VERSION ""

NS_ :

BS_:

BU_: Turbocharger OnBoardDataLogger OffBoardDiagnosticTool2 OffBoardDiagnosticTool1 FileServer ParkingBrakeController SeatControl2 FanDriveController SteeringColumnUnit CommunicationUnitRadio CommunicationUnitSatellite CommunicationUnitCellular PropulsionBatteryCharger ChassisController2 ChassisController1 EngineValveControl AuxiliaryHeater2 AuxiliaryHeater1 ClutchUnit RampControl InformationSystem1 SuspensionSystemController2 OilSensor VehicleDynamicStability ExhaustEmissionController TransmissionDisplay2 TransmissionDisplay1 ClimateControl2 WaterPumpController RearAxleSteeringController LightingOperatorControl SeatController1 IgnitionController2 IgnitionController1 TirePressureController CabController2 CabController1 PneumaticSystemController SuspensionSystemController1 HydraulicPumpController EnduranceBrakingSystem RetarderExhaustEngine2 OnBoardDiagnosticUnit HeadwayController RetarderExhaustEngine1 CabDisplay1 ManagementComputer VirtualTerminal OffVehicleGateway PowerTakeOffFront HitchControl AuxiliaryValveControl BodyController TractorTrailerBridge1 StarterSystem ElectricalSystem VehicleSecurity VehicleNavigation AerodynamicControl ElectricalChargingSystem ClimateControl1 TripRecorder InstrumentCluster SuspensionDriveAxle2 SuspensionDriveAxle1 SuspensionSteerAxle SteeringController FuelSystem CruiseControl RetarderDriveline RetarderEngine BrakesDriveAxle2 BrakesDriveAxle1 BrakesSystemController BrakesSteerAxle AxleDrive2 AxleDrive1 AxleSteering PowerTakeOff ShiftConsoleSecondary ShiftConsolePrimary Transmission2 Transmission1 Engine2 Engine1

BO_ 2566844695 K_CCVS2: 8 Vector__XXX
 SG_ ParkBrakeReleaseInhibitRq : 6|2@1+ (1,0) [0|3] "" Vector__XXX
 SG_ PTOGovernorState : 48|5@1+ (1,0) [0|31] "" Vector__XXX
 SG_ EngShutdownOverrideSwitch : 62|2@1+ (1,0) [0|3] "" Vector__XXX
 SG_ EngTestModeSwitch : 60|2@1+ (1,0) [0|3] "" Vector__XXX
 SG_ EngIdleDecrementSwitch : 58|2@1+ (1,0) [0|3] "" Vector__XXX
 SG_ EngIdleIncrementSwitch : 56|2@1+ (1,0) [0|3] "" Vector__XXX
 SG_ CruiseCtrlStates : 53|3@1+ (1,0) [0|7] "" Vector__XXX
 SG_ CruiseCtrlSetSpeed : 40|8@1+ (1,0) [0|250] "km/h" Vector__XXX
 SG_ CruiseCtrlAccelerateSwitch : 38|2@1+ (1,0) [0|3] "" Vector__XXX
 SG_ CruiseCtrlResumeSwitch : 36|2@1+ (1,0) [0|3] "" Vector__XXX
 SG_ CruiseCtrlCoastSwitch : 34|2@1+ (1,0) [0|3] "" Vector__XXX
 SG_ CruiseCtrlSetSwitch : 32|2@1+ (1,0) [0|3] "" Vector__XXX
 SG_ ClutchSwitch : 30|2@1+ (1,0) [0|3] "" Vector__XXX
 SG_ BrakeSwitch : 28|2@1+ (1,0) [0|3] "" Vector__XXX
 SG_ CruiseCtrlEnableSwitch : 26|2@1+ (1,0) [0|3] "" Vector__XXX
 SG_ CruiseCtrlActive : 24|2@1+ (1,0) [0|3] "" Vector__XXX
 SG_ WheelBasedVehicleSpeed : 8|16@1+ (0.00390625,0) [0|250.996] "km/h" Vector__XXX
 SG_ CruiseCtrlPauseSwitch : 4|2@1+ (1,0) [0|3] "" Vector__XXX
 SG_ ParkingBrakeSwitch : 2|2@1+ (1,0) [0|3] "" Vector__XXX
 SG_ TwoSpeedAxleSwitch : 0|2@1+ (1,0) [0|3] "" Vector__XXX

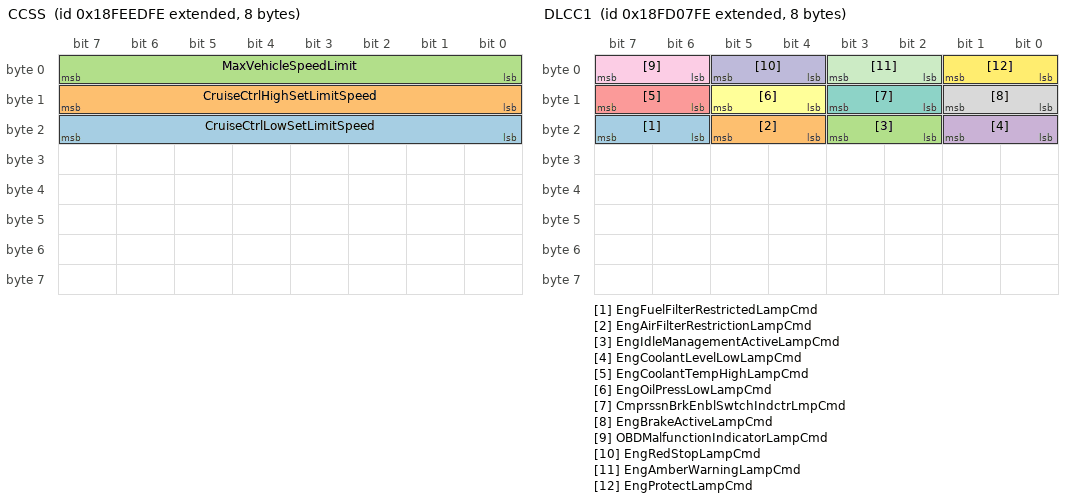
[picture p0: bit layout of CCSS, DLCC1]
BO_ 2566843902 CCSS: 8 Vector__XXX
 SG_ CruiseCtrlLowSetLimitSpeed : 16|8@1+ (1,0) [0|250] "km/h" Vector__XXX
 SG_ CruiseCtrlHighSetLimitSpeed : 8|8@1+ (1,0) [0|250] "km/h" Vector__XXX
 SG_ MaxVehicleSpeedLimit : 0|8@1+ (1,0) [0|250] "km/h" Vector__XXX

BO_ 2566809598 CCC: 8 Vector__XXX
 SG_ AuxHeaterMaxOutputPower : 0|16@1+ (2,0) [0|128510] "W" Vector__XXX

BO_ 2633940222 CBI: 16 Vector__XXX
 SG_ TripServiceBrakeApps : 96|32@1+ (1,0) [0|4227858431] "appl" Vector__XXX
 SG_ TripServiceBrakeDistance : 64|32@1+ (0.125,0) [0|526385151.9] "km" Vector__XXX
 SG_ TripCompressionBrakeDistance : 32|32@1+ (0.125,0) [0|526385151.9] "km" Vector__XXX
 SG_ TotalCompressionBrakeDistance : 0|32@1+ (0.125,0) [0|526385151.9] "km" Vector__XXX

BO_ 2566775294 CACI: 8 Vector__XXX
 SG_ CbA_CRfrgrntCmprssorOutletPress : 0|8@1+ (16,0) [0|4000] "kPa" Vector__XXX

BO_ 2566803710 BT1: 8 Vector__XXX
 SG_ Battery2Temp : 8|8@1+ (1,-40) [-40|210] "deg C" Vector__XXX
 SG_ Battery1Temp : 0|8@1+ (1,-40) [-40|210] "deg C" Vector__XXX

BO_ 2365476881 K_BT1: 8 Vector__XXX
 SG_ Battery2Temp : 8|8@1+ (1,-40) [-40|210] "deg C" Vector__XXX
 SG_ Battery1Temp : 0|8@1+ (1,-40) [-40|210] "deg C" Vector__XXX

BO_ 2566719486 DLCC1: 8 Vector__XXX
 SG_ EngFuelFilterRestrictedLampCmd : 22|2@1+ (1,0) [0|3] "" Vector__XXX
 SG_ EngAirFilterRestrictionLampCmd : 20|2@1+ (1,0) [0|3] "" Vector__XXX
 SG_ EngIdleManagementActiveLampCmd : 18|2@1+ (1,0) [0|3] "" Vector__XXX
 SG_ EngCoolantLevelLowLampCmd : 16|2@1+ (1,0) [0|3] "" Vector__XXX
 SG_ EngCoolantTempHighLampCmd : 14|2@1+ (1,0) [0|3] "" Vector__XXX
 SG_ EngOilPressLowLampCmd : 12|2@1+ (1,0) [0|3] "" Vector__XXX
 SG_ CmprssnBrkEnblSwtchIndctrLmpCmd : 10|2@1+ (1,0) [0|3] "" Vector__XXX
 SG_ EngBrakeActiveLampCmd : 8|2@1+ (1,0) [0|3] "" Vector__XXX
 SG_ OBDMalfunctionIndicatorLampCmd : 6|2@1+ (1,0) [0|3] "" Vector__XXX
 SG_ EngRedStopLampCmd : 4|2@1+ (1,0) [0|3] "" Vector__XXX
 SG_ EngAmberWarningLampCmd : 2|2@1+ (1,0) [0|3] "" Vector__XXX
 SG_ EngProtectLampCmd : 0|2@1+ (1,0) [0|3] "" Vector__XXX

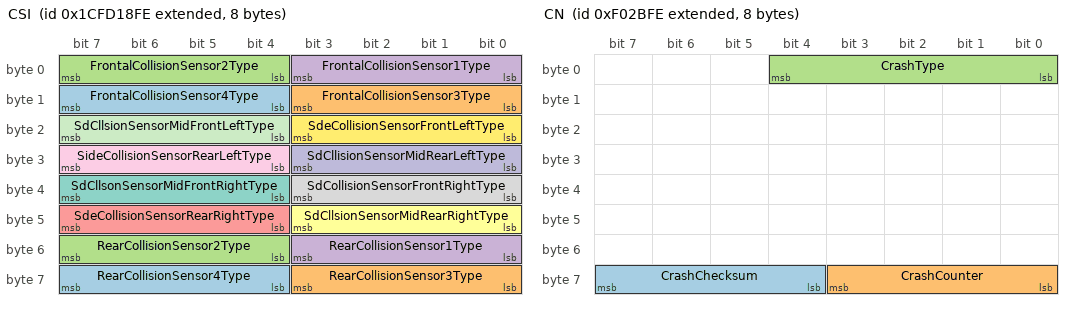
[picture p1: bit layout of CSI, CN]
BO_ 2633832702 CSI: 8 Vector__XXX
 SG_ RearCollisionSensor4Type : 60|4@1+ (1,0) [0|15] "" Vector__XXX
 SG_ RearCollisionSensor3Type : 56|4@1+ (1,0) [0|15] "" Vector__XXX
 SG_ RearCollisionSensor2Type : 52|4@1+ (1,0) [0|15] "" Vector__XXX
 SG_ RearCollisionSensor1Type : 48|4@1+ (1,0) [0|15] "" Vector__XXX
 SG_ SdeCollisionSensorRearRightType : 44|4@1+ (1,0) [0|15] "" Vector__XXX
 SG_ SdCllsionSensorMidRearRightType : 40|4@1+ (1,0) [0|15] "" Vector__XXX
 SG_ SdCllsonSensorMidFrontRightType : 36|4@1+ (1,0) [0|15] "" Vector__XXX
 SG_ SdCollisionSensorFrontRightType : 32|4@1+ (1,0) [0|15] "" Vector__XXX
 SG_ SideCollisionSensorRearLeftType : 28|4@1+ (1,0) [0|15] "" Vector__XXX
 SG_ SdCllisionSensorMidRearLeftType : 24|4@1+ (1,0) [0|15] "" Vector__XXX
 SG_ SdCllsionSensorMidFrontLeftType : 20|4@1+ (1,0) [0|15] "" Vector__XXX
 SG_ SdeCollisionSensorFrontLeftType : 16|4@1+ (1,0) [0|15] "" Vector__XXX
 SG_ FrontalCollisionSensor4Type : 12|4@1+ (1,0) [0|15] "" Vector__XXX
 SG_ FrontalCollisionSensor3Type : 8|4@1+ (1,0) [0|15] "" Vector__XXX
 SG_ FrontalCollisionSensor2Type : 4|4@1+ (1,0) [0|15] "" Vector__XXX
 SG_ FrontalCollisionSensor1Type : 0|4@1+ (1,0) [0|15] "" Vector__XXX

BO_ 2163223550 CN: 8 Vector__XXX
 SG_ CrashChecksum : 60|4@1+ (1,0) [0|15] "" Vector__XXX
 SG_ CrashCounter : 56|4@1+ (1,0) [0|15] "" Vector__XXX
 SG_ CrashType : 0|5@1+ (5,0) [0|0] "" Vector__XXX

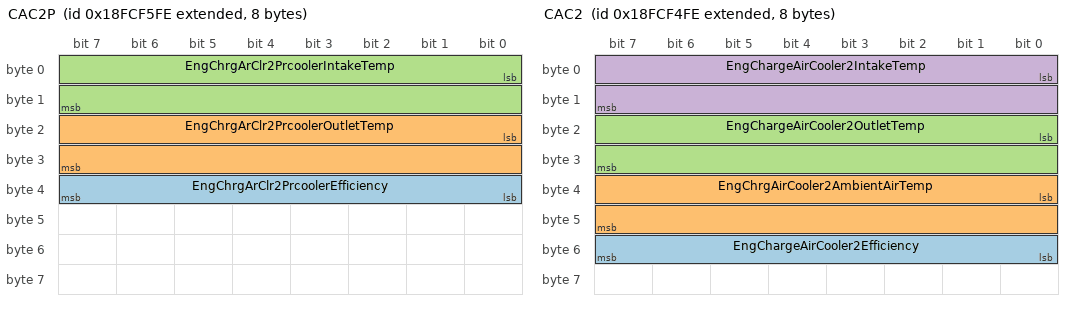
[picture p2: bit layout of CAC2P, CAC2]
BO_ 2566714878 CAC2P: 8 Vector__XXX
 SG_ EngChrgArClr2PrcoolerEfficiency : 32|8@1+ (0.4,0) [0|100] "%" Vector__XXX
 SG_ EngChrgArClr2PrcoolerOutletTemp : 16|16@1+ (0.03125,-273) [-273|1734.96875] "deg C" Vector__XXX
 SG_ EngChrgArClr2PrcoolerIntakeTemp : 0|16@1+ (0.03125,-273) [-273|1734.96875] "deg C" Vector__XXX

BO_ 2566714622 CAC2: 8 Vector__XXX
 SG_ EngChargeAirCooler2Efficiency : 48|8@1+ (0.4,0) [0|100] "%" Vector__XXX
 SG_ EngChrgAirCooler2AmbientAirTemp : 32|16@1+ (0.03125,-273) [-273|1734.96875] "deg C" Vector__XXX
 SG_ EngChargeAirCooler2OutletTemp : 16|16@1+ (0.03125,-273) [-273|1734.96875] "deg C" Vector__XXX
 SG_ EngChargeAirCooler2IntakeTemp : 0|16@1+ (0.03125,-273) [-273|1734.96875] "deg C" Vector__XXX

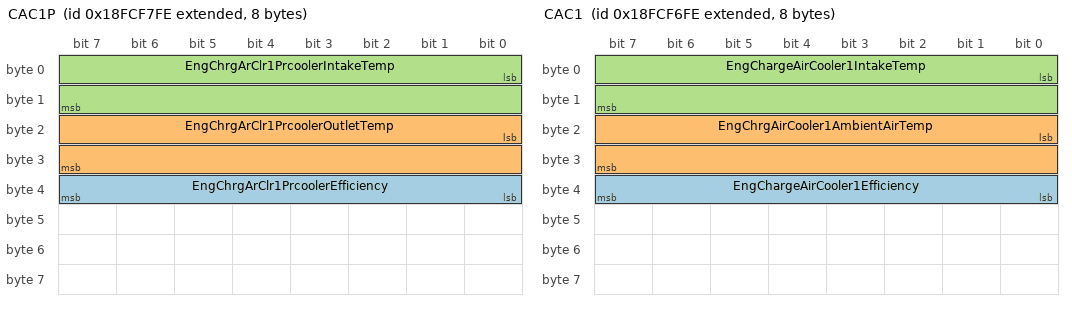
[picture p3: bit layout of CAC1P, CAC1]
BO_ 2566715390 CAC1P: 8 Vector__XXX
 SG_ EngChrgArClr1PrcoolerEfficiency : 32|8@1+ (0.4,0) [0|100] "%" Vector__XXX
 SG_ EngChrgArClr1PrcoolerOutletTemp : 16|16@1+ (0.03125,-273) [-273|1734.96875] "deg C" Vector__XXX
 SG_ EngChrgArClr1PrcoolerIntakeTemp : 0|16@1+ (0.03125,-273) [-273|1734.96875] "deg C" Vector__XXX

BO_ 2566715134 CAC1: 8 Vector__XXX
 SG_ EngChargeAirCooler1Efficiency : 32|8@1+ (0.4,0) [0|100] "%" Vector__XXX
 SG_ EngChrgAirCooler1AmbientAirTemp : 16|16@1+ (0.03125,-273) [-273|1734.96875] "deg C" Vector__XXX
 SG_ EngChargeAirCooler1IntakeTemp : 0|16@1+ (0.03125,-273) [-273|1734.96875] "deg C" Vector__XXX

BO_ 2365400830 BJM9: 8 Vector__XXX
 SG_ Joystick9Button9PressedStatus : 62|2@1+ (1,0) [0|3] "" Vector__XXX
 SG_ Joystick9Button10PressedStatus : 60|2@1+ (1,0) [0|3] "" Vector__XXX
 SG_ Joystick9Button11PressedStatus : 58|2@1+ (1,0) [0|3] "" Vector__XXX
 SG_ Joystick9Button12PressedStatus : 56|2@1+ (1,0) [0|3] "" Vector__XXX
 SG_ Joystick9Button5PressedStatus : 54|2@1+ (1,0) [0|3] "" Vector__XXX
 SG_ Joystick9Button6PressedStatus : 52|2@1+ (1,0) [0|3] "" Vector__XXX
 SG_ Joystick9Button7PressedStatus : 50|2@1+ (1,0) [0|3] "" Vector__XXX
 SG_ Joystick9Button8PressedStatus : 48|2@1+ (1,0) [0|3] "" Vector__XXX
 SG_ Joystick9Button1PressedStatus : 46|2@1+ (1,0) [0|3] "" Vector__XXX
 SG_ Joystick9Button2PressedStatus : 44|2@1+ (1,0) [0|3] "" Vector__XXX
 SG_ Joystick9Button3PressedStatus : 42|2@1+ (1,0) [0|3] "" Vector__XXX
 SG_ Joystick9Button4PressedStatus : 40|2@1+ (1,0) [0|3] "" Vector__XXX
 SG_ Joystick9XAxisDetentPosStatus : 38|2@1+ (1,0) [0|3] "" Vector__XXX
 SG_ Joystick9YAxisDetentPosStatus : 36|2@1+ (1,0) [0|3] "" Vector__XXX
 SG_ Joystick9YAxisPos : 22|10@1+ (0.1,0) [0|102] "%" Vector__XXX
 SG_ Jystck9YAxsLvrFrwrdPstvPsStatus : 20|2@1+ (1,0) [0|3] "" Vector__XXX
 SG_ Jystck9YAxsLvrBckNgtvePosStatus : 18|2@1+ (1,0) [0|3] "" Vector__XXX
 SG_ Joystick9YAxisNeutralPosStatus : 16|2@1+ (1,0) [0|3] "" Vector__XXX
 SG_ Joystick9XAxisPos : 6|10@1+ (0.1,0) [0|102] "%" Vector__XXX
 SG_ Jystck9XAxsLvrRghtPstvPosStatus : 4|2@1+ (1,0) [0|3] "" Vector__XXX
 SG_ Jystck9XAxsLvrLftNgtvePosStatus : 2|2@1+ (1,0) [0|3] "" Vector__XXX
 SG_ Joystick9XAxisNeutralPosStatus : 0|2@1+ (1,0) [0|3] "" Vector__XXX

BO_ 2365401342 BJM8: 8 Vector__XXX
 SG_ Joystick8Button9PressedStatus : 62|2@1+ (1,0) [0|3] "" Vector__XXX
 SG_ Joystick8Button10PressedStatus : 60|2@1+ (1,0) [0|3] "" Vector__XXX
 SG_ Joystick8Button11PressedStatus : 58|2@1+ (1,0) [0|3] "" Vector__XXX
 SG_ Joystick8Button12PressedStatus : 56|2@1+ (1,0) [0|3] "" Vector__XXX
 SG_ Joystick8Button5PressedStatus : 54|2@1+ (1,0) [0|3] "" Vector__XXX
 SG_ Joystick8Button6PressedStatus : 52|2@1+ (1,0) [0|3] "" Vector__XXX
 SG_ Joystick8Button7PressedStatus : 50|2@1+ (1,0) [0|3] "" Vector__XXX
 SG_ Joystick8Button8PressedStatus : 48|2@1+ (1,0) [0|3] "" Vector__XXX
 SG_ Joystick8Button1PressedStatus : 46|2@1+ (1,0) [0|3] "" Vector__XXX
 SG_ Joystick8Button2PressedStatus : 44|2@1+ (1,0) [0|3] "" Vector__XXX
 SG_ Joystick8Button3PressedStatus : 42|2@1+ (1,0) [0|3] "" Vector__XXX
 SG_ Joystick8Button4PressedStatus : 40|2@1+ (1,0) [0|3] "" Vector__XXX
 SG_ Joystick8XAxisDetentPosStatus : 38|2@1+ (1,0) [0|3] "" Vector__XXX
 SG_ Joystick8YAxisDetentPosStatus : 36|2@1+ (1,0) [0|3] "" Vector__XXX
 SG_ Joystick8YAxisPos : 22|10@1+ (0.1,0) [0|102] "%" Vector__XXX
 SG_ Jystck8YAxsLvrFrwrdPstvPsStatus : 20|2@1+ (1,0) [0|3] "" Vector__XXX
 SG_ Jystck8YAxsLvrBckNgtvePosStatus : 18|2@1+ (1,0) [0|3] "" Vector__XXX
 SG_ Joystick8YAxisNeutralPosStatus : 16|2@1+ (1,0) [0|3] "" Vector__XXX
 SG_ Joystick8XAxisPos : 6|10@1+ (0.1,0) [0|102] "%" Vector__XXX
 SG_ Jystck8XAxsLvrRghtPstvPosStatus : 4|2@1+ (1,0) [0|3] "" Vector__XXX
 SG_ Jystck8XAxsLvrLftNgtvePosStatus : 2|2@1+ (1,0) [0|3] "" Vector__XXX
 SG_ Joystick8XAxisNeutralPosStatus : 0|2@1+ (1,0) [0|3] "" Vector__XXX

BO_ 2365401854 BJM7: 8 Vector__XXX
 SG_ Joystick7Button9PressedStatus : 62|2@1+ (1,0) [0|3] "" Vector__XXX
 SG_ Joystick7Button10PressedStatus : 60|2@1+ (1,0) [0|3] "" Vector__XXX
 SG_ Joystick7Button11PressedStatus : 58|2@1+ (1,0) [0|3] "" Vector__XXX
 SG_ Joystick7Button12PressedStatus : 56|2@1+ (1,0) [0|3] "" Vector__XXX
 SG_ Joystick7Button5PressedStatus : 54|2@1+ (1,0) [0|3] "" Vector__XXX
 SG_ Joystick7Button6PressedStatus : 52|2@1+ (1,0) [0|3] "" Vector__XXX
 SG_ Joystick7Button7PressedStatus : 50|2@1+ (1,0) [0|3] "" Vector__XXX
 SG_ Joystick7Button8PressedStatus : 48|2@1+ (1,0) [0|3] "" Vector__XXX
 SG_ Joystick7Button1PressedStatus : 46|2@1+ (1,0) [0|3] "" Vector__XXX
 SG_ Joystick7Button2PressedStatus : 44|2@1+ (1,0) [0|3] "" Vector__XXX
 SG_ Joystick7Button3PressedStatus : 42|2@1+ (1,0) [0|3] "" Vector__XXX
 SG_ Joystick7Button4PressedStatus : 40|2@1+ (1,0) [0|3] "" Vector__XXX
 SG_ Joystick7XAxisDetentPosStatus : 38|2@1+ (1,0) [0|3] "" Vector__XXX
 SG_ Joystick7YAxisDetentPosStatus : 36|2@1+ (1,0) [0|3] "" Vector__XXX
 SG_ Joystick7YAxisPos : 22|10@1+ (0.1,0) [0|102] "%" Vector__XXX
 SG_ Jystck7YAxsLvrFrwrdPstvPsStatus : 20|2@1+ (1,0) [0|3] "" Vector__XXX
 SG_ Jystck7YAxsLvrBckNgtvePosStatus : 18|2@1+ (1,0) [0|3] "" Vector__XXX
 SG_ Joystick7YAxisNeutralPosStatus : 16|2@1+ (1,0) [0|3] "" Vector__XXX
 SG_ Joystick7XAxisPos : 6|10@1+ (0.1,0) [0|102] "%" Vector__XXX
 SG_ Jystck7XAxsLvrRghtPstvPosStatus : 4|2@1+ (1,0) [0|3] "" Vector__XXX
 SG_ Jystck7XAxsLvrLftNgtvePosStatus : 2|2@1+ (1,0) [0|3] "" Vector__XXX
 SG_ Joystick7XAxisNeutralPosStatus : 0|2@1+ (1,0) [0|3] "" Vector__XXX

BO_ 2365402366 BJM6: 8 Vector__XXX
 SG_ Joystick6Button9PressedStatus : 62|2@1+ (1,0) [0|3] "" Vector__XXX
 SG_ Joystick6Button10PressedStatus : 60|2@1+ (1,0) [0|3] "" Vector__XXX
 SG_ Joystick6Button11PressedStatus : 58|2@1+ (1,0) [0|3] "" Vector__XXX
 SG_ Joystick6Button12PressedStatus : 56|2@1+ (1,0) [0|3] "" Vector__XXX
 SG_ Joystick6Button5PressedStatus : 54|2@1+ (1,0) [0|3] "" Vector__XXX
 SG_ Joystick6Button6PressedStatus : 52|2@1+ (1,0) [0|3] "" Vector__XXX
 SG_ Joystick6Button7PressedStatus : 50|2@1+ (1,0) [0|3] "" Vector__XXX
 SG_ Joystick6Button8PressedStatus : 48|2@1+ (1,0) [0|3] "" Vector__XXX
 SG_ Joystick6Button1PressedStatus : 46|2@1+ (1,0) [0|3] "" Vector__XXX
 SG_ Joystick6Button2PressedStatus : 44|2@1+ (1,0) [0|3] "" Vector__XXX
 SG_ Joystick6Button3PressedStatus : 42|2@1+ (1,0) [0|3] "" Vector__XXX
 SG_ Joystick6Button4PressedStatus : 40|2@1+ (1,0) [0|3] "" Vector__XXX
 SG_ Joystick6XAxisDetentPosStatus : 38|2@1+ (1,0) [0|3] "" Vector__XXX
 SG_ Joystick6YAxisDetentPosStatus : 36|2@1+ (1,0) [0|3] "" Vector__XXX
 SG_ Joystick6YAxisPos : 22|10@1+ (0.1,0) [0|102] "%" Vector__XXX
 SG_ Jystck6YAxsLvrFrwrdPstvPsStatus : 20|2@1+ (1,0) [0|3] "" Vector__XXX
 SG_ Jystck6YAxsLvrBckNgtvePosStatus : 18|2@1+ (1,0) [0|3] "" Vector__XXX
 SG_ Joystick6YAxisNeutralPosStatus : 16|2@1+ (1,0) [0|3] "" Vector__XXX
 SG_ Joystick6XAxisPos : 6|10@1+ (0.1,0) [0|102] "%" Vector__XXX
 SG_ Jystck6XAxsLvrRghtPstvPosStatus : 4|2@1+ (1,0) [0|3] "" Vector__XXX
 SG_ Jystck6XAxsLvrLftNgtvePosStatus : 2|2@1+ (1,0) [0|3] "" Vector__XXX
 SG_ Joystick6XAxisNeutralPosStatus : 0|2@1+ (1,0) [0|3] "" Vector__XXX

BO_ 2365402878 BJM5: 8 Vector__XXX
 SG_ Joystick5Button9PressedStatus : 62|2@1+ (1,0) [0|3] "" Vector__XXX
 SG_ Joystick5Button10PressedStatus : 60|2@1+ (1,0) [0|3] "" Vector__XXX
 SG_ Joystick5Button11PressedStatus : 58|2@1+ (1,0) [0|3] "" Vector__XXX
 SG_ Joystick5Button12PressedStatus : 56|2@1+ (1,0) [0|3] "" Vector__XXX
 SG_ Joystick5Button5PressedStatus : 54|2@1+ (1,0) [0|3] "" Vector__XXX
 SG_ Joystick5Button6PressedStatus : 52|2@1+ (1,0) [0|3] "" Vector__XXX
 SG_ Joystick5Button7PressedStatus : 50|2@1+ (1,0) [0|3] "" Vector__XXX
 SG_ Joystick5Button8PressedStatus : 48|2@1+ (1,0) [0|3] "" Vector__XXX
 SG_ Joystick5Button1PressedStatus : 46|2@1+ (1,0) [0|3] "" Vector__XXX
 SG_ Joystick5Button2PressedStatus : 44|2@1+ (1,0) [0|3] "" Vector__XXX
 SG_ Joystick5Button3PressedStatus : 42|2@1+ (1,0) [0|3] "" Vector__XXX
 SG_ Joystick5Button4PressedStatus : 40|2@1+ (1,0) [0|3] "" Vector__XXX
 SG_ Joystick5XAxisDetentPosStatus : 38|2@1+ (1,0) [0|3] "" Vector__XXX
 SG_ Joystick5YAxisDetentPosStatus : 36|2@1+ (1,0) [0|3] "" Vector__XXX
 SG_ Joystick5YAxisPos : 22|10@1+ (0.1,0) [0|102] "%" Vector__XXX
 SG_ Jystck5YAxsLvrFrwrdPstvPsStatus : 20|2@1+ (1,0) [0|3] "" Vector__XXX
 SG_ Jystck5YAxsLvrBckNgtvePosStatus : 18|2@1+ (1,0) [0|3] "" Vector__XXX
 SG_ Joystick5YAxisNeutralPosStatus : 16|2@1+ (1,0) [0|3] "" Vector__XXX
 SG_ Joystick5XAxisPos : 6|10@1+ (0.1,0) [0|102] "%" Vector__XXX
 SG_ Jystck5XAxsLvrRghtPstvPosStatus : 4|2@1+ (1,0) [0|3] "" Vector__XXX
 SG_ Jystck5XAxsLvrLftNgtvePosStatus : 2|2@1+ (1,0) [0|3] "" Vector__XXX
 SG_ Joystick5XAxisNeutralPosStatus : 0|2@1+ (1,0) [0|3] "" Vector__XXX

BO_ 2365403390 BJM4: 8 Vector__XXX
 SG_ Joystick4Button9PressedStatus : 62|2@1+ (1,0) [0|3] "" Vector__XXX
 SG_ Joystick4Button10PressedStatus : 60|2@1+ (1,0) [0|3] "" Vector__XXX
 SG_ Joystick4Button11PressedStatus : 58|2@1+ (1,0) [0|3] "" Vector__XXX
 SG_ Joystick4Button12PressedStatus : 56|2@1+ (1,0) [0|3] "" Vector__XXX
 SG_ Joystick4Button5PressedStatus : 54|2@1+ (1,0) [0|3] "" Vector__XXX
 SG_ Joystick4Button6PressedStatus : 52|2@1+ (1,0) [0|3] "" Vector__XXX
 SG_ Joystick4Button7PressedStatus : 50|2@1+ (1,0) [0|3] "" Vector__XXX
 SG_ Joystick4Button8PressedStatus : 48|2@1+ (1,0) [0|3] "" Vector__XXX
 SG_ Joystick4Button1PressedStatus : 46|2@1+ (1,0) [0|3] "" Vector__XXX
 SG_ Joystick4Button2PressedStatus : 44|2@1+ (1,0) [0|3] "" Vector__XXX
 SG_ Joystick4Button3PressedStatus : 42|2@1+ (1,0) [0|3] "" Vector__XXX
 SG_ Joystick4Button4PressedStatus : 40|2@1+ (1,0) [0|3] "" Vector__XXX
 SG_ Joystick4XAxisDetentPosStatus : 38|2@1+ (1,0) [0|3] "" Vector__XXX
 SG_ Joystick4YAxisDetentPosStatus : 36|2@1+ (1,0) [0|3] "" Vector__XXX
 SG_ Joystick4YAxisPos : 22|10@1+ (0.1,0) [0|102] "%" Vector__XXX
 SG_ Jystck4YAxsLvrFrwrdPstvPsStatus : 20|2@1+ (1,0) [0|3] "" Vector__XXX
 SG_ Jystck4YAxsLvrBckNgtvePosStatus : 18|2@1+ (1,0) [0|3] "" Vector__XXX
 SG_ Joystick4YAxisNeutralPosStatus : 16|2@1+ (1,0) [0|3] "" Vector__XXX
 SG_ Joystick4XAxisPos : 6|10@1+ (0.1,0) [0|102] "%" Vector__XXX
 SG_ Jystck4XAxsLvrRghtPstvPosStatus : 4|2@1+ (1,0) [0|3] "" Vector__XXX
 SG_ Jystck4XAxsLvrLftNgtvePosStatus : 2|2@1+ (1,0) [0|3] "" Vector__XXX
 SG_ Joystick4XAxisNeutralPosStatus : 0|2@1+ (1,0) [0|3] "" Vector__XXX

BO_ 2365400318 BJM10: 8 Vector__XXX
 SG_ Joystick10Button9PressedStatus : 62|2@1+ (1,0) [0|3] "" Vector__XXX
 SG_ Joystick10Button10PressedStatus : 60|2@1+ (1,0) [0|3] "" Vector__XXX
 SG_ Joystick10Button11PressedStatus : 58|2@1+ (1,0) [0|3] "" Vector__XXX
 SG_ Joystick10Button12PressedStatus : 56|2@1+ (1,0) [0|3] "" Vector__XXX
 SG_ Joystick10Button5PressedStatus : 54|2@1+ (1,0) [0|3] "" Vector__XXX
 SG_ Joystick10Button6PressedStatus : 52|2@1+ (1,0) [0|3] "" Vector__XXX
 SG_ Joystick10Button7PressedStatus : 50|2@1+ (1,0) [0|3] "" Vector__XXX
 SG_ Joystick10Button8PressedStatus : 48|2@1+ (1,0) [0|3] "" Vector__XXX
 SG_ Joystick10Button1PressedStatus : 46|2@1+ (1,0) [0|3] "" Vector__XXX
 SG_ Joystick10Button2PressedStatus : 44|2@1+ (1,0) [0|3] "" Vector__XXX
 SG_ Joystick10Button3PressedStatus : 42|2@1+ (1,0) [0|3] "" Vector__XXX
 SG_ Joystick10Button4PressedStatus : 40|2@1+ (1,0) [0|3] "" Vector__XXX
 SG_ Joystick10XAxisDetentPosStatus : 38|2@1+ (1,0) [0|3] "" Vector__XXX
 SG_ Joystick10YAxisDetentPosStatus : 36|2@1+ (1,0) [0|3] "" Vector__XXX
 SG_ Joystick10YAxisPos : 22|10@1+ (0.1,0) [0|102] "%" Vector__XXX
 SG_ Jystck10YAxsLvrFrwrdPstvPsSttus : 20|2@1+ (1,0) [0|3] "" Vector__XXX
 SG_ Jystck10YAxsLvrBckNgtvPosStatus : 18|2@1+ (1,0) [0|3] "" Vector__XXX
 SG_ Joystick10YAxisNeutralPosStatus : 16|2@1+ (1,0) [0|3] "" Vector__XXX
 SG_ Joystick10XAxisPos : 6|10@1+ (0.1,0) [0|102] "%" Vector__XXX
 SG_ Jystck10XAxsLvrRghtPstvPsStatus : 4|2@1+ (1,0) [0|3] "" Vector__XXX
 SG_ Jystck10XAxsLvrLftNgtvPosStatus : 2|2@1+ (1,0) [0|3] "" Vector__XXX
 SG_ Joystick10XAxisNeutralPosStatus : 0|2@1+ (1,0) [0|3] "" Vector__XXX

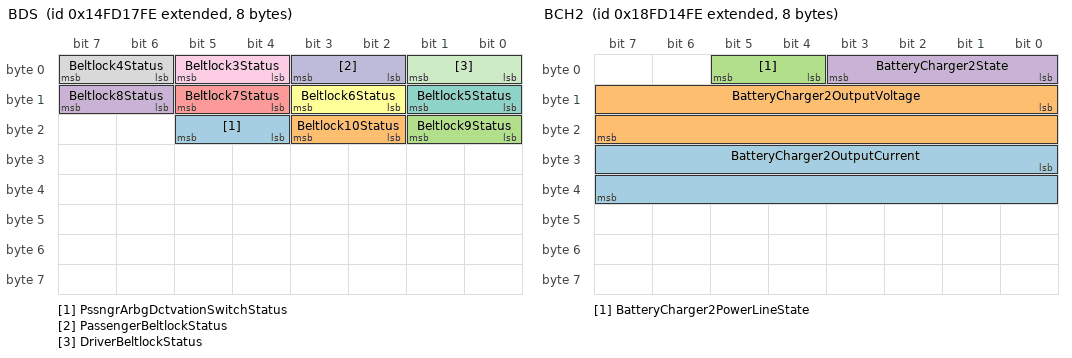
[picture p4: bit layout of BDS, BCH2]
BO_ 2499614718 BDS: 8 Vector__XXX
 SG_ PssngrArbgDctvationSwitchStatus : 20|2@1+ (1,0) [0|3] "" Vector__XXX
 SG_ Beltlock10Status : 18|2@1+ (1,0) [0|3] "" Vector__XXX
 SG_ Beltlock9Status : 16|2@1+ (1,0) [0|3] "" Vector__XXX
 SG_ Beltlock8Status : 14|2@1+ (1,0) [0|3] "" Vector__XXX
 SG_ Beltlock7Status : 12|2@1+ (1,0) [0|3] "" Vector__XXX
 SG_ Beltlock6Status : 10|2@1+ (1,0) [0|3] "" Vector__XXX
 SG_ Beltlock5Status : 8|2@1+ (1,0) [0|3] "" Vector__XXX
 SG_ Beltlock4Status : 6|2@1+ (1,0) [0|3] "" Vector__XXX
 SG_ Beltlock3Status : 4|2@1+ (1,0) [0|3] "" Vector__XXX
 SG_ PassengerBeltlockStatus : 2|2@1+ (1,0) [0|3] "" Vector__XXX
 SG_ DriverBeltlockStatus : 0|2@1+ (1,0) [0|3] "" Vector__XXX

BO_ 2566722814 BCH2: 8 Vector__XXX
 SG_ BatteryCharger2OutputCurrent : 24|16@1+ (0.05,-1600) [-1600|1612.75] "A" Vector__XXX
 SG_ BatteryCharger2OutputVoltage : 8|16@1+ (0.05,0) [0|3212.75] "V" Vector__XXX
 SG_ BatteryCharger2PowerLineState : 4|2@1+ (1,0) [0|3] "" Vector__XXX
 SG_ BatteryCharger2State : 0|4@1+ (1,0) [0|15] "" Vector__XXX

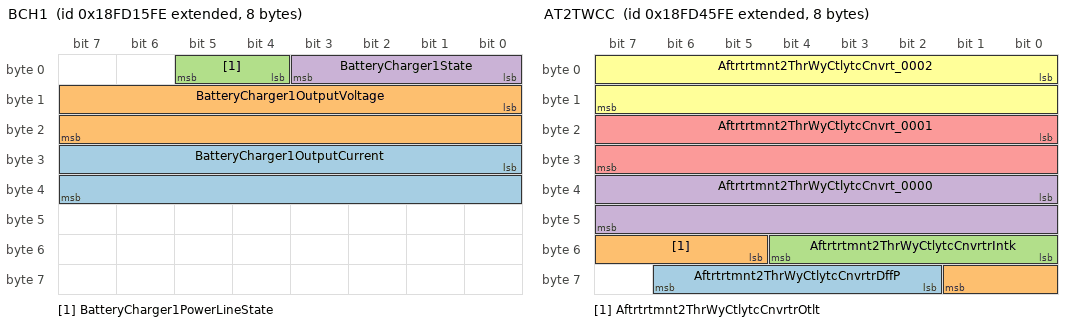
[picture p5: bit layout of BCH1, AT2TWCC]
BO_ 2566723070 BCH1: 8 Vector__XXX
 SG_ BatteryCharger1OutputCurrent : 24|16@1+ (0.05,-1600) [-1600|1612.75] "A" Vector__XXX
 SG_ BatteryCharger1OutputVoltage : 8|16@1+ (0.05,0) [0|3212.75] "V" Vector__XXX
 SG_ BatteryCharger1PowerLineState : 4|2@1+ (1,0) [0|3] "" Vector__XXX
 SG_ BatteryCharger1State : 0|4@1+ (1,0) [0|15] "" Vector__XXX

BO_ 2566725118 ATDT2: 8 Vector__XXX
 SG_ Aftrtrtmnt2ThrWyCtlystDffGsTemp : 16|16@1+ (0.03125,-273) [-273|1734.96875] "deg C" Vector__XXX
 SG_ Aftrtrtmnt1ThrWyCtlystDffGsTemp : 0|16@1+ (0.03125,-273) [-273|1734.96875] "deg C" Vector__XXX

BO_ 2566725374 ATDT1: 8 Vector__XXX
 SG_ Aftrtrtmnt2GsOxdtnCtlystDffGsTmp : 16|16@1+ (0.03125,-273) [-273|1734.96875] "deg C" Vector__XXX
 SG_ Aftrtrtmnt1GsOxdtnCtlystDffGsTmp : 0|16@1+ (0.03125,-273) [-273|1734.96875] "deg C" Vector__XXX

BO_ 2566712830 AT2WUDOC: 8 Vector__XXX
 SG_ Aftrtrtmnt2WrmUpDslOxdtnCtlystOt : 16|16@1+ (0.03125,-273) [-273|1734.96875] "deg C" Vector__XXX
 SG_ Aftrtrtmnt2WrmUpDslOxdtnCtlystIn : 0|16@1+ (0.03125,-273) [-273|1734.96875] "deg C" Vector__XXX

BO_ 2566735358 AT2TWCC: 8 Vector__XXX
 SG_ Aftrtrtmnt2ThrWyCtlytcCnvrtrDffP : 58|5@1+ (1,0) [0|31] "" Vector__XXX
 SG_ Aftrtrtmnt2ThrWyCtlytcCnvrtrOtlt : 53|5@1+ (1,0) [0|31] "" Vector__XXX
 SG_ Aftrtrtmnt2ThrWyCtlytcCnvrtrIntk : 48|5@1+ (1,0) [0|31] "" Vector__XXX
 SG_ Aftrtrtmnt2ThrWyCtlytcCnvrt_0000 : 32|16@1+ (0.1,0) [0|6425.5] "kPa" Vector__XXX
 SG_ Aftrtrtmnt2ThrWyCtlytcCnvrt_0001 : 16|16@1+ (0.03125,-273) [-273|1734.96875] "deg C" Vector__XXX
 SG_ Aftrtrtmnt2ThrWyCtlytcCnvrt_0002 : 0|16@1+ (0.03125,-273) [-273|1734.96875] "deg C" Vector__XXX

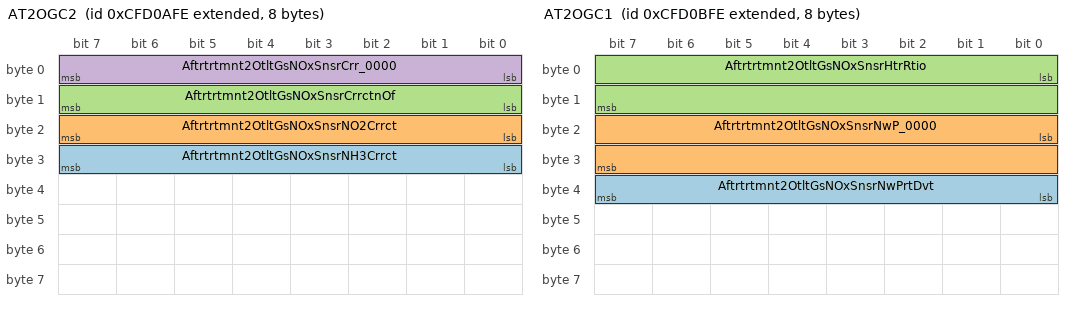
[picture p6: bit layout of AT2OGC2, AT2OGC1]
BO_ 2365393662 AT2OGC2: 8 Vector__XXX
 SG_ Aftrtrtmnt2OtltGsNOxSnsrNH3Crrct : 24|8@1+ (0.5,0) [0|125] "%" Vector__XXX
 SG_ Aftrtrtmnt2OtltGsNOxSnsrNO2Crrct : 16|8@1+ (0.5,0) [0|125] "%" Vector__XXX
 SG_ Aftrtrtmnt2OtltGsNOxSnsrCrrctnOf : 8|8@1+ (0.5,0) [0|125] "%/bar" Vector__XXX
 SG_ Aftrtrtmnt2OtltGsNOxSnsrCrr_0000 : 0|8@1+ (0.5,0) [0|125] "%/bar" Vector__XXX

BO_ 2365393918 AT2OGC1: 8 Vector__XXX
 SG_ Aftrtrtmnt2OtltGsNOxSnsrNwPrtDvt : 32|8@1+ (1,-125) [-125|125] "ppm" Vector__XXX
 SG_ Aftrtrtmnt2OtltGsNOxSnsrNwP_0000 : 16|16@1+ (0.1,-100) [-100|100] "%" Vector__XXX
 SG_ Aftrtrtmnt2OtltGsNOxSnsrHtrRtio : 0|16@1+ (0.001,0) [0|64.255] "" Vector__XXX

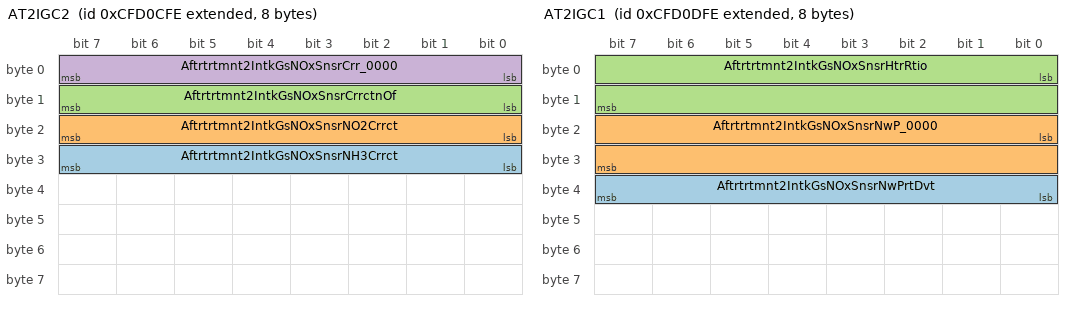
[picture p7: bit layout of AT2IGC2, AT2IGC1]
BO_ 2365394174 AT2IGC2: 8 Vector__XXX
 SG_ Aftrtrtmnt2IntkGsNOxSnsrNH3Crrct : 24|8@1+ (0.5,0) [0|125] "%" Vector__XXX
 SG_ Aftrtrtmnt2IntkGsNOxSnsrNO2Crrct : 16|8@1+ (0.5,0) [0|125] "%" Vector__XXX
 SG_ Aftrtrtmnt2IntkGsNOxSnsrCrrctnOf : 8|8@1+ (0.5,0) [0|125] "%/bar" Vector__XXX
 SG_ Aftrtrtmnt2IntkGsNOxSnsrCrr_0000 : 0|8@1+ (0.5,0) [0|125] "%/bar" Vector__XXX

BO_ 2365394430 AT2IGC1: 8 Vector__XXX
 SG_ Aftrtrtmnt2IntkGsNOxSnsrNwPrtDvt : 32|8@1+ (1,-125) [-125|125] "ppm" Vector__XXX
 SG_ Aftrtrtmnt2IntkGsNOxSnsrNwP_0000 : 16|16@1+ (0.1,-100) [-100|100] "%" Vector__XXX
 SG_ Aftrtrtmnt2IntkGsNOxSnsrHtrRtio : 0|16@1+ (0.001,0) [0|64.255] "" Vector__XXX

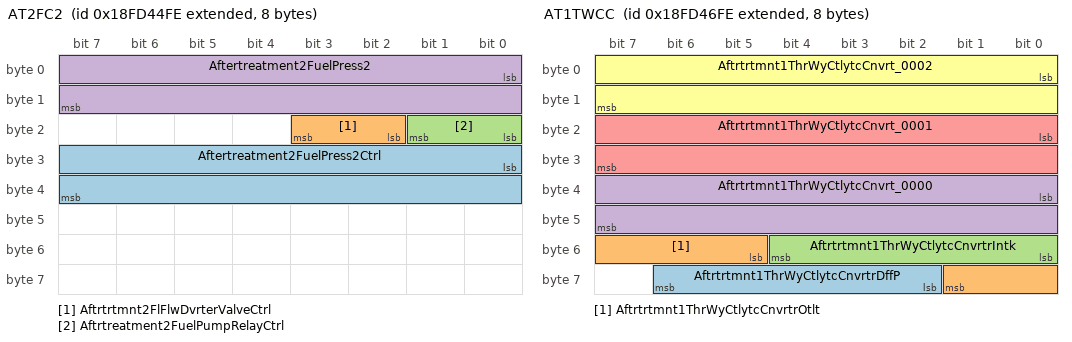
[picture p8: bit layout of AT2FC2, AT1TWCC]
BO_ 2566735102 AT2FC2: 8 Vector__XXX
 SG_ Aftertreatment2FuelPress2Ctrl : 24|16@1+ (0.0025,0) [0|160.6375] "%" Vector__XXX
 SG_ Aftrtrtmnt2FlFlwDvrterValveCtrl : 18|2@1+ (1,0) [0|3] "" Vector__XXX
 SG_ Aftrtreatment2FuelPumpRelayCtrl : 16|2@1+ (1,0) [0|3] "" Vector__XXX
 SG_ Aftertreatment2FuelPress2 : 0|16@1+ (0.1,0) [0|6425.5] "kPa" Vector__XXX

BO_ 2157313790 AT2DPFSSC: 8 Vector__XXX
 SG_ Aftrtrtmnt2DslPrtcltFltrStStndrd : 16|16@1+ (0.0025,0) [0|160.6375] "%" Vector__XXX
 SG_ Aftrtrtmnt2DslPrtcltFltrStMnClbO : 0|16@1+ (0.0025,0) [0|160.6375] "%" Vector__XXX

BO_ 2566724350 AT1WUDOC: 8 Vector__XXX
 SG_ Aftrtrtmnt1WrmUpDslOxdtnCtlystOt : 16|16@1+ (0.03125,-273) [-273|1734.96875] "deg C" Vector__XXX
 SG_ Aftrtrtmnt1WrmUpDslOxdtnCtlystIn : 0|16@1+ (0.03125,-273) [-273|1734.96875] "deg C" Vector__XXX

BO_ 2566735614 AT1TWCC: 8 Vector__XXX
 SG_ Aftrtrtmnt1ThrWyCtlytcCnvrtrDffP : 58|5@1+ (1,0) [0|31] "" Vector__XXX
 SG_ Aftrtrtmnt1ThrWyCtlytcCnvrtrOtlt : 53|5@1+ (1,0) [0|31] "" Vector__XXX
 SG_ Aftrtrtmnt1ThrWyCtlytcCnvrtrIntk : 48|5@1+ (1,0) [0|31] "" Vector__XXX
 SG_ Aftrtrtmnt1ThrWyCtlytcCnvrt_0000 : 32|16@1+ (0.1,0) [0|6425.5] "kPa" Vector__XXX
 SG_ Aftrtrtmnt1ThrWyCtlytcCnvrt_0001 : 16|16@1+ (0.03125,-273) [-273|1734.96875] "deg C" Vector__XXX
 SG_ Aftrtrtmnt1ThrWyCtlytcCnvrt_0002 : 0|16@1+ (0.03125,-273) [-273|1734.96875] "deg C" Vector__XXX

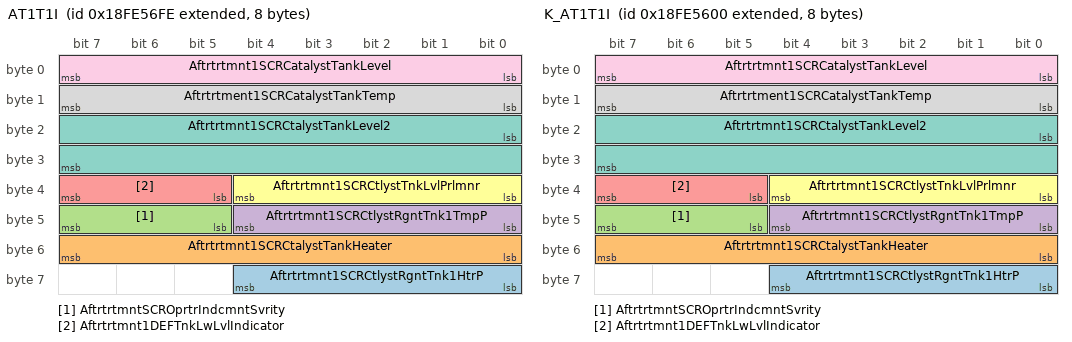
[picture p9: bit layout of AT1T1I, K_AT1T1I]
BO_ 2566805246 AT1T1I: 8 Vector__XXX
 SG_ Aftrtrtmnt1SCRCtlystRgntTnk1HtrP : 56|5@1+ (1,0) [0|31] "" Vector__XXX
 SG_ Aftrtrtmnt1SCRCtalystTankHeater : 48|8@1+ (0.4,0) [0|100] "%" Vector__XXX
 SG_ AftrtrtmntSCROprtrIndcmntSvrity : 45|3@1+ (1,0) [0|7] "" Vector__XXX
 SG_ Aftrtrtmnt1SCRCtlystRgntTnk1TmpP : 40|5@1+ (1,0) [0|31] "" Vector__XXX
 SG_ Aftrtrtmnt1DEFTnkLwLvlIndicator : 37|3@1+ (1,0) [0|7] "" Vector__XXX
 SG_ Aftrtrtmnt1SCRCtlystTnkLvlPrlmnr : 32|5@1+ (1,0) [0|31] "" Vector__XXX
 SG_ Aftrtrtmnt1SCRCtalystTankLevel2 : 16|16@1+ (0.1,0) [0|6425.5] "mm" Vector__XXX
 SG_ Aftrtrtment1SCRCatalystTankTemp : 8|8@1+ (1,-40) [-40|210] "deg C" Vector__XXX
 SG_ Aftrtrtmnt1SCRCatalystTankLevel : 0|8@1+ (0.4,0) [0|100] "%" Vector__XXX

BO_ 2566804992 K_AT1T1I: 8 Vector__XXX
 SG_ Aftrtrtmnt1SCRCtlystRgntTnk1HtrP : 56|5@1+ (1,0) [0|31] "" Vector__XXX
 SG_ Aftrtrtmnt1SCRCtalystTankHeater : 48|8@1+ (0.4,0) [0|100] "%" Vector__XXX
 SG_ AftrtrtmntSCROprtrIndcmntSvrity : 45|3@1+ (1,0) [0|7] "" Vector__XXX
 SG_ Aftrtrtmnt1SCRCtlystRgntTnk1TmpP : 40|5@1+ (1,0) [0|31] "" Vector__XXX
 SG_ Aftrtrtmnt1DEFTnkLwLvlIndicator : 37|3@1+ (1,0) [0|7] "" Vector__XXX
 SG_ Aftrtrtmnt1SCRCtlystTnkLvlPrlmnr : 32|5@1+ (1,0) [0|31] "" Vector__XXX
 SG_ Aftrtrtmnt1SCRCtalystTankLevel2 : 16|16@1+ (0.1,0) [0|6425.5] "mm" Vector__XXX
 SG_ Aftrtrtment1SCRCatalystTankTemp : 8|8@1+ (1,-40) [-40|210] "deg C" Vector__XXX
 SG_ Aftrtrtmnt1SCRCatalystTankLevel : 0|8@1+ (0.4,0) [0|100] "%" Vector__XXX

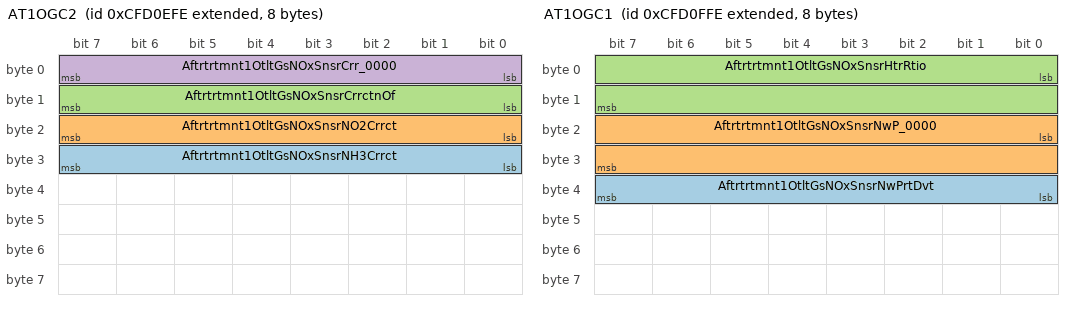
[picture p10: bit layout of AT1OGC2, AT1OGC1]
BO_ 2365394686 AT1OGC2: 8 Vector__XXX
 SG_ Aftrtrtmnt1OtltGsNOxSnsrNH3Crrct : 24|8@1+ (0.5,0) [0|125] "%" Vector__XXX
 SG_ Aftrtrtmnt1OtltGsNOxSnsrNO2Crrct : 16|8@1+ (0.5,0) [0|125] "%" Vector__XXX
 SG_ Aftrtrtmnt1OtltGsNOxSnsrCrrctnOf : 8|8@1+ (0.5,0) [0|125] "%/bar" Vector__XXX
 SG_ Aftrtrtmnt1OtltGsNOxSnsrCrr_0000 : 0|8@1+ (0.5,0) [0|125] "%/bar" Vector__XXX

BO_ 2365394942 AT1OGC1: 8 Vector__XXX
 SG_ Aftrtrtmnt1OtltGsNOxSnsrNwPrtDvt : 32|8@1+ (1,-125) [-125|125] "ppm" Vector__XXX
 SG_ Aftrtrtmnt1OtltGsNOxSnsrNwP_0000 : 16|16@1+ (0.1,-100) [-100|100] "%" Vector__XXX
 SG_ Aftrtrtmnt1OtltGsNOxSnsrHtrRtio : 0|16@1+ (0.001,0) [0|64.255] "" Vector__XXX

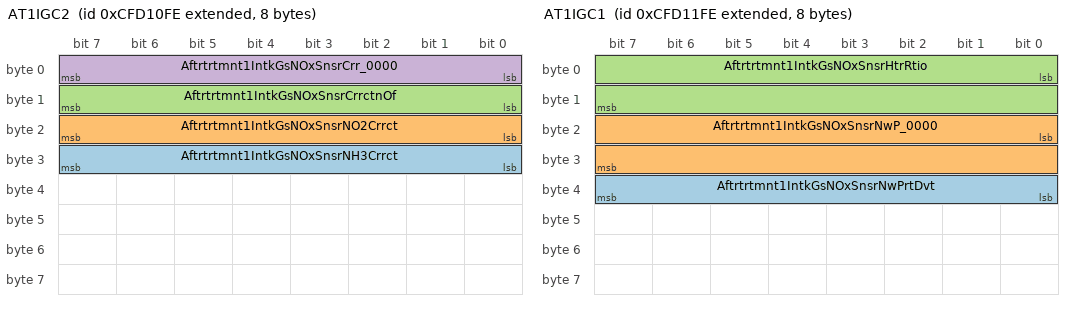
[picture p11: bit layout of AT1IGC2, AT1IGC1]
BO_ 2365395198 AT1IGC2: 8 Vector__XXX
 SG_ Aftrtrtmnt1IntkGsNOxSnsrNH3Crrct : 24|8@1+ (0.5,0) [0|125] "%" Vector__XXX
 SG_ Aftrtrtmnt1IntkGsNOxSnsrNO2Crrct : 16|8@1+ (0.5,0) [0|125] "%" Vector__XXX
 SG_ Aftrtrtmnt1IntkGsNOxSnsrCrrctnOf : 8|8@1+ (0.5,0) [0|125] "%/bar" Vector__XXX
 SG_ Aftrtrtmnt1IntkGsNOxSnsrCrr_0000 : 0|8@1+ (0.5,0) [0|125] "%/bar" Vector__XXX

BO_ 2365395454 AT1IGC1: 8 Vector__XXX
 SG_ Aftrtrtmnt1IntkGsNOxSnsrNwPrtDvt : 32|8@1+ (1,-125) [-125|125] "ppm" Vector__XXX
 SG_ Aftrtrtmnt1IntkGsNOxSnsrNwP_0000 : 16|16@1+ (0.1,-100) [-100|100] "%" Vector__XXX
 SG_ Aftrtrtmnt1IntkGsNOxSnsrHtrRtio : 0|16@1+ (0.001,0) [0|64.255] "" Vector__XXX

BO_ 2157248254 AT1DPFSSC: 8 Vector__XXX
 SG_ Aftrtrtmnt1DslPrtcltFltrStStndrd : 16|16@1+ (0.0025,0) [0|160.6375] "%" Vector__XXX
 SG_ Aftrtrtmnt1DslPrtcltFltrStMnClbO : 0|16@1+ (0.0025,0) [0|160.6375] "%" Vector__XXX

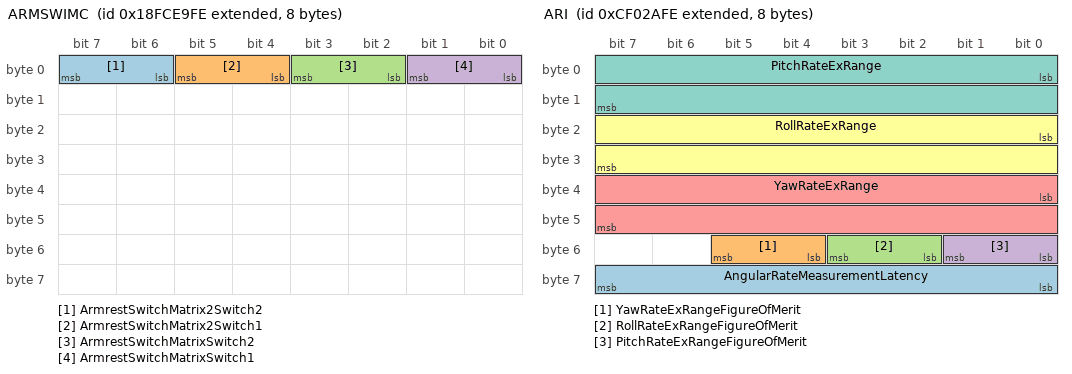
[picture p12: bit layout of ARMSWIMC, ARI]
BO_ 2566711806 ARMSWIMC: 8 Vector__XXX
 SG_ ArmrestSwitchMatrix2Switch2 : 6|2@1+ (1,0) [0|3] "" Vector__XXX
 SG_ ArmrestSwitchMatrix2Switch1 : 4|2@1+ (1,0) [0|3] "" Vector__XXX
 SG_ ArmrestSwitchMatrixSwitch2 : 2|2@1+ (1,0) [0|3] "" Vector__XXX
 SG_ ArmrestSwitchMatrixSwitch1 : 0|2@1+ (1,0) [0|3] "" Vector__XXX

BO_ 2364549886 ARI: 8 Vector__XXX
 SG_ AngularRateMeasurementLatency : 56|8@1+ (0.5,0) [0|125] "ms" Vector__XXX
 SG_ YawRateExRangeFigureOfMerit : 52|2@1+ (1,0) [0|3] "" Vector__XXX
 SG_ RollRateExRangeFigureOfMerit : 50|2@1+ (1,0) [0|3] "" Vector__XXX
 SG_ PitchRateExRangeFigureOfMerit : 48|2@1+ (1,0) [0|3] "" Vector__XXX
 SG_ YawRateExRange : 32|16@1+ (0.0078125,-250) [-250|250.992] "deg/sec" Vector__XXX
 SG_ RollRateExRange : 16|16@1+ (0.0078125,-250) [-250|250.992] "deg/sec" Vector__XXX
 SG_ PitchRateExRange : 0|16@1+ (0.0078125,-250) [-250|250.992] "deg/sec" Vector__XXX

BO_ 2566712318 AFT2NAI: 8 Vector__XXX
 SG_ Aftrtrtmnt2NOxAdsrbrDSOxRgnrtnSt : 2|2@1+ (1,0) [0|3] "" Vector__XXX
 SG_ Aftrtrtmnt2NOxAdsrbrDNOxRgnrtnSt : 0|2@1+ (1,0) [0|3] "" Vector__XXX

BO_ 2566712574 AFT1NAI: 8 Vector__XXX
 SG_ Aftrtrtmnt1NOxAdsrbrDSOxRgnrtnSt : 2|2@1+ (1,0) [0|3] "" Vector__XXX
 SG_ Aftrtrtmnt1NOxAdsrbrDNOxRgnrtnSt : 0|2@1+ (1,0) [0|3] "" Vector__XXX

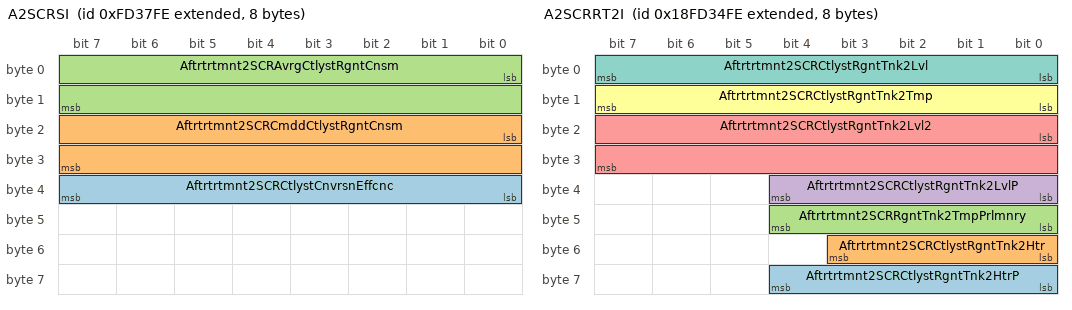
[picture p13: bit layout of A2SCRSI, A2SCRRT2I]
BO_ 2164078590 A2SCRSI: 8 Vector__XXX
 SG_ Aftrtrtmnt2SCRCtlystCnvrsnEffcnc : 32|8@1+ (0.4,0) [0|100] "%" Vector__XXX
 SG_ Aftrtrtmnt2SCRCmddCtlystRgntCnsm : 16|16@1+ (0.05,0) [0|3212.75] "L/h" Vector__XXX
 SG_ Aftrtrtmnt2SCRAvrgCtlystRgntCnsm : 0|16@1+ (0.05,0) [0|3212.75] "L/h" Vector__XXX

BO_ 2566731006 A2SCRRT2I: 8 Vector__XXX
 SG_ Aftrtrtmnt2SCRCtlystRgntTnk2HtrP : 56|5@1+ (1,0) [0|31] "" Vector__XXX
 SG_ Aftrtrtmnt2SCRCtlystRgntTnk2Htr : 48|4@1+ (1,0) [0|15] "" Vector__XXX
 SG_ Aftrtrtmnt2SCRRgntTnk2TmpPrlmnry : 40|5@1+ (1,0) [0|31] "" Vector__XXX
 SG_ Aftrtrtmnt2SCRCtlystRgntTnk2LvlP : 32|5@1+ (1,0) [0|31] "" Vector__XXX
 SG_ Aftrtrtmnt2SCRCtlystRgntTnk2Lvl2 : 16|16@1+ (0.1,0) [0|6425.5] "mm" Vector__XXX
 SG_ Aftrtrtmnt2SCRCtlystRgntTnk2Tmp : 8|8@1+ (1,-40) [-40|210] "deg C" Vector__XXX
 SG_ Aftrtrtmnt2SCRCtlystRgntTnk2Lvl : 0|8@1+ (0.4,0) [0|100] "%" Vector__XXX

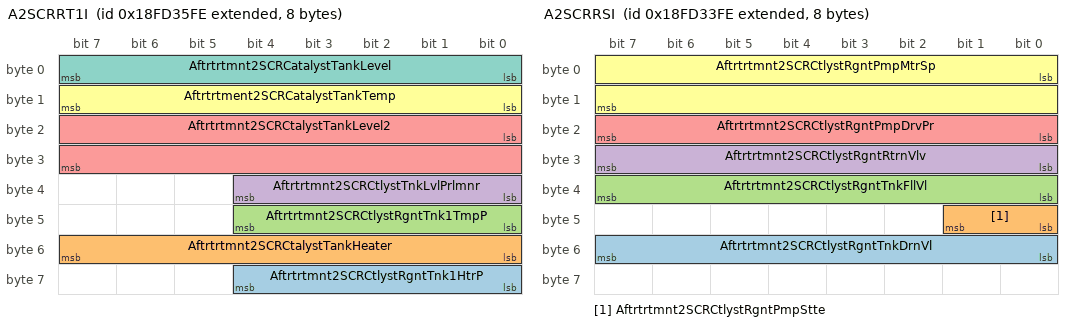
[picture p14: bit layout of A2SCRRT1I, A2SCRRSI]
BO_ 2566731262 A2SCRRT1I: 8 Vector__XXX
 SG_ Aftrtrtmnt2SCRCtlystRgntTnk1HtrP : 56|5@1+ (1,0) [0|31] "" Vector__XXX
 SG_ Aftrtrtmnt2SCRCtalystTankHeater : 48|8@1+ (0.4,0) [0|100] "%" Vector__XXX
 SG_ Aftrtrtmnt2SCRCtlystRgntTnk1TmpP : 40|5@1+ (1,0) [0|31] "" Vector__XXX
 SG_ Aftrtrtmnt2SCRCtlystTnkLvlPrlmnr : 32|5@1+ (1,0) [0|31] "" Vector__XXX
 SG_ Aftrtrtmnt2SCRCtalystTankLevel2 : 16|16@1+ (0.1,0) [0|6425.5] "mm" Vector__XXX
 SG_ Aftrtrtment2SCRCatalystTankTemp : 8|8@1+ (1,-40) [-40|210] "deg C" Vector__XXX
 SG_ Aftrtrtmnt2SCRCatalystTankLevel : 0|8@1+ (0.4,0) [0|100] "%" Vector__XXX

BO_ 2566730750 A2SCRRSI: 8 Vector__XXX
 SG_ Aftrtrtmnt2SCRCtlystRgntTnkDrnVl : 48|8@1+ (0.4,0) [0|100] "%" Vector__XXX
 SG_ Aftrtrtmnt2SCRCtlystRgntPmpStte : 40|2@1+ (1,0) [0|3] "" Vector__XXX
 SG_ Aftrtrtmnt2SCRCtlystRgntTnkFllVl : 32|8@1+ (0.4,0) [0|100] "%" Vector__XXX
 SG_ Aftrtrtmnt2SCRCtlystRgntRtrnVlv : 24|8@1+ (0.4,0) [0|100] "%" Vector__XXX
 SG_ Aftrtrtmnt2SCRCtlystRgntPmpDrvPr : 16|8@1+ (0.4,0) [0|100] "%" Vector__XXX
 SG_ Aftrtrtmnt2SCRCtlystRgntPmpMtrSp : 0|16@1+ (0.5,0) [0|32127.5] "rpm" Vector__XXX

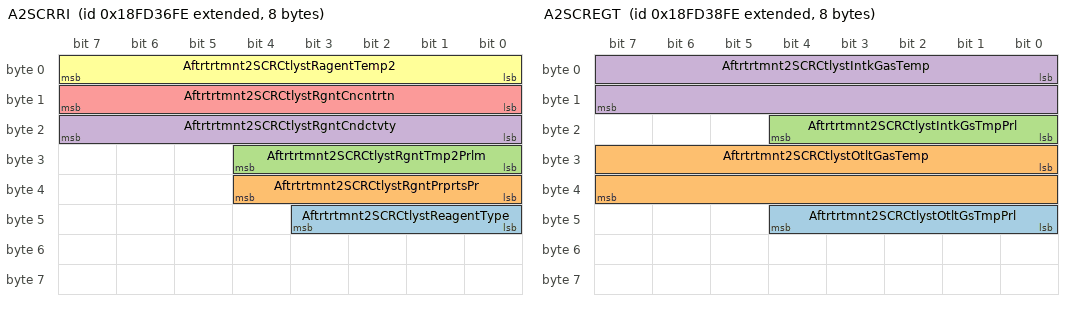
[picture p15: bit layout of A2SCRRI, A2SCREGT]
BO_ 2566731518 A2SCRRI: 8 Vector__XXX
 SG_ Aftrtrtmnt2SCRCtlystReagentType : 40|4@1+ (1,0) [0|15] "" Vector__XXX
 SG_ Aftrtrtmnt2SCRCtlystRgntPrprtsPr : 32|5@1+ (1,0) [0|31] "" Vector__XXX
 SG_ Aftrtrtmnt2SCRCtlystRgntTmp2Prlm : 24|5@1+ (1,0) [0|31] "" Vector__XXX
 SG_ Aftrtrtmnt2SCRCtlystRgntCndctvty : 16|8@1+ (5,0) [0|1250] "microSiemens/mm" Vector__XXX
 SG_ Aftrtrtmnt2SCRCtlystRgntCncntrtn : 8|8@1+ (0.25,0) [0|62.5] "%" Vector__XXX
 SG_ Aftrtrtmnt2SCRCtlystRagentTemp2 : 0|8@1+ (1,-40) [-40|210] "deg C" Vector__XXX

BO_ 2566732030 A2SCREGT: 8 Vector__XXX
 SG_ Aftrtrtmnt2SCRCtlystOtltGsTmpPrl : 40|5@1+ (1,0) [0|31] "" Vector__XXX
 SG_ Aftrtrtmnt2SCRCtlystOtltGasTemp : 24|16@1+ (0.03125,-273) [-273|1734.96875] "deg C" Vector__XXX
 SG_ Aftrtrtmnt2SCRCtlystIntkGsTmpPrl : 16|5@1+ (1,0) [0|31] "" Vector__XXX
 SG_ Aftrtrtmnt2SCRCtlystIntkGasTemp : 0|16@1+ (0.03125,-273) [-273|1734.96875] "deg C" Vector__XXX

BO_ 2566732286 A2SCREGP: 8 Vector__XXX
 SG_ Aftrtrtmnt2SCRCtlystExhstGsDffPr : 16|5@1+ (1,0) [0|31] "" Vector__XXX
 SG_ Aftrtrtmnt2SCRCtlystExhstGs_0000 : 0|16@1+ (0.1,0) [0|6425.5] "kPa" Vector__XXX

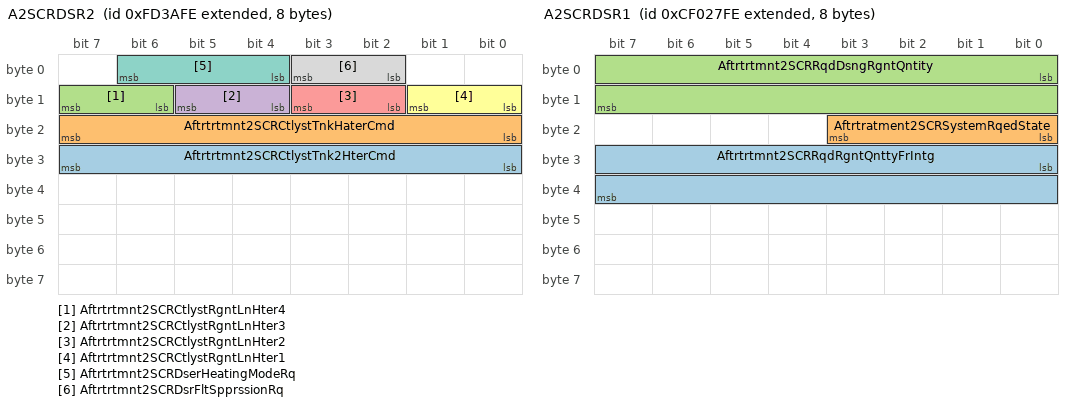
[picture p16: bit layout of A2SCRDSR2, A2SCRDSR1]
BO_ 2164079358 A2SCRDSR2: 8 Vector__XXX
 SG_ Aftrtrtmnt2SCRCtlystTnk2HterCmd : 24|8@1+ (0.4,0) [0|100] "%" Vector__XXX
 SG_ Aftrtrtmnt2SCRCtlystTnkHaterCmd : 16|8@1+ (0.4,0) [0|100] "%" Vector__XXX
 SG_ Aftrtrtmnt2SCRCtlystRgntLnHter4 : 14|2@1+ (1,0) [0|3] "" Vector__XXX
 SG_ Aftrtrtmnt2SCRCtlystRgntLnHter3 : 12|2@1+ (1,0) [0|3] "" Vector__XXX
 SG_ Aftrtrtmnt2SCRCtlystRgntLnHter2 : 10|2@1+ (1,0) [0|3] "" Vector__XXX
 SG_ Aftrtrtmnt2SCRCtlystRgntLnHter1 : 8|2@1+ (1,0) [0|3] "" Vector__XXX
 SG_ Aftrtrtmnt2SCRDserHeatingModeRq : 4|3@1+ (1,0) [0|7] "" Vector__XXX
 SG_ Aftrtrtmnt2SCRDsrFltSpprssionRq : 2|2@1+ (1,0) [0|3] "" Vector__XXX

BO_ 2364549118 A2SCRDSR1: 8 Vector__XXX
 SG_ Aftrtrtmnt2SCRRqdRgntQnttyFrIntg : 24|16@1+ (0.1,0) [0|6425.5] "g" Vector__XXX
 SG_ Aftrtratment2SCRSystemRqedState : 16|4@1+ (1,0) [0|15] "" Vector__XXX
 SG_ Aftrtrtmnt2SCRRqdDsngRgntQntity : 0|16@1+ (0.3,0) [0|19276.5] "g/h" Vector__XXX

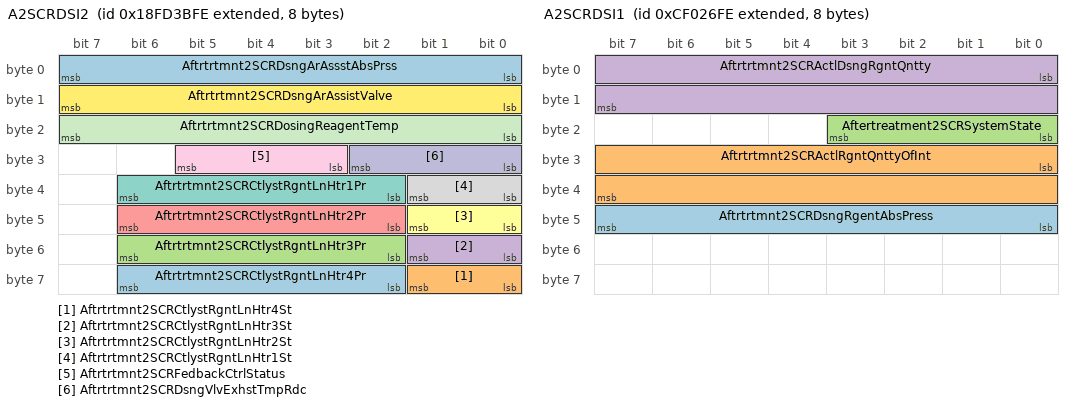
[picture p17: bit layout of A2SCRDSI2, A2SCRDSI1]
BO_ 2566732798 A2SCRDSI2: 8 Vector__XXX
 SG_ Aftrtrtmnt2SCRCtlystRgntLnHtr4Pr : 58|5@1+ (1,0) [0|31] "" Vector__XXX
 SG_ Aftrtrtmnt2SCRCtlystRgntLnHtr4St : 56|2@1+ (1,0) [0|3] "" Vector__XXX
 SG_ Aftrtrtmnt2SCRCtlystRgntLnHtr3Pr : 50|5@1+ (1,0) [0|31] "" Vector__XXX
 SG_ Aftrtrtmnt2SCRCtlystRgntLnHtr3St : 48|2@1+ (1,0) [0|3] "" Vector__XXX
 SG_ Aftrtrtmnt2SCRCtlystRgntLnHtr2Pr : 42|5@1+ (1,0) [0|31] "" Vector__XXX
 SG_ Aftrtrtmnt2SCRCtlystRgntLnHtr2St : 40|2@1+ (1,0) [0|3] "" Vector__XXX
 SG_ Aftrtrtmnt2SCRCtlystRgntLnHtr1Pr : 34|5@1+ (1,0) [0|31] "" Vector__XXX
 SG_ Aftrtrtmnt2SCRCtlystRgntLnHtr1St : 32|2@1+ (1,0) [0|3] "" Vector__XXX
 SG_ Aftrtrtmnt2SCRFedbackCtrlStatus : 27|3@1+ (1,0) [0|7] "" Vector__XXX
 SG_ Aftrtrtmnt2SCRDsngVlvExhstTmpRdc : 24|3@1+ (1,0) [0|7] "" Vector__XXX
 SG_ Aftrtrtmnt2SCRDosingReagentTemp : 16|8@1+ (1,-40) [-40|210] "deg C" Vector__XXX
 SG_ Aftrtrtmnt2SCRDsngArAssistValve : 8|8@1+ (0.4,0) [0|100] "%" Vector__XXX
 SG_ Aftrtrtmnt2SCRDsngArAssstAbsPrss : 0|8@1+ (8,0) [0|2000] "kPa" Vector__XXX

BO_ 2364548862 A2SCRDSI1: 8 Vector__XXX
 SG_ Aftrtrtmnt2SCRDsngRgentAbsPress : 40|8@1+ (8,0) [0|2000] "kPa" Vector__XXX
 SG_ Aftrtrtmnt2SCRActlRgntQnttyOfInt : 24|16@1+ (0.1,0) [0|6425.5] "g" Vector__XXX
 SG_ Aftertreatment2SCRSystemState : 16|4@1+ (1,0) [0|15] "" Vector__XXX
 SG_ Aftrtrtmnt2SCRActlDsngRgntQntty : 0|16@1+ (0.3,0) [0|19276.5] "g/h" Vector__XXX

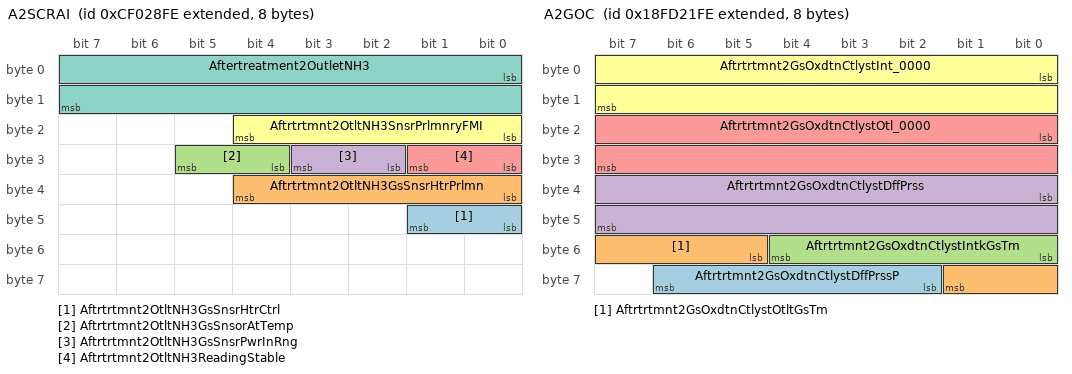
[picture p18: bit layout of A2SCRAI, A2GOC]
BO_ 2364549374 A2SCRAI: 8 Vector__XXX
 SG_ Aftrtrtmnt2OtltNH3GsSnsrHtrCtrl : 40|2@1+ (1,0) [0|3] "" Vector__XXX
 SG_ Aftrtrtmnt2OtltNH3GsSnsrHtrPrlmn : 32|5@1+ (1,0) [0|31] "" Vector__XXX
 SG_ Aftrtrtmnt2OtltNH3GsSnsorAtTemp : 28|2@1+ (1,0) [0|3] "" Vector__XXX
 SG_ Aftrtrtmnt2OtltNH3GsSnsrPwrInRng : 26|2@1+ (1,0) [0|3] "" Vector__XXX
 SG_ Aftrtrtmnt2OtltNH3ReadingStable : 24|2@1+ (1,0) [0|3] "" Vector__XXX
 SG_ Aftrtrtmnt2OtltNH3SnsrPrlmnryFMI : 16|5@1+ (1,0) [0|31] "" Vector__XXX
 SG_ Aftertreatment2OutletNH3 : 0|16@1+ (0.3,0) [0|19276.5] "g/h" Vector__XXX

BO_ 2566726142 A2GOC: 8 Vector__XXX
 SG_ Aftrtrtmnt2GsOxdtnCtlystDffPrssP : 58|5@1+ (1,0) [0|31] "" Vector__XXX
 SG_ Aftrtrtmnt2GsOxdtnCtlystOtltGsTm : 53|5@1+ (1,0) [0|31] "" Vector__XXX
 SG_ Aftrtrtmnt2GsOxdtnCtlystIntkGsTm : 48|5@1+ (1,0) [0|31] "" Vector__XXX
 SG_ Aftrtrtmnt2GsOxdtnCtlystDffPrss : 32|16@1+ (0.1,0) [0|6425.5] "kPa" Vector__XXX
 SG_ Aftrtrtmnt2GsOxdtnCtlystOtl_0000 : 16|16@1+ (0.03125,-273) [-273|1734.96875] "deg C" Vector__XXX
 SG_ Aftrtrtmnt2GsOxdtnCtlystInt_0000 : 0|16@1+ (0.03125,-273) [-273|1734.96875] "deg C" Vector__XXX

CM_ BO_ 2566844695 "Cruise Control/Vehicle Speed";
CM_ SG_ 2566844695 ParkBrakeReleaseInhibitRq "Park Brake Release Inhibit Request signals the desire that an applied park brake remain applied and limit the ability of the";
CM_ SG_ 2566844695 PTOGovernorState "This parameter is used to indicate the current state or mode of operation by the power takeoff (PTO) governor.";
CM_ SG_ 2566844695 EngShutdownOverrideSwitch "Switch signal which indicates the position of the engine shutdown override switch.";
CM_ SG_ 2566844695 EngTestModeSwitch "Switch signal which indicates the position of the engine test mode switch.";
CM_ SG_ 2566844695 EngIdleDecrementSwitch "Switch signal which indicates the position of the idle decrement switch.";
CM_ SG_ 2566844695 EngIdleIncrementSwitch "Switch signal which indicates the position of the idle increment switch.";
CM_ SG_ 2566844695 CruiseCtrlStates "This parameter is used to indicate the current state, or mode, of operation by the cruise control device.";
CM_ SG_ 2566844695 CruiseCtrlSetSpeed "Value of set (chosen) velocity of velocity control system.";
CM_ SG_ 2566844695 CruiseCtrlAccelerateSwitch "Switch signal of the cruise control activator which indicates that the activator is in the position [accelerate.";
CM_ SG_ 2566844695 CruiseCtrlResumeSwitch "Switch signal of the cruise control activator which indicates that the activator is in the position [resume.";
CM_ SG_ 2566844695 CruiseCtrlCoastSwitch "Switch signal of the cruise control activator which indicates that the activator is in the position [coast (decelerate).";
CM_ SG_ 2566844695 CruiseCtrlSetSwitch "Switch signal of the cruise control activator which indicates that the activator is in the position [set.";
CM_ SG_ 2566844695 ClutchSwitch "Switch signal which indicates that the clutch pedal is being pressed.";
CM_ SG_ 2566844695 BrakeSwitch "Switch signal which indicates that the driver operated brake foot pedal is being pressed.";
CM_ SG_ 2566844695 CruiseCtrlEnableSwitch "Switch signal which indicates that it is possible to manage the cruise control function.";
CM_ SG_ 2566844695 CruiseCtrlActive "Cruise control is switched on.";
CM_ SG_ 2566844695 WheelBasedVehicleSpeed "Speed of the vehicle as calculated from wheel or tailshaft speed.";
CM_ SG_ 2566844695 CruiseCtrlPauseSwitch "Switch signal which indicates the position of the Cruise Control Pause Switch used on Remote Cruise Control applications.";
CM_ SG_ 2566844695 ParkingBrakeSwitch "Switch signal which indicates when the parking brake is set.";
CM_ SG_ 2566844695 TwoSpeedAxleSwitch "Switch signal which indicates the current axle range.";
CM_ BO_ 2566843902 "Cruise Control/Vehicle Speed Setup";
CM_ SG_ 2566843902 CruiseCtrlLowSetLimitSpeed "Minimum vehicle velocity at which cruise can be set or minimum vehicle velocity for cruise operation before it will exit";
CM_ SG_ 2566843902 CruiseCtrlHighSetLimitSpeed "Maximum vehicle velocity at which cruise can be set.";
CM_ SG_ 2566843902 MaxVehicleSpeedLimit "Maximum vehicle velocity allowed.";
CM_ BO_ 2566809598 "Climate Control Configuration";
CM_ SG_ 2566809598 AuxHeaterMaxOutputPower "The maximum output power of the auxiliary heater.";
CM_ BO_ 2633940222 "Compression/Service Brake Information";
CM_ SG_ 2633940222 TripServiceBrakeApps "Total number of times the service brakes have been activated since the last trip reset.";
CM_ SG_ 2633940222 TripServiceBrakeDistance "Total distance over which the service brakes have been active since the last trip reset.";
CM_ SG_ 2633940222 TripCompressionBrakeDistance "Total distance over which the compression brakes have been active since the last trip reset.";
CM_ SG_ 2633940222 TotalCompressionBrakeDistance "Total distance over which the compression brakes have been active for the life of the engine.";
CM_ BO_ 2566775294 "Cab A/C Climate System Information";
CM_ SG_ 2566775294 CbA_CRfrgrntCmprssorOutletPress "This is the gage pressure at the compressor outlet in the cab air conditioning system.";
CM_ BO_ 2566803710 "Battery Temperature";
CM_ SG_ 2566803710 Battery2Temp "Temperature of the battery 2.";
CM_ SG_ 2566803710 Battery1Temp "Temperature of the battery 1.";
CM_ BO_ 2365476881 "Battery Temperature";
CM_ SG_ 2365476881 Battery2Temp "Temperature of the battery 2.";
CM_ SG_ 2365476881 Battery1Temp "Temperature of the battery 1.";
CM_ BO_ 2566719486 "Direct Lamp Control Command 1";
CM_ SG_ 2566719486 EngFuelFilterRestrictedLampCmd "Command signal directly controlling the Vehicle Fuel Filter Restricted Lamp.";
CM_ SG_ 2566719486 EngAirFilterRestrictionLampCmd "Command signal directly controlling the Engine Air Filter Restriction Lamp.";
CM_ SG_ 2566719486 EngIdleManagementActiveLampCmd "Command signal directly controlling the Engine Idle Management Active Lamp";
CM_ SG_ 2566719486 EngCoolantLevelLowLampCmd "Command signal directly controlling the Engine Coolant Level Low Lamp";
CM_ SG_ 2566719486 EngCoolantTempHighLampCmd "Command signal directly controlling the Engine Coolant Temperature High Lamp";
CM_ SG_ 2566719486 EngOilPressLowLampCmd "Command signal directly controlling the Engine Oil Pressure Low Lamp";
CM_ SG_ 2566719486 CmprssnBrkEnblSwtchIndctrLmpCmd "Command signal directly controlling Compression Brake Enable Switch Indicator Lamp.";
CM_ SG_ 2566719486 EngBrakeActiveLampCmd "Command signal directly controlling the Engine Brake Active Lamp";
CM_ SG_ 2566719486 OBDMalfunctionIndicatorLampCmd "Command signal directly controlling the OBD Malfunction Indicator Lamp";
CM_ SG_ 2566719486 EngRedStopLampCmd "Command signal directly controlling the Engine Red Stop Lamp";
CM_ SG_ 2566719486 EngAmberWarningLampCmd "Command signal directly controlling the Engine Amber Warning Lamp";
CM_ SG_ 2566719486 EngProtectLampCmd "Command signal directly controlling the Engine Protect Lamp";
CM_ BO_ 2633832702 "Collision Sensor Information";
CM_ SG_ 2633832702 RearCollisionSensor4Type "Type of Rear Collision Sensor 4.";
CM_ SG_ 2633832702 RearCollisionSensor3Type "Type of Rear Collision Sensor 3.";
CM_ SG_ 2633832702 RearCollisionSensor2Type "Type of Rear Collision Sensor 2.";
CM_ SG_ 2633832702 RearCollisionSensor1Type "Type of Rear Collision Sensor 1.";
CM_ SG_ 2633832702 SdeCollisionSensorRearRightType "Type of Side Collision Sensor Rear - Right.";
CM_ SG_ 2633832702 SdCllsionSensorMidRearRightType "Type of Side Collision Sensor Mid Rear - Right.";
CM_ SG_ 2633832702 SdCllsonSensorMidFrontRightType "Type of Side Collision Sensor Mid Front - Right.";
CM_ SG_ 2633832702 SdCollisionSensorFrontRightType "Type of Side Collision Sensor Front - Right.";
CM_ SG_ 2633832702 SideCollisionSensorRearLeftType "Type of Side Collision Sensor Rear - Left.";
CM_ SG_ 2633832702 SdCllisionSensorMidRearLeftType "Type of Side Collision Sensor Mid Rear - Left.";
CM_ SG_ 2633832702 SdCllsionSensorMidFrontLeftType "Type of Side Collision Sensor Mid Front - Left.";
CM_ SG_ 2633832702 SdeCollisionSensorFrontLeftType "Type of Side Collision Sensor Front - Left.";
CM_ SG_ 2633832702 FrontalCollisionSensor4Type "Type of Frontal Collision Sensor 4.";
CM_ SG_ 2633832702 FrontalCollisionSensor3Type "Type of Frontal Collision Sensor 3.";
CM_ SG_ 2633832702 FrontalCollisionSensor2Type "Type of Frontal Collision Sensor 2.";
CM_ SG_ 2633832702 FrontalCollisionSensor1Type "Type of Frontal Collision Sensor 1.";
CM_ BO_ 2163223550 "Crash Notification";
CM_ SG_ 2163223550 CrashChecksum "The Crash Checksum is used to verify the signal path from the airbag ECU to other devices in case of a crash.";
CM_ SG_ 2163223550 CrashCounter "The Crash Counter prevents other ECUs from reacting to a faulty transmission of the Crash Notification PGN and serves";
CM_ SG_ 2163223550 CrashType "Type of crash event.";
CM_ BO_ 2566714878 "Charge Air Cooler 2 Precooler";
CM_ SG_ 2566714878 EngChrgArClr2PrcoolerEfficiency "Engine charge air cooler 2 (CAC2) precooler efficiency is an indication of the precooler's ability to reduce the temperature";
CM_ SG_ 2566714878 EngChrgArClr2PrcoolerOutletTemp "Temperature of the combustion air measured at the charge air cooler 2 precooler outlet.";
CM_ SG_ 2566714878 EngChrgArClr2PrcoolerIntakeTemp "Temperature of the combustion air measured at the charge air cooler 2 precooler Intake.";
CM_ BO_ 2566714622 "Charge Air Cooler 2";
CM_ SG_ 2566714622 EngChargeAirCooler2Efficiency "Engine charge air cooler 2 (CAC2) is an indication of the CAC's ability to reduce the temperature of the combustion air";
CM_ SG_ 2566714622 EngChrgAirCooler2AmbientAirTemp "Temperature of the air surrounding charge air cooler 2.";
CM_ SG_ 2566714622 EngChargeAirCooler2OutletTemp "Temperature of combustion air after it exits from the Charge Air Cooler 2 but before any mixing of recirculated exhaust";
CM_ SG_ 2566714622 EngChargeAirCooler2IntakeTemp "Temperature of the combustion air measured at the charge air cooler 2 Intake.";
CM_ BO_ 2566715390 "Charge Air Cooler 1 Precooler";
CM_ SG_ 2566715390 EngChrgArClr1PrcoolerEfficiency "Engine charge air cooler 1 (CAC1) precooler efficiency is an indication of the precooler's ability to reduce the temperature";
CM_ SG_ 2566715390 EngChrgArClr1PrcoolerOutletTemp "Temperature of the combustion air measured at the charge air cooler 1 precooler outlet.";
CM_ SG_ 2566715390 EngChrgArClr1PrcoolerIntakeTemp "Temperature of the combustion air measured at the charge air cooler 1 precooler intake.";
CM_ BO_ 2566715134 "Charge Air Cooler 1";
CM_ SG_ 2566715134 EngChargeAirCooler1Efficiency "Engine charge air cooler 1(CAC1) efficiency is an indication of the CAC's ability to reduce the temperature of the";
CM_ SG_ 2566715134 EngChrgAirCooler1AmbientAirTemp "Temperature of the air surrounding charge air cooler 1.";
CM_ SG_ 2566715134 EngChargeAirCooler1IntakeTemp "Temperature of the combustion air measured at the CAC 1 Intake.";
CM_ BO_ 2365400830 "Basic Joystick Message 9";
CM_ SG_ 2365400830 Joystick9Button9PressedStatus "Reports when the joystick button has been pressed.";
CM_ SG_ 2365400830 Joystick9Button10PressedStatus "Reports when the joystick button has been pressed.";
CM_ SG_ 2365400830 Joystick9Button11PressedStatus "Reports when the joystick button has been pressed.";
CM_ SG_ 2365400830 Joystick9Button12PressedStatus "Reports when the joystick button has been pressed.";
CM_ SG_ 2365400830 Joystick9Button5PressedStatus "Reports when the joystick button has been pressed.";
CM_ SG_ 2365400830 Joystick9Button6PressedStatus "Reports when the joystick button has been pressed.";
CM_ SG_ 2365400830 Joystick9Button7PressedStatus "Reports when the joystick button has been pressed.";
CM_ SG_ 2365400830 Joystick9Button8PressedStatus "Reports when the joystick button has been pressed.";
CM_ SG_ 2365400830 Joystick9Button1PressedStatus "Reports when the joystick button has been pressed.";
CM_ SG_ 2365400830 Joystick9Button2PressedStatus "Reports when the joystick button has been pressed.";
CM_ SG_ 2365400830 Joystick9Button3PressedStatus "Reports when the joystick button has been pressed.";
CM_ SG_ 2365400830 Joystick9Button4PressedStatus "Reports when the joystick button has been pressed.";
CM_ SG_ 2365400830 Joystick9XAxisDetentPosStatus "Reports when the current joystick position is in the detent position for that axis of travel.";
CM_ SG_ 2365400830 Joystick9YAxisDetentPosStatus "Reports when the current joystick position is in the detent position for that axis of travel.";
CM_ SG_ 2365400830 Joystick9YAxisPos "The position of the joystick in the relative motion of travel from the neutral position.";
CM_ SG_ 2365400830 Jystck9YAxsLvrFrwrdPstvPsStatus "Reports when the current joystick position is on the positive travel side (forward, right, clockwise, up) relative to the";
CM_ SG_ 2365400830 Jystck9YAxsLvrBckNgtvePosStatus "Reports when the current joystick position is on the negative travel side (back, left, counterclockwise, down) relative to the";
CM_ SG_ 2365400830 Joystick9YAxisNeutralPosStatus "Reports when the current joystick position is in the neutral position for that axis of travel.";
CM_ SG_ 2365400830 Joystick9XAxisPos "The position of the joystick in the relative motion of travel from the neutral position.";
CM_ SG_ 2365400830 Jystck9XAxsLvrRghtPstvPosStatus "Reports when the current joystick position is on the positive travel side (forward, right, clockwise, up) relative to the";
CM_ SG_ 2365400830 Jystck9XAxsLvrLftNgtvePosStatus "Reports when the current joystick position is on the negative travel side (back, left, counterclockwise, down) relative to the";
CM_ SG_ 2365400830 Joystick9XAxisNeutralPosStatus "Reports when the current joystick position is in the neutral position for that axis of travel.";
CM_ BO_ 2365401342 "Basic Joystick Message 8";
CM_ SG_ 2365401342 Joystick8Button9PressedStatus "Reports when the joystick button has been pressed.";
CM_ SG_ 2365401342 Joystick8Button10PressedStatus "Reports when the joystick button has been pressed.";
CM_ SG_ 2365401342 Joystick8Button11PressedStatus "Reports when the joystick button has been pressed.";
CM_ SG_ 2365401342 Joystick8Button12PressedStatus "Reports when the joystick button has been pressed.";
CM_ SG_ 2365401342 Joystick8Button5PressedStatus "Reports when the joystick button has been pressed.";
CM_ SG_ 2365401342 Joystick8Button6PressedStatus "Reports when the joystick button has been pressed.";
CM_ SG_ 2365401342 Joystick8Button7PressedStatus "Reports when the joystick button has been pressed.";
CM_ SG_ 2365401342 Joystick8Button8PressedStatus "Reports when the joystick button has been pressed.";
CM_ SG_ 2365401342 Joystick8Button1PressedStatus "Reports when the joystick button has been pressed.";
CM_ SG_ 2365401342 Joystick8Button2PressedStatus "Reports when the joystick button has been pressed.";
CM_ SG_ 2365401342 Joystick8Button3PressedStatus "Reports when the joystick button has been pressed.";
CM_ SG_ 2365401342 Joystick8Button4PressedStatus "Reports when the joystick button has been pressed.";
CM_ SG_ 2365401342 Joystick8XAxisDetentPosStatus "Reports when the current joystick position is in the detent position for that axis of travel.";
CM_ SG_ 2365401342 Joystick8YAxisDetentPosStatus "Reports when the current joystick position is in the detent position for that axis of travel.";
CM_ SG_ 2365401342 Joystick8YAxisPos "The position of the joystick in the relative motion of travel from the neutral position.";
CM_ SG_ 2365401342 Jystck8YAxsLvrFrwrdPstvPsStatus "Reports when the current joystick position is on the positive travel side (forward, right, clockwise, up) relative to the";
CM_ SG_ 2365401342 Jystck8YAxsLvrBckNgtvePosStatus "Reports when the current joystick position is on the negative travel side (back, left, counterclockwise, down) relative to the";
CM_ SG_ 2365401342 Joystick8YAxisNeutralPosStatus "Reports when the current joystick position is in the neutral position for that axis of travel.";
CM_ SG_ 2365401342 Joystick8XAxisPos "The position of the joystick in the relative motion of travel from the neutral position.";
CM_ SG_ 2365401342 Jystck8XAxsLvrRghtPstvPosStatus "Reports when the current joystick position is on the positive travel side (forward, right, clockwise, up) relative to the";
CM_ SG_ 2365401342 Jystck8XAxsLvrLftNgtvePosStatus "Reports when the current joystick position is on the negative travel side (back, left, counterclockwise, down) relative to the";
CM_ SG_ 2365401342 Joystick8XAxisNeutralPosStatus "Reports when the current joystick position is in the neutral position for that axis of travel.";
CM_ BO_ 2365401854 "Basic Joystick Message 7";
CM_ SG_ 2365401854 Joystick7Button9PressedStatus "Reports when the joystick button has been pressed.";
CM_ SG_ 2365401854 Joystick7Button10PressedStatus "Reports when the joystick button has been pressed.";
CM_ SG_ 2365401854 Joystick7Button11PressedStatus "Reports when the joystick button has been pressed.";
CM_ SG_ 2365401854 Joystick7Button12PressedStatus "Reports when the joystick button has been pressed.";
CM_ SG_ 2365401854 Joystick7Button5PressedStatus "Reports when the joystick button has been pressed.";
CM_ SG_ 2365401854 Joystick7Button6PressedStatus "Reports when the joystick button has been pressed.";
CM_ SG_ 2365401854 Joystick7Button7PressedStatus "Reports when the joystick button has been pressed.";
CM_ SG_ 2365401854 Joystick7Button8PressedStatus "Reports when the joystick button has been pressed.";
CM_ SG_ 2365401854 Joystick7Button1PressedStatus "Reports when the joystick button has been pressed.";
CM_ SG_ 2365401854 Joystick7Button2PressedStatus "Reports when the joystick button has been pressed.";
CM_ SG_ 2365401854 Joystick7Button3PressedStatus "Reports when the joystick button has been pressed.";
CM_ SG_ 2365401854 Joystick7Button4PressedStatus "Reports when the joystick button has been pressed.";
CM_ SG_ 2365401854 Joystick7XAxisDetentPosStatus "Reports when the current joystick position is in the detent position for that axis of travel.";
CM_ SG_ 2365401854 Joystick7YAxisDetentPosStatus "Reports when the current joystick position is in the detent position for that axis of travel.";
CM_ SG_ 2365401854 Joystick7YAxisPos "The position of the joystick in the relative motion of travel from the neutral position.";
CM_ SG_ 2365401854 Jystck7YAxsLvrFrwrdPstvPsStatus "Reports when the current joystick position is on the positive travel side (forward, right, clockwise, up) relative to the";
CM_ SG_ 2365401854 Jystck7YAxsLvrBckNgtvePosStatus "Reports when the current joystick position is on the negative travel side (back, left, counterclockwise, down) relative to the";
CM_ SG_ 2365401854 Joystick7YAxisNeutralPosStatus "Reports when the current joystick position is in the neutral position for that axis of travel.";
CM_ SG_ 2365401854 Joystick7XAxisPos "The position of the joystick in the relative motion of travel from the neutral position.";
CM_ SG_ 2365401854 Jystck7XAxsLvrRghtPstvPosStatus "Reports when the current joystick position is on the positive travel side (forward, right, clockwise, up) relative to the";
CM_ SG_ 2365401854 Jystck7XAxsLvrLftNgtvePosStatus "Reports when the current joystick position is on the negative travel side (back, left, counterclockwise, down) relative to the";
CM_ SG_ 2365401854 Joystick7XAxisNeutralPosStatus "Reports when the current joystick position is in the neutral position for that axis of travel.";
CM_ BO_ 2365402366 "Basic Joystick Message 6";
CM_ SG_ 2365402366 Joystick6Button9PressedStatus "Reports when the joystick button has been pressed.";
CM_ SG_ 2365402366 Joystick6Button10PressedStatus "Reports when the joystick button has been pressed.";
CM_ SG_ 2365402366 Joystick6Button11PressedStatus "Reports when the joystick button has been pressed.";
CM_ SG_ 2365402366 Joystick6Button12PressedStatus "Reports when the joystick button has been pressed.";
CM_ SG_ 2365402366 Joystick6Button5PressedStatus "Reports when the joystick button has been pressed.";
CM_ SG_ 2365402366 Joystick6Button6PressedStatus "Reports when the joystick button has been pressed.";
CM_ SG_ 2365402366 Joystick6Button7PressedStatus "Reports when the joystick button has been pressed.";
CM_ SG_ 2365402366 Joystick6Button8PressedStatus "Reports when the joystick button has been pressed.";
CM_ SG_ 2365402366 Joystick6Button1PressedStatus "Reports when the joystick button has been pressed.";
CM_ SG_ 2365402366 Joystick6Button2PressedStatus "Reports when the joystick button has been pressed.";
CM_ SG_ 2365402366 Joystick6Button3PressedStatus "Reports when the joystick button has been pressed.";
CM_ SG_ 2365402366 Joystick6Button4PressedStatus "Reports when the joystick button has been pressed.";
CM_ SG_ 2365402366 Joystick6XAxisDetentPosStatus "Reports when the current joystick position is in the detent position for that axis of travel.";
CM_ SG_ 2365402366 Joystick6YAxisDetentPosStatus "Reports when the current joystick position is in the detent position for that axis of travel.";
CM_ SG_ 2365402366 Joystick6YAxisPos "The position of the joystick in the relative motion of travel from the neutral position.";
CM_ SG_ 2365402366 Jystck6YAxsLvrFrwrdPstvPsStatus "Reports when the current joystick position is on the positive travel side (forward, right, clockwise, up) relative to the";
CM_ SG_ 2365402366 Jystck6YAxsLvrBckNgtvePosStatus "Reports when the current joystick position is on the negative travel side (back, left, counterclockwise, down) relative to the";
CM_ SG_ 2365402366 Joystick6YAxisNeutralPosStatus "Reports when the current joystick position is in the neutral position for that axis of travel.";
CM_ SG_ 2365402366 Joystick6XAxisPos "The position of the joystick in the relative motion of travel from the neutral position.";
CM_ SG_ 2365402366 Jystck6XAxsLvrRghtPstvPosStatus "Reports when the current joystick position is on the positive travel side (forward, right, clockwise, up) relative to the";
CM_ SG_ 2365402366 Jystck6XAxsLvrLftNgtvePosStatus "Reports when the current joystick position is on the negative travel side (back, left, counterclockwise, down) relative to the";
CM_ SG_ 2365402366 Joystick6XAxisNeutralPosStatus "Reports when the current joystick position is in the neutral position for that axis of travel.";
CM_ BO_ 2365402878 "Basic Joystick Message 5";
CM_ SG_ 2365402878 Joystick5Button9PressedStatus "Reports when the joystick button has been pressed.";
CM_ SG_ 2365402878 Joystick5Button10PressedStatus "Reports when the joystick button has been pressed.";
CM_ SG_ 2365402878 Joystick5Button11PressedStatus "Reports when the joystick button has been pressed.";
CM_ SG_ 2365402878 Joystick5Button12PressedStatus "Reports when the joystick button has been pressed.";
CM_ SG_ 2365402878 Joystick5Button5PressedStatus "Reports when the joystick button has been pressed.";
CM_ SG_ 2365402878 Joystick5Button6PressedStatus "Reports when the joystick button has been pressed.";
CM_ SG_ 2365402878 Joystick5Button7PressedStatus "Reports when the joystick button has been pressed.";
CM_ SG_ 2365402878 Joystick5Button8PressedStatus "Reports when the joystick button has been pressed.";
CM_ SG_ 2365402878 Joystick5Button1PressedStatus "Reports when the joystick button has been pressed.";
CM_ SG_ 2365402878 Joystick5Button2PressedStatus "Reports when the joystick button has been pressed.";
CM_ SG_ 2365402878 Joystick5Button3PressedStatus "Reports when the joystick button has been pressed.";
CM_ SG_ 2365402878 Joystick5Button4PressedStatus "Reports when the joystick button has been pressed.";
CM_ SG_ 2365402878 Joystick5XAxisDetentPosStatus "Reports when the current joystick position is in the detent position for that axis of travel.";
CM_ SG_ 2365402878 Joystick5YAxisDetentPosStatus "Reports when the current joystick position is in the detent position for that axis of travel.";
CM_ SG_ 2365402878 Joystick5YAxisPos "The position of the joystick in the relative motion of travel from the neutral position.";
CM_ SG_ 2365402878 Jystck5YAxsLvrFrwrdPstvPsStatus "Reports when the current joystick position is on the positive travel side (forward, right, clockwise, up) relative to the";
CM_ SG_ 2365402878 Jystck5YAxsLvrBckNgtvePosStatus "Reports when the current joystick position is on the negative travel side (back, left, counterclockwise, down) relative to the";
CM_ SG_ 2365402878 Joystick5YAxisNeutralPosStatus "Reports when the current joystick position is in the neutral position for that axis of travel.";
CM_ SG_ 2365402878 Joystick5XAxisPos "The position of the joystick in the relative motion of travel from the neutral position.";
CM_ SG_ 2365402878 Jystck5XAxsLvrRghtPstvPosStatus "Reports when the current joystick position is on the positive travel side (forward, right, clockwise, up) relative to the";
CM_ SG_ 2365402878 Jystck5XAxsLvrLftNgtvePosStatus "Reports when the current joystick position is on the negative travel side (back, left, counterclockwise, down) relative to the";
CM_ SG_ 2365402878 Joystick5XAxisNeutralPosStatus "Reports when the current joystick position is in the neutral position for that axis of travel.";
CM_ BO_ 2365403390 "Basic Joystick Message 4";
CM_ SG_ 2365403390 Joystick4Button9PressedStatus "Reports when the joystick button has been pressed.";
CM_ SG_ 2365403390 Joystick4Button10PressedStatus "Reports when the joystick button has been pressed.";
CM_ SG_ 2365403390 Joystick4Button11PressedStatus "Reports when the joystick button has been pressed.";
CM_ SG_ 2365403390 Joystick4Button12PressedStatus "Reports when the joystick button has been pressed.";
CM_ SG_ 2365403390 Joystick4Button5PressedStatus "Reports when the joystick button has been pressed.";
CM_ SG_ 2365403390 Joystick4Button6PressedStatus "Reports when the joystick button has been pressed.";
CM_ SG_ 2365403390 Joystick4Button7PressedStatus "Reports when the joystick button has been pressed.";
CM_ SG_ 2365403390 Joystick4Button8PressedStatus "Reports when the joystick button has been pressed.";
CM_ SG_ 2365403390 Joystick4Button1PressedStatus "Reports when the joystick button has been pressed.";
CM_ SG_ 2365403390 Joystick4Button2PressedStatus "Reports when the joystick button has been pressed.";
CM_ SG_ 2365403390 Joystick4Button3PressedStatus "Reports when the joystick button has been pressed.";
CM_ SG_ 2365403390 Joystick4Button4PressedStatus "Reports when the joystick button has been pressed.";
CM_ SG_ 2365403390 Joystick4XAxisDetentPosStatus "Reports when the current joystick position is in the detent position for that axis of travel.";
CM_ SG_ 2365403390 Joystick4YAxisDetentPosStatus "Reports when the current joystick position is in the detent position for that axis of travel.";
CM_ SG_ 2365403390 Joystick4YAxisPos "The position of the joystick in the relative motion of travel from the neutral position.";
CM_ SG_ 2365403390 Jystck4YAxsLvrFrwrdPstvPsStatus "Reports when the current joystick position is on the positive travel side (forward, right, clockwise, up) relative to the";
CM_ SG_ 2365403390 Jystck4YAxsLvrBckNgtvePosStatus "Reports when the current joystick position is on the negative travel side (back, left, counterclockwise, down) relative to the";
CM_ SG_ 2365403390 Joystick4YAxisNeutralPosStatus "Reports when the current joystick position is in the neutral position for that axis of travel.";
CM_ SG_ 2365403390 Joystick4XAxisPos "The position of the joystick in the relative motion of travel from the neutral position.";
CM_ SG_ 2365403390 Jystck4XAxsLvrRghtPstvPosStatus "Reports when the current joystick position is on the positive travel side (forward, right, clockwise, up) relative to the";
CM_ SG_ 2365403390 Jystck4XAxsLvrLftNgtvePosStatus "Reports when the current joystick position is on the negative travel side (back, left, counterclockwise, down) relative to the";
CM_ SG_ 2365403390 Joystick4XAxisNeutralPosStatus "Reports when the current joystick position is in the neutral position for that axis of travel.";
CM_ BO_ 2365400318 "Basic Joystick Message 10";
CM_ SG_ 2365400318 Joystick10Button9PressedStatus "Reports when the joystick button has been pressed.";
CM_ SG_ 2365400318 Joystick10Button10PressedStatus "Reports when the joystick button has been pressed.";
CM_ SG_ 2365400318 Joystick10Button11PressedStatus "Reports when the joystick button has been pressed.";
CM_ SG_ 2365400318 Joystick10Button12PressedStatus "Reports when the joystick button has been pressed.";
CM_ SG_ 2365400318 Joystick10Button5PressedStatus "Reports when the joystick button has been pressed.";
CM_ SG_ 2365400318 Joystick10Button6PressedStatus "Reports when the joystick button has been pressed.";
CM_ SG_ 2365400318 Joystick10Button7PressedStatus "Reports when the joystick button has been pressed.";
CM_ SG_ 2365400318 Joystick10Button8PressedStatus "Reports when the joystick button has been pressed.";
CM_ SG_ 2365400318 Joystick10Button1PressedStatus "Reports when the joystick button has been pressed.";
CM_ SG_ 2365400318 Joystick10Button2PressedStatus "Reports when the joystick button has been pressed.";
CM_ SG_ 2365400318 Joystick10Button3PressedStatus "Reports when the joystick button has been pressed.";
CM_ SG_ 2365400318 Joystick10Button4PressedStatus "Reports when the joystick button has been pressed.";
CM_ SG_ 2365400318 Joystick10XAxisDetentPosStatus "Reports when the current joystick position is in the detent position for that axis of travel.";
CM_ SG_ 2365400318 Joystick10YAxisDetentPosStatus "Reports when the current joystick position is in the detent position for that axis of travel.";
CM_ SG_ 2365400318 Joystick10YAxisPos "The position of the joystick in the relative motion of travel from the neutral position.";
CM_ SG_ 2365400318 Jystck10YAxsLvrFrwrdPstvPsSttus "Reports when the current joystick position is on the positive travel side (forward, right, clockwise, up) relative to the";
CM_ SG_ 2365400318 Jystck10YAxsLvrBckNgtvPosStatus "Reports when the current joystick position is on the negative travel side (back, left, counterclockwise, down) relative to the";
CM_ SG_ 2365400318 Joystick10YAxisNeutralPosStatus "Reports when the current joystick position is in the neutral position for that axis of travel.";
CM_ SG_ 2365400318 Joystick10XAxisPos "The position of the joystick in the relative motion of travel from the neutral position.";
CM_ SG_ 2365400318 Jystck10XAxsLvrRghtPstvPsStatus "Reports when the current joystick position is on the positive travel side (forward, right, clockwise, up) relative to the";
CM_ SG_ 2365400318 Jystck10XAxsLvrLftNgtvPosStatus "Reports when the current joystick position is on the negative travel side (back, left, counterclockwise, down) relative to the";
CM_ SG_ 2365400318 Joystick10XAxisNeutralPosStatus "Reports when the current joystick position is in the neutral position for that axis of travel.";
CM_ BO_ 2499614718 "Beltlock and Airbag Deactivation Switch Information";
CM_ SG_ 2499614718 PssngrArbgDctvationSwitchStatus "State of switch used to deactivate Passenger Airbag manually.";
CM_ SG_ 2499614718 Beltlock10Status "State of switch used to determine if Beltlock 10 is buckled.";
CM_ SG_ 2499614718 Beltlock9Status "State of switch used to determine if Beltlock 9 is buckled.";
CM_ SG_ 2499614718 Beltlock8Status "State of switch used to determine if Beltlock 8 is buckled.";
CM_ SG_ 2499614718 Beltlock7Status "State of switch used to determine if Beltlock 7 is buckled.";
CM_ SG_ 2499614718 Beltlock6Status "State of switch used to determine if Beltlock 6 is buckled.";
CM_ SG_ 2499614718 Beltlock5Status "State of switch used to determine if Beltlock 5 is buckled.";
CM_ SG_ 2499614718 Beltlock4Status "State of switch used to determine if Beltlock 4 is buckled.";
CM_ SG_ 2499614718 Beltlock3Status "State of switch used to determine if Beltlock 3 is buckled.";
CM_ SG_ 2499614718 PassengerBeltlockStatus "State of switch used to determine if Passenger Beltlock is buckled.";
CM_ SG_ 2499614718 DriverBeltlockStatus "State of switch used to determine if Driver Beltlock is buckled.";
CM_ BO_ 2566722814 "Battery Charger 2";
CM_ SG_ 2566722814 BatteryCharger2OutputCurrent "Output current of the battery charger connected to the main battery.";
CM_ SG_ 2566722814 BatteryCharger2OutputVoltage "Output voltage measured on the battery terminals of the offline battery charger connected to the auxiliary battery.";
CM_ SG_ 2566722814 BatteryCharger2PowerLineState "A state of the battery charger connection to the power line for the charger connected to the auxiliary battery.";
CM_ SG_ 2566722814 BatteryCharger2State "A state of the offline battery charger connected to the auxiliary battery.";
CM_ BO_ 2566723070 "Battery Charger 1";
CM_ SG_ 2566723070 BatteryCharger1OutputCurrent "Output current of the battery charger connected to the main battery.";
CM_ SG_ 2566723070 BatteryCharger1OutputVoltage "Output voltage measured on the battery terminals of the battery charger connected to the main battery.";
CM_ SG_ 2566723070 BatteryCharger1PowerLineState "A state of the battery charger connection to the power line for the charger connected to the main battery.";
CM_ SG_ 2566723070 BatteryCharger1State "A state of the battery charger connected to the main battery.";
CM_ BO_ 2566725118 "Aftertreatment Differential Temperature 2";
CM_ SG_ 2566725118 Aftrtrtmnt2ThrWyCtlystDffGsTemp "The differential engine combustion byproducts gas temperature measured between the intake and outlet of the three way";
CM_ SG_ 2566725118 Aftrtrtmnt1ThrWyCtlystDffGsTemp "The differential engine combustion byproducts gas temperature measured between the intake and outlet of the three way";
CM_ BO_ 2566725374 "Aftertreatment Differential Temperature 1";
CM_ SG_ 2566725374 Aftrtrtmnt2GsOxdtnCtlystDffGsTmp "The differential engine combustion byproducts gas temperature measured between the intake and outlet of the gas";
CM_ SG_ 2566725374 Aftrtrtmnt1GsOxdtnCtlystDffGsTmp "The differential engine combustion byproducts gas temperature measured between the intake and outlet of the gas";
CM_ BO_ 2566712830 "Aftertreatment 2 Warm Up Diesel Oxidation Catalyst Information";
CM_ SG_ 2566712830 Aftrtrtmnt2WrmUpDslOxdtnCtlystOt "Temperature of engine combustion byproducts leaving the warm up Diesel Oxidation Catalyst in exhaust bank 2.";
CM_ SG_ 2566712830 Aftrtrtmnt2WrmUpDslOxdtnCtlystIn "Temperature of engine combustion byproducts entering the warm up Diesel Oxidation Catalyst in exhaust bank 2.";
CM_ BO_ 2566735358 "Aftertreatment 2 Three Way Catalytic Converter";
CM_ SG_ 2566735358 Aftrtrtmnt2ThrWyCtlytcCnvrtrDffP "Used to identify the applicable J1939-73 FMI detected in the Three Way Catalytic Converter differential pressure sensor";
CM_ SG_ 2566735358 Aftrtrtmnt2ThrWyCtlytcCnvrtrOtlt "Used to identify the applicable J1939-73 FMI detected in the Three Way Catalytic Converter outlet gas temperature";
CM_ SG_ 2566735358 Aftrtrtmnt2ThrWyCtlytcCnvrtrIntk "Used to identify the applicable J1939-73 FMI detected in the Three Way Catalytic Converter intake gas temperature";
CM_ SG_ 2566735358 Aftrtrtmnt2ThrWyCtlytcCnvrt_0000 "Exhaust differential pressure measured between the intake and exhaust of a Three Way Catalytic Converter in exhaust";
CM_ SG_ 2566735358 Aftrtrtmnt2ThrWyCtlytcCnvrt_0001 "Temperature of engine combustion byproducts leaving the Three Way Catalytic Converter in exhaust bank 2.";
CM_ SG_ 2566735358 Aftrtrtmnt2ThrWyCtlytcCnvrt_0002 "Temperature of engine combustion byproducts entering the Three Way Catalytic Converter in exhaust bank 2.";
CM_ BO_ 2365393662 "Aftertreatment 2 Outlet Gas NOx Sensor correction data 2";
CM_ SG_ 2365393662 Aftrtrtmnt2OtltGsNOxSnsrNH3Crrct "Correction of NH3 at the NOx-signal to correct (recalculate) sensor signal on the Engine ECU side.";
CM_ SG_ 2365393662 Aftrtrtmnt2OtltGsNOxSnsrNO2Crrct "Correction of NO2 at the NOx-signal to correct (recalculate) sensor signal on the Engine ECU side.";
CM_ SG_ 2365393662 Aftrtrtmnt2OtltGsNOxSnsrCrrctnOf "Correction of pressure NOx-signal to correct (recalculate) sensor signal on the Engine ECU side.";
CM_ SG_ 2365393662 Aftrtrtmnt2OtltGsNOxSnsrCrr_0000 "Correction of pressure Lambda-signal to correct (recalculate) sensor signal on the Engine ECU side.";
CM_ BO_ 2365393918 "Aftertreatment 2 Outlet Gas NOx Sensor correction data";
CM_ SG_ 2365393918 Aftrtrtmnt2OtltGsNOxSnsrNwPrtDvt "New part deviation NOx_Offset to correct (recalculate) sensor signal on the Engine ECU side.";
CM_ SG_ 2365393918 Aftrtrtmnt2OtltGsNOxSnsrNwP_0000 "New part deviation NOx_Gain to correct (recalculate) sensor signal on the Engine ECU side.";
CM_ SG_ 2365393918 Aftrtrtmnt2OtltGsNOxSnsrHtrRtio "Heater ratio to determine temperature at sensor tip.";
CM_ BO_ 2365394174 "Aftertreatment 2 Intake Gas NOx Sensor correction data 2";
CM_ SG_ 2365394174 Aftrtrtmnt2IntkGsNOxSnsrNH3Crrct "Correction of NH3 at the NOx-signal to correct (recalculate) sensor signal on the Engine ECU side.";
CM_ SG_ 2365394174 Aftrtrtmnt2IntkGsNOxSnsrNO2Crrct "Correction of NO2 at the NOx-signal to correct (recalculate) sensor signal on the Engine ECU side.";
CM_ SG_ 2365394174 Aftrtrtmnt2IntkGsNOxSnsrCrrctnOf "Correction of pressure NOx-signal to correct (recalculate) sensor signal on the Engine ECU side.";
CM_ SG_ 2365394174 Aftrtrtmnt2IntkGsNOxSnsrCrr_0000 "Correction of pressure Lambda-signal to correct (recalculate) sensor signal on the Engine ECU side.";
CM_ BO_ 2365394430 "Aftertreatment 2 Intake Gas NOx Sensor correction data";
CM_ SG_ 2365394430 Aftrtrtmnt2IntkGsNOxSnsrNwPrtDvt "New part deviation NOx_Offset to correct (recalculate) sensor signal on the Engine ECU side.";
CM_ SG_ 2365394430 Aftrtrtmnt2IntkGsNOxSnsrNwP_0000 "New part deviation NOx_Gain to correct (recalculate) sensor signal on the Engine ECU side.";
CM_ SG_ 2365394430 Aftrtrtmnt2IntkGsNOxSnsrHtrRtio "Heater ratio to determine temperature at sensor tip.";
CM_ BO_ 2566735102 "Aftertreatment 2 Fuel Control 2";
CM_ SG_ 2566735102 Aftertreatment2FuelPress2Ctrl "Indicates how the device is controlling the aftertreatment 2 fuel pressure 2 regulating control valve.";
CM_ SG_ 2566735102 Aftrtrtmnt2FlFlwDvrterValveCtrl "Indicates how the device is controlling the aftertreatment 2 fuel flow diverter valve.";
CM_ SG_ 2566735102 Aftrtreatment2FuelPumpRelayCtrl "Indicates how the device is controlling the aftertreatment 2 fuel pump relay.";
CM_ SG_ 2566735102 Aftertreatment2FuelPress2 "Second fuel pressure measurement for the aftertreatment 2 system.";
CM_ BO_ 2157313790 "Aftertreatment 2 Diesel Particulate Filter Soot Sensor Calibration";
CM_ SG_ 2157313790 Aftrtrtmnt2DslPrtcltFltrStStndrd "Calibration offset for the soot standard deviation for Aftertreatment 2 Diesel Particulate Filter soot sensor.";
CM_ SG_ 2157313790 Aftrtrtmnt2DslPrtcltFltrStMnClbO "Calibration offset for the soot Mean for Aftertreatment 2 Diesel Particulate Filter soot sensor.";
CM_ BO_ 2566724350 "Aftertreatment 1 Warm Up Diesel Oxidation Catalyst Information";
CM_ SG_ 2566724350 Aftrtrtmnt1WrmUpDslOxdtnCtlystOt "This is the temperature measured at the outlet of the warm up oxidation catalytic converter in exhaust bank 1.";
CM_ SG_ 2566724350 Aftrtrtmnt1WrmUpDslOxdtnCtlystIn "This is the temperature measured at the intake of the warm up oxidation catalytic converter in exhaust bank 1.";
CM_ BO_ 2566735614 "Aftertreatment 1 Three Way Catalytic Converter";
CM_ SG_ 2566735614 Aftrtrtmnt1ThrWyCtlytcCnvrtrDffP "Used to identify the applicable J1939-73 FMI detected in the Three Way Catalytic Converter differential pressure sensor";
CM_ SG_ 2566735614 Aftrtrtmnt1ThrWyCtlytcCnvrtrOtlt "Used to identify the applicable J1939-73 FMI detected in the Three Way Catalytic Converter outlet gas temperature";
CM_ SG_ 2566735614 Aftrtrtmnt1ThrWyCtlytcCnvrtrIntk "Used to identify the applicable J1939-73 FMI detected in the Three Way Catalytic Converter intake gas temperature";
CM_ SG_ 2566735614 Aftrtrtmnt1ThrWyCtlytcCnvrt_0000 "Exhaust differential pressure measured between the intake and exhaust of a Three Way Catalytic Converter in exhaust";
CM_ SG_ 2566735614 Aftrtrtmnt1ThrWyCtlytcCnvrt_0001 "Temperature of engine combustion byproducts leaving the Three Way Catalytic Converter in exhaust bank 1.";
CM_ SG_ 2566735614 Aftrtrtmnt1ThrWyCtlytcCnvrt_0002 "Temperature of engine combustion byproducts entering the Three Way Catalytic Converter in exhaust bank 1.";
CM_ BO_ 2566805246 "Aftertreatment 1 SCR Reagent Tank 1 Information";
CM_ SG_ 2566805246 Aftrtrtmnt1SCRCtlystRgntTnk1HtrP "Used to identify the applicable J1939-73 FMI detected in the SCR catalyst reagent tank 1 heater, by the manufacturer's";
CM_ SG_ 2566805246 Aftrtrtmnt1SCRCtalystTankHeater "Percentage of heating applied to the aftertreatment 1 catalyst tank heater.";
CM_ SG_ 2566805246 AftrtrtmntSCROprtrIndcmntSvrity "The severity of operator inducement for anomolies with the SCR system, such as tampering, low DEF quality, and DEF";
CM_ SG_ 2566805246 Aftrtrtmnt1SCRCtlystRgntTnk1TmpP "Used to identify the applicable J1939-73 FMI detected in the SCR catalyst reagent tank 1 temperature, by the";
CM_ SG_ 2566805246 Aftrtrtmnt1DEFTnkLwLvlIndicator "The desired illumination of the driver's warning indicator for diesel exhaust fluid (DEF) tank low level.";
CM_ SG_ 2566805246 Aftrtrtmnt1SCRCtlystTnkLvlPrlmnr "Used to identify the applicable J1939-73 FMI that applies to the most significant failure of the catalyst tank level sensor.";
CM_ SG_ 2566805246 Aftrtrtmnt1SCRCtalystTankLevel2 "The measure of the reagent level in the catalyst tank.";
CM_ SG_ 2566805246 Aftrtrtment1SCRCatalystTankTemp "Temperature of the reagent in the storage tank.";
CM_ SG_ 2566805246 Aftrtrtmnt1SCRCatalystTankLevel "A special catalyst uses a chemical reagent to reach legal requirement for NOX emissions.";
CM_ BO_ 2566804992 "Aftertreatment 1 SCR Reagent Tank 1 Information";
CM_ SG_ 2566804992 Aftrtrtmnt1SCRCtlystRgntTnk1HtrP "Used to identify the applicable J1939-73 FMI detected in the SCR catalyst reagent tank 1 heater, by the manufacturer's";
CM_ SG_ 2566804992 Aftrtrtmnt1SCRCtalystTankHeater "Percentage of heating applied to the aftertreatment 1 catalyst tank heater.";
CM_ SG_ 2566804992 AftrtrtmntSCROprtrIndcmntSvrity "The severity of operator inducement for anomolies with the SCR system, such as tampering, low DEF quality, and DEF";
CM_ SG_ 2566804992 Aftrtrtmnt1SCRCtlystRgntTnk1TmpP "Used to identify the applicable J1939-73 FMI detected in the SCR catalyst reagent tank 1 temperature, by the";
CM_ SG_ 2566804992 Aftrtrtmnt1DEFTnkLwLvlIndicator "The desired illumination of the driver's warning indicator for diesel exhaust fluid (DEF) tank low level.";
CM_ SG_ 2566804992 Aftrtrtmnt1SCRCtlystTnkLvlPrlmnr "Used to identify the applicable J1939-73 FMI that applies to the most significant failure of the catalyst tank level sensor.";
CM_ SG_ 2566804992 Aftrtrtmnt1SCRCtalystTankLevel2 "The measure of the reagent level in the catalyst tank.";
CM_ SG_ 2566804992 Aftrtrtment1SCRCatalystTankTemp "Temperature of the reagent in the storage tank.";
CM_ SG_ 2566804992 Aftrtrtmnt1SCRCatalystTankLevel "A special catalyst uses a chemical reagent to reach legal requirement for NOX emissions.";
CM_ BO_ 2365394686 "Aftertreatment 1 Outlet Gas NOx Sensor correction data 2";
CM_ SG_ 2365394686 Aftrtrtmnt1OtltGsNOxSnsrNH3Crrct "Correction of NH3 at the NOx-signal to correct (recalculate) sensor signal on the Engine ECU side.";
CM_ SG_ 2365394686 Aftrtrtmnt1OtltGsNOxSnsrNO2Crrct "Correction of NO2 at the NOx-signal to correct (recalculate) sensor signal on the Engine ECU side.";
CM_ SG_ 2365394686 Aftrtrtmnt1OtltGsNOxSnsrCrrctnOf "Correction of pressure NOx-signal to correct (recalculate) sensor signal on the Engine ECU side.";
CM_ SG_ 2365394686 Aftrtrtmnt1OtltGsNOxSnsrCrr_0000 "Correction of pressure Lambda-signal to correct (recalculate) sensor signal on the Engine ECU side.";
CM_ BO_ 2365394942 "Aftertreatment 1 Outlet Gas NOx Sensor correction data";
CM_ SG_ 2365394942 Aftrtrtmnt1OtltGsNOxSnsrNwPrtDvt "New part deviation NOx_Offset to correct (recalculate) sensor signal on the Engine ECU side.";
CM_ SG_ 2365394942 Aftrtrtmnt1OtltGsNOxSnsrNwP_0000 "New part deviation NOx_Gain to correct (recalculate) sensor signal on the Engine ECU side.";
CM_ SG_ 2365394942 Aftrtrtmnt1OtltGsNOxSnsrHtrRtio "Heater ratio to determine temperature at sensor tip.";
CM_ BO_ 2365395198 "Aftertreatment 1 Intake Gas NOx Sensor correction data 2";
CM_ SG_ 2365395198 Aftrtrtmnt1IntkGsNOxSnsrNH3Crrct "Correction of NH3 at the NOx-signal to correct (recalculate) sensor signal on the Engine ECU side.";
CM_ SG_ 2365395198 Aftrtrtmnt1IntkGsNOxSnsrNO2Crrct "Correction of NO2 at the NOx-signal to correct (recalculate) sensor signal on the Engine ECU side.";
CM_ SG_ 2365395198 Aftrtrtmnt1IntkGsNOxSnsrCrrctnOf "Correction of pressure NOx-signal to correct (recalculate) sensor signal on the Engine ECU side.";
CM_ SG_ 2365395198 Aftrtrtmnt1IntkGsNOxSnsrCrr_0000 "Correction of pressure Lambda-signal to correct (recalculate) sensor signal on the Engine ECU side.";
CM_ BO_ 2365395454 "Aftertreatment 1 Intake Gas NOx Sensor correction data";
CM_ SG_ 2365395454 Aftrtrtmnt1IntkGsNOxSnsrNwPrtDvt "New part deviation NOx_Offset to correct (recalculate) sensor signal on the Engine ECU side.";
CM_ SG_ 2365395454 Aftrtrtmnt1IntkGsNOxSnsrNwP_0000 "New part deviation NOx_Gain to correct (recalculate) sensor signal on the Engine ECU side.";
CM_ SG_ 2365395454 Aftrtrtmnt1IntkGsNOxSnsrHtrRtio "Heater ratio to determine temperature at sensor tip.";
CM_ BO_ 2157248254 "Aftertreatment 1 Diesel Particulate Filter Soot Sensor Calibration";
CM_ SG_ 2157248254 Aftrtrtmnt1DslPrtcltFltrStStndrd "Calibration offset for the soot standard deviation for Aftertreatment 1 Diesel Particulate Filter soot sensor.";
CM_ SG_ 2157248254 Aftrtrtmnt1DslPrtcltFltrStMnClbO "Calibration offset for the soot Mean for Aftertreatment 1 Diesel Particulate Filter soot sensor.";
CM_ BO_ 2566711806 "Armrest Switch Matrix Commands";
CM_ SG_ 2566711806 ArmrestSwitchMatrix2Switch2 "Second switch input matrix for the second module located in the armrest";
CM_ SG_ 2566711806 ArmrestSwitchMatrix2Switch1 "Switch input matrix for the second module located in the armrest";
CM_ SG_ 2566711806 ArmrestSwitchMatrixSwitch2 "Second switch input matrix for the module located in the armrest";
CM_ SG_ 2566711806 ArmrestSwitchMatrixSwitch1 "Switch input matrix for the module located in the armrest";
CM_ BO_ 2364549886 "Angular Rate Information";
CM_ SG_ 2364549886 AngularRateMeasurementLatency "The estimated measurement latency of the measurement.";
CM_ SG_ 2364549886 YawRateExRangeFigureOfMerit "Figure of merit for yaw angle measurement.";
CM_ SG_ 2364549886 RollRateExRangeFigureOfMerit "Figure of merit for roll angle measurement.";
CM_ SG_ 2364549886 PitchRateExRangeFigureOfMerit "Figure of merit for pitch angle measurement.";
CM_ SG_ 2364549886 YawRateExRange "Yaw rate is the rate-of-change of the yaw angle over time.";
CM_ SG_ 2364549886 RollRateExRange "Roll rate is the rate-of-change of the roll angle over time.";
CM_ SG_ 2364549886 PitchRateExRange "Pitch rate is the rate-of-change of the pitch angle over time, where the pitch angle vector is in the direction of travel of the";
CM_ BO_ 2566712318 "Aftertreatment 2 NOx Adsorber Information";
CM_ SG_ 2566712318 Aftrtrtmnt2NOxAdsrbrDSOxRgnrtnSt "Indicates whether the NOx adsorber deSOx regeneration in the second aftertreatment system is active or inactive";
CM_ SG_ 2566712318 Aftrtrtmnt2NOxAdsrbrDNOxRgnrtnSt "Indicates whether the NOx adsorber deNOx regeneration in the second aftertreatment system is active or inactive";
CM_ BO_ 2566712574 "Aftertreatment 1 NOx Adsorber Information";
CM_ SG_ 2566712574 Aftrtrtmnt1NOxAdsrbrDSOxRgnrtnSt "Indicates whether the NOx adsorber deSOx regeneration in the first aftertreatment system is active or inactive";
CM_ SG_ 2566712574 Aftrtrtmnt1NOxAdsrbrDNOxRgnrtnSt "Indicates whether the NOx adsorber deNOx regeneration in the first aftertreatment system is active or inactive";
CM_ BO_ 2164078590 "Aftertreatment 2 SCR Service Information";
CM_ SG_ 2164078590 Aftrtrtmnt2SCRCtlystCnvrsnEffcnc "The SCR catalyst conversion efficiency percentage.";
CM_ SG_ 2164078590 Aftrtrtmnt2SCRCmddCtlystRgntCnsm "This parameter transmits the amount of reagent that the emissions control system has requested to be used, averaged";
CM_ SG_ 2164078590 Aftrtrtmnt2SCRAvrgCtlystRgntCnsm "Measured use of reagent by a Selective Catalytic Reduction system for exhaust emission control, averaged over the";
CM_ BO_ 2566731006 "Aftertreatment 2 SCR Reagant Tank 2 Information";
CM_ SG_ 2566731006 Aftrtrtmnt2SCRCtlystRgntTnk2HtrP "Used to identify the applicable J1939-73 FMI detected in the SCR catalyst reagent tank 2 heater, by the manufacturer's";
CM_ SG_ 2566731006 Aftrtrtmnt2SCRCtlystRgntTnk2Htr "The SCR catalyst reagent tank 2 heater percentage for aftertreatment system 1 (exhaust bank 1).";
CM_ SG_ 2566731006 Aftrtrtmnt2SCRRgntTnk2TmpPrlmnry "Used to identify the applicable J1939-73 FMI detected in the SCR catalyst reagent tank 2 temperature, by the";
CM_ SG_ 2566731006 Aftrtrtmnt2SCRCtlystRgntTnk2LvlP "Used to identify the applicable J1939-73 FMI detected in the SCR catalyst reagent tank 2 level, by the manufacturer's";
CM_ SG_ 2566731006 Aftrtrtmnt2SCRCtlystRgntTnk2Lvl2 "The SCR catalyst reagent tank 2 level height in mm for aftertreatment system 2 (exhaust bank 2).";
CM_ SG_ 2566731006 Aftrtrtmnt2SCRCtlystRgntTnk2Tmp "The SCR catalyst reagent tank 2 temperature for aftertreatment system 2 (exhaust bank 2).";
CM_ SG_ 2566731006 Aftrtrtmnt2SCRCtlystRgntTnk2Lvl "The SCR catalyst reagent tank 2 level percentage for aftertreatment system 2 (exhaust bank 2).";
CM_ BO_ 2566731262 "Aftertreatment 2 SCR Reagant Tank 1 Information";
CM_ SG_ 2566731262 Aftrtrtmnt2SCRCtlystRgntTnk1HtrP "Used to identify the applicable J1939-73 FMI detected in the SCR catalyst reagent tank 1 heater, by the manufacturer's";
CM_ SG_ 2566731262 Aftrtrtmnt2SCRCtalystTankHeater "Percentage of heating applied to the aftertreatment 2 catalyst tank heater.";
CM_ SG_ 2566731262 Aftrtrtmnt2SCRCtlystRgntTnk1TmpP "Used to identify the applicable J1939-73 FMI detected in the SCR catalyst reagent tank 1 temperature, by the";
CM_ SG_ 2566731262 Aftrtrtmnt2SCRCtlystTnkLvlPrlmnr "Used to identify the applicable J1939-73 FMI that applies to the most significant failure of the catalyst tank level sensor.";
CM_ SG_ 2566731262 Aftrtrtmnt2SCRCtalystTankLevel2 "The measure of the reagent level in the catalyst tank.";
CM_ SG_ 2566731262 Aftrtrtment2SCRCatalystTankTemp "Temperature of the reagent in the storage tank.";
CM_ SG_ 2566731262 Aftrtrtmnt2SCRCatalystTankLevel "A special catalyst uses chemical substance to reach legal requirement for NOX emissions.";
CM_ BO_ 2566730750 "Aftertreatment 2 SCR Reagent Supply Information";
CM_ SG_ 2566730750 Aftrtrtmnt2SCRCtlystRgntTnkDrnVl "Commanded percentage of maximum Aftertreatment 2 SCR Catalyst Reagent Tank Drain Valve opening.";
CM_ SG_ 2566730750 Aftrtrtmnt2SCRCtlystRgntPmpStte "State of aftertreatment 2 SCR Catalyst Reagent dosing pump.";
CM_ SG_ 2566730750 Aftrtrtmnt2SCRCtlystRgntTnkFllVl "Commanded percentage of maximum Aftertreatment 2 SCR Catalyst Reagent Tank Fill Valve opening.";
CM_ SG_ 2566730750 Aftrtrtmnt2SCRCtlystRgntRtrnVlv "Command to the valve which determines whether the reagent is delivered to the injector or is routed back to the reagent";
CM_ SG_ 2566730750 Aftrtrtmnt2SCRCtlystRgntPmpDrvPr "The percent (command) sent to the motor to control the speed of the reagent pump.";
CM_ SG_ 2566730750 Aftrtrtmnt2SCRCtlystRgntPmpMtrSp "Rotational speed of the motor driving a pump for reagent used in an aftertreatment system.";
CM_ BO_ 2566731518 "Aftertreatment 2 SCR Reagent Information";
CM_ SG_ 2566731518 Aftrtrtmnt2SCRCtlystReagentType "This parameter indicates what reagent is in the tank.";
CM_ SG_ 2566731518 Aftrtrtmnt2SCRCtlystRgntPrprtsPr "Used to identify the applicable J1939-73 FMI that applies to the most significant failure of the catalyst reagent properties";
CM_ SG_ 2566731518 Aftrtrtmnt2SCRCtlystRgntTmp2Prlm "Used to identify the applicable J1939-73 FMI that applies to the most significant failure of the catalyst temperature sensor.";
CM_ SG_ 2566731518 Aftrtrtmnt2SCRCtlystRgntCndctvty "A measure of the conductivity of the reagent or fluid at the sensor.";
CM_ SG_ 2566731518 Aftrtrtmnt2SCRCtlystRgntCncntrtn "A measure of the concentration of urea in water.";
CM_ SG_ 2566731518 Aftrtrtmnt2SCRCtlystRagentTemp2 "Temperature of the catalyst reagent at the device measuring reagent quality";
CM_ BO_ 2566732030 "Aftertreatment 2 SCR Exhaust Gas Temperature";
CM_ SG_ 2566732030 Aftrtrtmnt2SCRCtlystOtltGsTmpPrl "Used to identify the applicable J1939-73 FMI detected in the SCR catalyst outlet gas temperature sensor by the";
CM_ SG_ 2566732030 Aftrtrtmnt2SCRCtlystOtltGasTemp "Temperature of engine combustion byproducts leaving the SCR catalyst exhaust in exhaust bank 2.";
CM_ SG_ 2566732030 Aftrtrtmnt2SCRCtlystIntkGsTmpPrl "Used to identify the applicable J1939-73 FMI detected in the SCR catalyst intake gas temperature sensor by the";
CM_ SG_ 2566732030 Aftrtrtmnt2SCRCtlystIntkGasTemp "Temperature of engine combustion byproducts entering the SCR catalyst in exhaust bank 2.";
CM_ BO_ 2566732286 "Aftertreatment 2 SCR Exhaust Gas Pressures";
CM_ SG_ 2566732286 Aftrtrtmnt2SCRCtlystExhstGsDffPr "Used to identify the applicable J1939-73 FMI detected in the SCR catalyst differential pressure sensor by the";
CM_ SG_ 2566732286 Aftrtrtmnt2SCRCtlystExhstGs_0000 "Exhaust differential pressure measured between the intake and exhaust of a SCR catalyst in exhaust bank 2.";
CM_ BO_ 2164079358 "Aftertreatment 2 SCR Dosing System Requests 2";
CM_ SG_ 2164079358 Aftrtrtmnt2SCRCtlystTnk2HterCmd "This is the command for the Aftertreatment 2 SCR Catalyst Tank 2 Heater.";
CM_ SG_ 2164079358 Aftrtrtmnt2SCRCtlystTnkHaterCmd "Command for the Aftertreatment 2 SCR Catalyst Tank Heater.";
CM_ SG_ 2164079358 Aftrtrtmnt2SCRCtlystRgntLnHter4 "The SCR catalyst reagent line heater 4 request for aftertreatment system 2 (exhaust bank 2).";
CM_ SG_ 2164079358 Aftrtrtmnt2SCRCtlystRgntLnHter3 "The SCR catalyst reagent line heater 3 request for aftertreatment system 2 (exhaust bank 2).";
CM_ SG_ 2164079358 Aftrtrtmnt2SCRCtlystRgntLnHter2 "The SCR catalyst reagent line heater 2 request for aftertreatment system 2 (exhaust bank 2).";
CM_ SG_ 2164079358 Aftrtrtmnt2SCRCtlystRgntLnHter1 "The SCR catalyst reagent line heater 1 request for aftertreatment system 2 (exhaust bank 2).";
CM_ SG_ 2164079358 Aftrtrtmnt2SCRDserHeatingModeRq "Used if multiple heater modes are available in the Doser.";
CM_ SG_ 2164079358 Aftrtrtmnt2SCRDsrFltSpprssionRq "Used if external devices can warn of conditions that require suppression of potential faults in the doser due to";
CM_ BO_ 2364549118 "Aftertreatment 2 SCR Dosing System Requests 1";
CM_ SG_ 2364549118 Aftrtrtmnt2SCRRqdRgntQnttyFrIntg "Represents the command for the reducing agent quantity integrator in the dosing control unit";
CM_ SG_ 2364549118 Aftrtratment2SCRSystemRqedState "Requested state of SCR system for aftertreatment system 2 (exhaust bank 2).";
CM_ SG_ 2364549118 Aftrtrtmnt2SCRRqdDsngRgntQntity "Actual requested dosing quantity of catalyst reagent";
CM_ BO_ 2566732798 "Aftertreatment 2 SCR Dosing System Information 2";
CM_ SG_ 2566732798 Aftrtrtmnt2SCRCtlystRgntLnHtr4Pr "Used to identify the applicable J1939-73 FMI detected in the SCR catalyst reagent line heater 4, by the manufacturer's";
CM_ SG_ 2566732798 Aftrtrtmnt2SCRCtlystRgntLnHtr4St "The SCR catalyst reagent line heater 4 state for aftertreatment system 2 (exhaust bank 2).";
CM_ SG_ 2566732798 Aftrtrtmnt2SCRCtlystRgntLnHtr3Pr "Used to identify the applicable J1939-73 FMI detected in the SCR catalyst reagent line heater 3, by the manufacturer's";
CM_ SG_ 2566732798 Aftrtrtmnt2SCRCtlystRgntLnHtr3St "The SCR catalyst reagent line heater 3 state for aftertreatment system 2 (exhaust bank 2).";
CM_ SG_ 2566732798 Aftrtrtmnt2SCRCtlystRgntLnHtr2Pr "Used to identify the applicable J1939-73 FMI detected in the SCR catalyst reagent line heater 2, by the manufacturer's";
CM_ SG_ 2566732798 Aftrtrtmnt2SCRCtlystRgntLnHtr2St "The SCR catalyst reagent line heater 2 state for aftertreatment system 2 (exhaust bank 2).";
CM_ SG_ 2566732798 Aftrtrtmnt2SCRCtlystRgntLnHtr1Pr "Used to identify the applicable J1939-73 FMI detected in the SCR catalyst reagent line heater 1, by the manufacturer's";
CM_ SG_ 2566732798 Aftrtrtmnt2SCRCtlystRgntLnHtr1St "The SCR catalyst reagent line heater 1 state for aftertreatment system 2 (exhaust bank 2).";
CM_ SG_ 2566732798 Aftrtrtmnt2SCRFedbackCtrlStatus "The SCR feedback control status (open/closed loop) for aftertreatment system 2 (exhaust bank 2).";
CM_ SG_ 2566732798 Aftrtrtmnt2SCRDsngVlvExhstTmpRdc "Protection request for the dosing valve of the SCR-system to prevent overheating";
CM_ SG_ 2566732798 Aftrtrtmnt2SCRDosingReagentTemp "The SCR dosing reagent temperature (measured closest to dosing valve) for aftertreatment system 2 (exhaust bank 2).";
CM_ SG_ 2566732798 Aftrtrtmnt2SCRDsngArAssistValve "The position of the valve used to regulate the air supply of an air assist SCR dosing system for an engine.";
CM_ SG_ 2566732798 Aftrtrtmnt2SCRDsngArAssstAbsPrss "The SCR dosing system air assist absolute pressure for aftertreatment system 2 (exhaust bank 2).";
CM_ BO_ 2364548862 "Aftertreatment 2 SCR Dosing System Information 1";
CM_ SG_ 2364548862 Aftrtrtmnt2SCRDsngRgentAbsPress "The SCR dosing reagent absolute pressure (measured closest to dosing valve) for aftertreatment system 2 (exhaust bank";
CM_ SG_ 2364548862 Aftrtrtmnt2SCRActlRgntQnttyOfInt "The SCR requested reagent integrator total quantity for aftertreatment system 2 (exhaust bank 2).";
CM_ SG_ 2364548862 Aftertreatment2SCRSystemState "Actual state of SCR system";
CM_ SG_ 2364548862 Aftrtrtmnt2SCRActlDsngRgntQntty "Actual reducing agent quantity of SCR system.";
CM_ BO_ 2364549374 "Aftertreatment 2 SCR Ammonia Information";
CM_ SG_ 2364549374 Aftrtrtmnt2OtltNH3GsSnsrHtrCtrl "Indicates the heater status in the warm-up process.";
CM_ SG_ 2364549374 Aftrtrtmnt2OtltNH3GsSnsrHtrPrlmn "Used to identify the applicable J1939-73 FMI detected in the heater of the outlet NH3 exhaust gas sensor by the";
CM_ SG_ 2364549374 Aftrtrtmnt2OtltNH3GsSnsorAtTemp "Indicates that the heater element of the aftertreatment outlet NH3 gas sensor is within the manufacturer's specified range";
CM_ SG_ 2364549374 Aftrtrtmnt2OtltNH3GsSnsrPwrInRng "Indicates that the power supplied to the aftertreatment outlet NH3 gas sensor is within the manufacturer's specification in";
CM_ SG_ 2364549374 Aftrtrtmnt2OtltNH3ReadingStable "Indicates that the NH3 reading of the aftertreatment outlet NH3 sensor is stable as determined by the manufacturer's";
CM_ SG_ 2364549374 Aftrtrtmnt2OtltNH3SnsrPrlmnryFMI "Used to identify the applicable J1939-73 FMI detected in the aftertreatment outlet NH3 sensor by the manufacturer's";
CM_ SG_ 2364549374 Aftertreatment2OutletNH3 "The amount of NH3 in the exhaust exiting the aftertreatment system measured by a NH3 sensor at the aftertreatment";
CM_ BO_ 2566726142 "Aftertreatment 2 Gas Oxidation Catalyst";
CM_ SG_ 2566726142 Aftrtrtmnt2GsOxdtnCtlystDffPrssP "Used to identify the applicable J1939-73 FMI detected in the gas oxidation catalyst differential pressure sensor by the";
CM_ SG_ 2566726142 Aftrtrtmnt2GsOxdtnCtlystOtltGsTm "Used to identify the applicable J1939-73 FMI detected in the gas oxidation catalyst outlet gas temperature sensor by the";
CM_ SG_ 2566726142 Aftrtrtmnt2GsOxdtnCtlystIntkGsTm "Used to identify the applicable J1939-73 FMI detected in the gas oxidation catalyst intake gas temperature sensor by the";
CM_ SG_ 2566726142 Aftrtrtmnt2GsOxdtnCtlystDffPrss "Exhaust differential pressure measured between the intake and exhaust of the gas oxidation catalyst in exhaust bank 2.";
CM_ SG_ 2566726142 Aftrtrtmnt2GsOxdtnCtlystOtl_0000 "Temperature of engine combustion byproducts leaving the gas oxidation catalyst in exhaust bank 2.";
CM_ SG_ 2566726142 Aftrtrtmnt2GsOxdtnCtlystInt_0000 "Temperature of engine combustion byproducts entering the gas oxidation catalyst in exhaust bank 2.";
BA_DEF_ SG_  "SigType" ENUM  "Default","Range","RangeSigned","ASCII","Discrete","Control","ReferencePGN","DTC","StringDelimiter","StringLength","StringLengthControl";
BA_DEF_ SG_  "GenSigStartValue" INT 0 10000;
BA_DEF_ SG_  "GenSigSendType" ENUM  "Cyclic","OnWrite","reserved","OnChange","reserved","reserved","reserved","NoSigSendType";
BA_DEF_ SG_  "GenSigILSupport" ENUM  "Yes","No";
BA_DEF_ SG_  "GenSigEVName" STRING ;
BA_DEF_ SG_  "SPN" INT 0 524287;
BA_DEF_ BO_  "GenMsgStartDelayTime" INT 0 100000;
BA_DEF_ BO_  "GenMsgILSupport" ENUM  "Yes","No";
BA_DEF_ BO_  "GenMsgRequestable" INT 0 1;
BA_DEF_ BO_  "GenMsgSendType" ENUM  "cyclic","reserved","cyclicIfActive","reserved","reserved","reserved","reserved","reserved","noMsgSendType";
BA_DEF_ BO_  "VFrameFormat" ENUM  "StandardCAN","ExtendedCAN","reserved","J1939PG";
BA_DEF_ BO_  "GenMsgCycleTime" INT 0 3600000;
BA_DEF_ SG_  "SystemSignalLongSymbol" STRING ;
BA_DEF_DEF_  "SigType" "Default";
BA_DEF_DEF_  "GenSigStartValue" 0;
BA_DEF_DEF_  "GenSigSendType" "NoSigSendType";
BA_DEF_DEF_  "GenSigILSupport" "Yes";
BA_DEF_DEF_  "GenSigEVName" "Env@Nodename_@Signame";
BA_DEF_DEF_  "SPN" 0;
BA_DEF_DEF_  "GenMsgStartDelayTime" 0;
BA_DEF_DEF_  "GenMsgILSupport" "Yes";
BA_DEF_DEF_  "GenMsgRequestable" 1;
BA_DEF_DEF_  "GenMsgSendType" "noMsgSendType";
BA_DEF_DEF_  "VFrameFormat" "J1939PG";
BA_DEF_DEF_  "GenMsgCycleTime" 0;
BA_DEF_DEF_  "SystemSignalLongSymbol" "";
BA_ "GenMsgCycleTime" BO_ 2566844695 100;
BA_ "GenMsgSendType" BO_ 2566844695 0;
BA_ "GenMsgCycleTime" BO_ 2566775294 1000;
BA_ "GenMsgSendType" BO_ 2566775294 0;
BA_ "GenMsgCycleTime" BO_ 2566803710 1000;
BA_ "GenMsgSendType" BO_ 2566803710 0;
BA_ "GenMsgCycleTime" BO_ 2365476881 1000;
BA_ "GenMsgSendType" BO_ 2365476881 0;
BA_ "GenMsgCycleTime" BO_ 2566714878 1000;
BA_ "GenMsgSendType" BO_ 2566714878 0;
BA_ "GenMsgCycleTime" BO_ 2566714622 1000;
BA_ "GenMsgSendType" BO_ 2566714622 0;
BA_ "GenMsgCycleTime" BO_ 2566715390 1000;
BA_ "GenMsgSendType" BO_ 2566715390 0;
BA_ "GenMsgCycleTime" BO_ 2566715134 1000;
BA_ "GenMsgSendType" BO_ 2566715134 0;
BA_ "GenMsgCycleTime" BO_ 2499614718 250;
BA_ "GenMsgSendType" BO_ 2499614718 0;
BA_ "GenMsgCycleTime" BO_ 2566722814 1000;
BA_ "GenMsgSendType" BO_ 2566722814 0;
BA_ "GenMsgCycleTime" BO_ 2566723070 1000;
BA_ "GenMsgSendType" BO_ 2566723070 0;
BA_ "GenMsgCycleTime" BO_ 2566712830 500;
BA_ "GenMsgSendType" BO_ 2566712830 0;
BA_ "GenMsgCycleTime" BO_ 2566735358 500;
BA_ "GenMsgSendType" BO_ 2566735358 0;
BA_ "GenMsgCycleTime" BO_ 2566735102 500;
BA_ "GenMsgSendType" BO_ 2566735102 0;
BA_ "GenMsgCycleTime" BO_ 2566724350 500;
BA_ "GenMsgSendType" BO_ 2566724350 0;
BA_ "GenMsgCycleTime" BO_ 2566735614 500;
BA_ "GenMsgSendType" BO_ 2566735614 0;
BA_ "GenMsgCycleTime" BO_ 2566805246 1000;
BA_ "GenMsgSendType" BO_ 2566805246 0;
BA_ "GenMsgCycleTime" BO_ 2566804992 1000;
BA_ "GenMsgSendType" BO_ 2566804992 0;
BA_ "GenMsgCycleTime" BO_ 2566711806 100;
BA_ "GenMsgSendType" BO_ 2566711806 0;
BA_ "GenMsgCycleTime" BO_ 2364549886 10;
BA_ "GenMsgSendType" BO_ 2364549886 0;
BA_ "GenMsgCycleTime" BO_ 2566712318 1000;
BA_ "GenMsgSendType" BO_ 2566712318 0;
BA_ "GenMsgCycleTime" BO_ 2566712574 1000;
BA_ "GenMsgSendType" BO_ 2566712574 0;
BA_ "GenMsgCycleTime" BO_ 2566731006 1000;
BA_ "GenMsgSendType" BO_ 2566731006 0;
BA_ "GenMsgCycleTime" BO_ 2566731262 1000;
BA_ "GenMsgSendType" BO_ 2566731262 0;
BA_ "GenMsgCycleTime" BO_ 2566730750 1000;
BA_ "GenMsgSendType" BO_ 2566730750 0;
BA_ "GenMsgCycleTime" BO_ 2566731518 1000;
BA_ "GenMsgSendType" BO_ 2566731518 0;
BA_ "GenMsgCycleTime" BO_ 2566732030 500;
BA_ "GenMsgSendType" BO_ 2566732030 0;
BA_ "GenMsgCycleTime" BO_ 2566732286 500;
BA_ "GenMsgSendType" BO_ 2566732286 0;
BA_ "GenMsgCycleTime" BO_ 2164079358 500;
BA_ "GenMsgSendType" BO_ 2164079358 0;
BA_ "GenMsgCycleTime" BO_ 2364549118 50;
BA_ "GenMsgSendType" BO_ 2364549118 0;
BA_ "GenMsgCycleTime" BO_ 2566732798 500;
BA_ "GenMsgSendType" BO_ 2566732798 0;
BA_ "GenMsgCycleTime" BO_ 2364548862 50;
BA_ "GenMsgSendType" BO_ 2364548862 0;
BA_ "GenMsgCycleTime" BO_ 2364549374 50;
BA_ "GenMsgSendType" BO_ 2364549374 0;
BA_ "GenMsgCycleTime" BO_ 2566726142 500;
BA_ "GenMsgSendType" BO_ 2566726142 0;
BA_ "SPN" SG_ 2566844695 ParkBrakeReleaseInhibitRq 3807;
BA_ "SigType" SG_ 2566844695 ParkBrakeReleaseInhibitRq 4;
BA_ "SPN" SG_ 2566844695 PTOGovernorState 976;
BA_ "SigType" SG_ 2566844695 PTOGovernorState 4;
BA_ "SPN" SG_ 2566844695 EngShutdownOverrideSwitch 1237;
BA_ "SigType" SG_ 2566844695 EngShutdownOverrideSwitch 4;
BA_ "SPN" SG_ 2566844695 EngTestModeSwitch 966;
BA_ "SigType" SG_ 2566844695 EngTestModeSwitch 4;
BA_ "SPN" SG_ 2566844695 EngIdleDecrementSwitch 967;
BA_ "SigType" SG_ 2566844695 EngIdleDecrementSwitch 4;
BA_ "SPN" SG_ 2566844695 EngIdleIncrementSwitch 968;
BA_ "SigType" SG_ 2566844695 EngIdleIncrementSwitch 4;
BA_ "SPN" SG_ 2566844695 CruiseCtrlStates 527;
BA_ "SPN" SG_ 2566844695 CruiseCtrlSetSpeed 86;
BA_ "SigType" SG_ 2566844695 CruiseCtrlSetSpeed 1;
BA_ "SPN" SG_ 2566844695 CruiseCtrlAccelerateSwitch 602;
BA_ "SigType" SG_ 2566844695 CruiseCtrlAccelerateSwitch 4;
BA_ "SPN" SG_ 2566844695 CruiseCtrlResumeSwitch 601;
BA_ "SigType" SG_ 2566844695 CruiseCtrlResumeSwitch 4;
BA_ "SPN" SG_ 2566844695 CruiseCtrlCoastSwitch 600;
BA_ "SigType" SG_ 2566844695 CruiseCtrlCoastSwitch 4;
BA_ "SPN" SG_ 2566844695 CruiseCtrlSetSwitch 599;
BA_ "SigType" SG_ 2566844695 CruiseCtrlSetSwitch 4;
BA_ "SPN" SG_ 2566844695 ClutchSwitch 598;
BA_ "SigType" SG_ 2566844695 ClutchSwitch 4;
BA_ "SPN" SG_ 2566844695 BrakeSwitch 597;
BA_ "SigType" SG_ 2566844695 BrakeSwitch 4;
BA_ "SPN" SG_ 2566844695 CruiseCtrlEnableSwitch 596;
BA_ "SigType" SG_ 2566844695 CruiseCtrlEnableSwitch 4;
BA_ "SPN" SG_ 2566844695 CruiseCtrlActive 595;
BA_ "SigType" SG_ 2566844695 CruiseCtrlActive 4;
BA_ "SPN" SG_ 2566844695 WheelBasedVehicleSpeed 84;
BA_ "SigType" SG_ 2566844695 WheelBasedVehicleSpeed 1;
BA_ "SPN" SG_ 2566844695 CruiseCtrlPauseSwitch 1633;
BA_ "SigType" SG_ 2566844695 CruiseCtrlPauseSwitch 4;
BA_ "SPN" SG_ 2566844695 ParkingBrakeSwitch 70;
BA_ "SigType" SG_ 2566844695 ParkingBrakeSwitch 4;
BA_ "SPN" SG_ 2566844695 TwoSpeedAxleSwitch 69;
BA_ "SigType" SG_ 2566844695 TwoSpeedAxleSwitch 4;
BA_ "SPN" SG_ 2566843902 CruiseCtrlLowSetLimitSpeed 88;
BA_ "SigType" SG_ 2566843902 CruiseCtrlLowSetLimitSpeed 1;
BA_ "SPN" SG_ 2566843902 CruiseCtrlHighSetLimitSpeed 87;
BA_ "SigType" SG_ 2566843902 CruiseCtrlHighSetLimitSpeed 1;
BA_ "SPN" SG_ 2566843902 MaxVehicleSpeedLimit 74;
BA_ "SigType" SG_ 2566843902 MaxVehicleSpeedLimit 1;
BA_ "SPN" SG_ 2566809598 AuxHeaterMaxOutputPower 1690;
BA_ "SigType" SG_ 2566809598 AuxHeaterMaxOutputPower 1;
BA_ "SPN" SG_ 2633940222 TripServiceBrakeApps 993;
BA_ "SigType" SG_ 2633940222 TripServiceBrakeApps 1;
BA_ "SPN" SG_ 2633940222 TripServiceBrakeDistance 992;
BA_ "SigType" SG_ 2633940222 TripServiceBrakeDistance 1;
BA_ "SPN" SG_ 2633940222 TripCompressionBrakeDistance 991;
BA_ "SigType" SG_ 2633940222 TripCompressionBrakeDistance 1;
BA_ "SPN" SG_ 2633940222 TotalCompressionBrakeDistance 990;
BA_ "SigType" SG_ 2633940222 TotalCompressionBrakeDistance 1;
BA_ "SPN" SG_ 2566775294 CbA_CRfrgrntCmprssorOutletPress 2609;
BA_ "SigType" SG_ 2566775294 CbA_CRfrgrntCmprssorOutletPress 1;
BA_ "SPN" SG_ 2566803710 Battery2Temp 1801;
BA_ "SigType" SG_ 2566803710 Battery2Temp 1;
BA_ "SPN" SG_ 2566803710 Battery1Temp 1800;
BA_ "SigType" SG_ 2566803710 Battery1Temp 1;
BA_ "SPN" SG_ 2365476881 Battery2Temp 1801;
BA_ "SigType" SG_ 2365476881 Battery2Temp 1;
BA_ "SPN" SG_ 2365476881 Battery1Temp 1800;
BA_ "SigType" SG_ 2365476881 Battery1Temp 1;
BA_ "SPN" SG_ 2566719486 EngFuelFilterRestrictedLampCmd 5469;
BA_ "SigType" SG_ 2566719486 EngFuelFilterRestrictedLampCmd 4;
BA_ "SPN" SG_ 2566719486 EngAirFilterRestrictionLampCmd 5086;
BA_ "SigType" SG_ 2566719486 EngAirFilterRestrictionLampCmd 4;
BA_ "SPN" SG_ 2566719486 EngIdleManagementActiveLampCmd 5085;
BA_ "SigType" SG_ 2566719486 EngIdleManagementActiveLampCmd 4;
BA_ "SPN" SG_ 2566719486 EngCoolantLevelLowLampCmd 5084;
BA_ "SigType" SG_ 2566719486 EngCoolantLevelLowLampCmd 4;
BA_ "SPN" SG_ 2566719486 EngCoolantTempHighLampCmd 5083;
BA_ "SigType" SG_ 2566719486 EngCoolantTempHighLampCmd 4;
BA_ "SPN" SG_ 2566719486 EngOilPressLowLampCmd 5082;
BA_ "SigType" SG_ 2566719486 EngOilPressLowLampCmd 4;
BA_ "SPN" SG_ 2566719486 CmprssnBrkEnblSwtchIndctrLmpCmd 3987;
BA_ "SigType" SG_ 2566719486 CmprssnBrkEnblSwtchIndctrLmpCmd 4;
BA_ "SPN" SG_ 2566719486 EngBrakeActiveLampCmd 5081;
BA_ "SigType" SG_ 2566719486 EngBrakeActiveLampCmd 4;
BA_ "SPN" SG_ 2566719486 OBDMalfunctionIndicatorLampCmd 5080;
BA_ "SigType" SG_ 2566719486 OBDMalfunctionIndicatorLampCmd 4;
BA_ "SPN" SG_ 2566719486 EngRedStopLampCmd 5079;
BA_ "SigType" SG_ 2566719486 EngRedStopLampCmd 4;
BA_ "SPN" SG_ 2566719486 EngAmberWarningLampCmd 5078;
BA_ "SigType" SG_ 2566719486 EngAmberWarningLampCmd 4;
BA_ "SPN" SG_ 2566719486 EngProtectLampCmd 5077;
BA_ "SigType" SG_ 2566719486 EngProtectLampCmd 4;
BA_ "SPN" SG_ 2633832702 RearCollisionSensor4Type 4933;
BA_ "SigType" SG_ 2633832702 RearCollisionSensor4Type 4;
BA_ "SPN" SG_ 2633832702 RearCollisionSensor3Type 4932;
BA_ "SigType" SG_ 2633832702 RearCollisionSensor3Type 4;
BA_ "SPN" SG_ 2633832702 RearCollisionSensor2Type 4931;
BA_ "SigType" SG_ 2633832702 RearCollisionSensor2Type 4;
BA_ "SPN" SG_ 2633832702 RearCollisionSensor1Type 4930;
BA_ "SigType" SG_ 2633832702 RearCollisionSensor1Type 4;
BA_ "SPN" SG_ 2633832702 SdeCollisionSensorRearRightType 4929;
BA_ "SigType" SG_ 2633832702 SdeCollisionSensorRearRightType 4;
BA_ "SPN" SG_ 2633832702 SdCllsionSensorMidRearRightType 4928;
BA_ "SigType" SG_ 2633832702 SdCllsionSensorMidRearRightType 4;
BA_ "SPN" SG_ 2633832702 SdCllsonSensorMidFrontRightType 4927;
BA_ "SigType" SG_ 2633832702 SdCllsonSensorMidFrontRightType 4;
BA_ "SPN" SG_ 2633832702 SdCollisionSensorFrontRightType 4926;
BA_ "SigType" SG_ 2633832702 SdCollisionSensorFrontRightType 4;
BA_ "SPN" SG_ 2633832702 SideCollisionSensorRearLeftType 4925;
BA_ "SigType" SG_ 2633832702 SideCollisionSensorRearLeftType 4;
BA_ "SPN" SG_ 2633832702 SdCllisionSensorMidRearLeftType 4924;
BA_ "SigType" SG_ 2633832702 SdCllisionSensorMidRearLeftType 4;
BA_ "SPN" SG_ 2633832702 SdCllsionSensorMidFrontLeftType 4923;
BA_ "SigType" SG_ 2633832702 SdCllsionSensorMidFrontLeftType 4;
BA_ "SPN" SG_ 2633832702 SdeCollisionSensorFrontLeftType 4922;
BA_ "SigType" SG_ 2633832702 SdeCollisionSensorFrontLeftType 4;
BA_ "SPN" SG_ 2633832702 FrontalCollisionSensor4Type 4921;
BA_ "SigType" SG_ 2633832702 FrontalCollisionSensor4Type 4;
BA_ "SPN" SG_ 2633832702 FrontalCollisionSensor3Type 4920;
BA_ "SigType" SG_ 2633832702 FrontalCollisionSensor3Type 4;
BA_ "SPN" SG_ 2633832702 FrontalCollisionSensor2Type 4919;
BA_ "SigType" SG_ 2633832702 FrontalCollisionSensor2Type 4;
BA_ "SPN" SG_ 2633832702 FrontalCollisionSensor1Type 4918;
BA_ "SigType" SG_ 2633832702 FrontalCollisionSensor1Type 4;
BA_ "SPN" SG_ 2163223550 CrashChecksum 4975;
BA_ "SigType" SG_ 2163223550 CrashChecksum 4;
BA_ "SPN" SG_ 2163223550 CrashCounter 4974;
BA_ "SigType" SG_ 2163223550 CrashCounter 4;
BA_ "SPN" SG_ 2163223550 CrashType 4973;
BA_ "SigType" SG_ 2163223550 CrashType 1;
BA_ "SPN" SG_ 2566714878 EngChrgArClr2PrcoolerEfficiency 5288;
BA_ "SigType" SG_ 2566714878 EngChrgArClr2PrcoolerEfficiency 1;
BA_ "SPN" SG_ 2566714878 EngChrgArClr2PrcoolerOutletTemp 5287;
BA_ "SigType" SG_ 2566714878 EngChrgArClr2PrcoolerOutletTemp 1;
BA_ "SPN" SG_ 2566714878 EngChrgArClr2PrcoolerIntakeTemp 5286;
BA_ "SigType" SG_ 2566714878 EngChrgArClr2PrcoolerIntakeTemp 1;
BA_ "SPN" SG_ 2566714622 EngChargeAirCooler2Efficiency 5292;
BA_ "SigType" SG_ 2566714622 EngChargeAirCooler2Efficiency 1;
BA_ "SPN" SG_ 2566714622 EngChrgAirCooler2AmbientAirTemp 5291;
BA_ "SigType" SG_ 2566714622 EngChrgAirCooler2AmbientAirTemp 1;
BA_ "SPN" SG_ 2566714622 EngChargeAirCooler2OutletTemp 5290;
BA_ "SigType" SG_ 2566714622 EngChargeAirCooler2OutletTemp 1;
BA_ "SPN" SG_ 2566714622 EngChargeAirCooler2IntakeTemp 5289;
BA_ "SigType" SG_ 2566714622 EngChargeAirCooler2IntakeTemp 1;
BA_ "SPN" SG_ 2566715390 EngChrgArClr1PrcoolerEfficiency 5282;
BA_ "SigType" SG_ 2566715390 EngChrgArClr1PrcoolerEfficiency 1;
BA_ "SPN" SG_ 2566715390 EngChrgArClr1PrcoolerOutletTemp 5281;
BA_ "SigType" SG_ 2566715390 EngChrgArClr1PrcoolerOutletTemp 1;
BA_ "SPN" SG_ 2566715390 EngChrgArClr1PrcoolerIntakeTemp 5280;
BA_ "SigType" SG_ 2566715390 EngChrgArClr1PrcoolerIntakeTemp 1;
BA_ "SPN" SG_ 2566715134 EngChargeAirCooler1Efficiency 5285;
BA_ "SigType" SG_ 2566715134 EngChargeAirCooler1Efficiency 1;
BA_ "SPN" SG_ 2566715134 EngChrgAirCooler1AmbientAirTemp 5284;
BA_ "SigType" SG_ 2566715134 EngChrgAirCooler1AmbientAirTemp 1;
BA_ "SPN" SG_ 2566715134 EngChargeAirCooler1IntakeTemp 5283;
BA_ "SigType" SG_ 2566715134 EngChargeAirCooler1IntakeTemp 1;
BA_ "SPN" SG_ 2365400830 Joystick9Button9PressedStatus 4697;
BA_ "SigType" SG_ 2365400830 Joystick9Button9PressedStatus 4;
BA_ "SPN" SG_ 2365400830 Joystick9Button10PressedStatus 4696;
BA_ "SigType" SG_ 2365400830 Joystick9Button10PressedStatus 4;
BA_ "SPN" SG_ 2365400830 Joystick9Button11PressedStatus 4695;
BA_ "SigType" SG_ 2365400830 Joystick9Button11PressedStatus 4;
BA_ "SPN" SG_ 2365400830 Joystick9Button12PressedStatus 4694;
BA_ "SigType" SG_ 2365400830 Joystick9Button12PressedStatus 4;
BA_ "SPN" SG_ 2365400830 Joystick9Button5PressedStatus 4693;
BA_ "SigType" SG_ 2365400830 Joystick9Button5PressedStatus 4;
BA_ "SPN" SG_ 2365400830 Joystick9Button6PressedStatus 4692;
BA_ "SigType" SG_ 2365400830 Joystick9Button6PressedStatus 4;
BA_ "SPN" SG_ 2365400830 Joystick9Button7PressedStatus 4691;
BA_ "SigType" SG_ 2365400830 Joystick9Button7PressedStatus 4;
BA_ "SPN" SG_ 2365400830 Joystick9Button8PressedStatus 4690;
BA_ "SigType" SG_ 2365400830 Joystick9Button8PressedStatus 4;
BA_ "SPN" SG_ 2365400830 Joystick9Button1PressedStatus 4689;
BA_ "SigType" SG_ 2365400830 Joystick9Button1PressedStatus 4;
BA_ "SPN" SG_ 2365400830 Joystick9Button2PressedStatus 4688;
BA_ "SigType" SG_ 2365400830 Joystick9Button2PressedStatus 4;
BA_ "SPN" SG_ 2365400830 Joystick9Button3PressedStatus 4687;
BA_ "SigType" SG_ 2365400830 Joystick9Button3PressedStatus 4;
BA_ "SPN" SG_ 2365400830 Joystick9Button4PressedStatus 4686;
BA_ "SigType" SG_ 2365400830 Joystick9Button4PressedStatus 4;
BA_ "SPN" SG_ 2365400830 Joystick9XAxisDetentPosStatus 4685;
BA_ "SigType" SG_ 2365400830 Joystick9XAxisDetentPosStatus 4;
BA_ "SPN" SG_ 2365400830 Joystick9YAxisDetentPosStatus 4684;
BA_ "SigType" SG_ 2365400830 Joystick9YAxisDetentPosStatus 4;
BA_ "SPN" SG_ 2365400830 Joystick9YAxisPos 4683;
BA_ "SigType" SG_ 2365400830 Joystick9YAxisPos 1;
BA_ "SPN" SG_ 2365400830 Jystck9YAxsLvrFrwrdPstvPsStatus 4682;
BA_ "SigType" SG_ 2365400830 Jystck9YAxsLvrFrwrdPstvPsStatus 4;
BA_ "SPN" SG_ 2365400830 Jystck9YAxsLvrBckNgtvePosStatus 4681;
BA_ "SigType" SG_ 2365400830 Jystck9YAxsLvrBckNgtvePosStatus 4;
BA_ "SPN" SG_ 2365400830 Joystick9YAxisNeutralPosStatus 4680;
BA_ "SigType" SG_ 2365400830 Joystick9YAxisNeutralPosStatus 4;
BA_ "SPN" SG_ 2365400830 Joystick9XAxisPos 4679;
BA_ "SigType" SG_ 2365400830 Joystick9XAxisPos 1;
BA_ "SPN" SG_ 2365400830 Jystck9XAxsLvrRghtPstvPosStatus 4678;
BA_ "SigType" SG_ 2365400830 Jystck9XAxsLvrRghtPstvPosStatus 4;
BA_ "SPN" SG_ 2365400830 Jystck9XAxsLvrLftNgtvePosStatus 4677;
BA_ "SigType" SG_ 2365400830 Jystck9XAxsLvrLftNgtvePosStatus 4;
BA_ "SPN" SG_ 2365400830 Joystick9XAxisNeutralPosStatus 4676;
BA_ "SigType" SG_ 2365400830 Joystick9XAxisNeutralPosStatus 4;
BA_ "SPN" SG_ 2365401342 Joystick8Button9PressedStatus 4660;
BA_ "SigType" SG_ 2365401342 Joystick8Button9PressedStatus 4;
BA_ "SPN" SG_ 2365401342 Joystick8Button10PressedStatus 4659;
BA_ "SigType" SG_ 2365401342 Joystick8Button10PressedStatus 4;
BA_ "SPN" SG_ 2365401342 Joystick8Button11PressedStatus 4658;
BA_ "SigType" SG_ 2365401342 Joystick8Button11PressedStatus 4;
BA_ "SPN" SG_ 2365401342 Joystick8Button12PressedStatus 4657;
BA_ "SigType" SG_ 2365401342 Joystick8Button12PressedStatus 4;
BA_ "SPN" SG_ 2365401342 Joystick8Button5PressedStatus 4656;
BA_ "SigType" SG_ 2365401342 Joystick8Button5PressedStatus 4;
BA_ "SPN" SG_ 2365401342 Joystick8Button6PressedStatus 4655;
BA_ "SigType" SG_ 2365401342 Joystick8Button6PressedStatus 4;
BA_ "SPN" SG_ 2365401342 Joystick8Button7PressedStatus 4654;
BA_ "SigType" SG_ 2365401342 Joystick8Button7PressedStatus 4;
BA_ "SPN" SG_ 2365401342 Joystick8Button8PressedStatus 4653;
BA_ "SigType" SG_ 2365401342 Joystick8Button8PressedStatus 4;
BA_ "SPN" SG_ 2365401342 Joystick8Button1PressedStatus 4652;
BA_ "SigType" SG_ 2365401342 Joystick8Button1PressedStatus 4;
BA_ "SPN" SG_ 2365401342 Joystick8Button2PressedStatus 4651;
BA_ "SigType" SG_ 2365401342 Joystick8Button2PressedStatus 4;
BA_ "SPN" SG_ 2365401342 Joystick8Button3PressedStatus 4650;
BA_ "SigType" SG_ 2365401342 Joystick8Button3PressedStatus 4;
BA_ "SPN" SG_ 2365401342 Joystick8Button4PressedStatus 4649;
BA_ "SigType" SG_ 2365401342 Joystick8Button4PressedStatus 4;
BA_ "SPN" SG_ 2365401342 Joystick8XAxisDetentPosStatus 4648;
BA_ "SigType" SG_ 2365401342 Joystick8XAxisDetentPosStatus 4;
BA_ "SPN" SG_ 2365401342 Joystick8YAxisDetentPosStatus 4647;
BA_ "SigType" SG_ 2365401342 Joystick8YAxisDetentPosStatus 4;
BA_ "SPN" SG_ 2365401342 Joystick8YAxisPos 4646;
BA_ "SigType" SG_ 2365401342 Joystick8YAxisPos 1;
BA_ "SPN" SG_ 2365401342 Jystck8YAxsLvrFrwrdPstvPsStatus 4645;
BA_ "SigType" SG_ 2365401342 Jystck8YAxsLvrFrwrdPstvPsStatus 4;
BA_ "SPN" SG_ 2365401342 Jystck8YAxsLvrBckNgtvePosStatus 4644;
BA_ "SigType" SG_ 2365401342 Jystck8YAxsLvrBckNgtvePosStatus 4;
BA_ "SPN" SG_ 2365401342 Joystick8YAxisNeutralPosStatus 4643;
BA_ "SigType" SG_ 2365401342 Joystick8YAxisNeutralPosStatus 4;
BA_ "SPN" SG_ 2365401342 Joystick8XAxisPos 4642;
BA_ "SigType" SG_ 2365401342 Joystick8XAxisPos 1;
BA_ "SPN" SG_ 2365401342 Jystck8XAxsLvrRghtPstvPosStatus 4641;
BA_ "SigType" SG_ 2365401342 Jystck8XAxsLvrRghtPstvPosStatus 4;
BA_ "SPN" SG_ 2365401342 Jystck8XAxsLvrLftNgtvePosStatus 4640;
BA_ "SigType" SG_ 2365401342 Jystck8XAxsLvrLftNgtvePosStatus 4;
BA_ "SPN" SG_ 2365401342 Joystick8XAxisNeutralPosStatus 4639;
BA_ "SigType" SG_ 2365401342 Joystick8XAxisNeutralPosStatus 4;
BA_ "SPN" SG_ 2365401854 Joystick7Button9PressedStatus 4623;
BA_ "SigType" SG_ 2365401854 Joystick7Button9PressedStatus 4;
BA_ "SPN" SG_ 2365401854 Joystick7Button10PressedStatus 4622;
BA_ "SigType" SG_ 2365401854 Joystick7Button10PressedStatus 4;
BA_ "SPN" SG_ 2365401854 Joystick7Button11PressedStatus 4621;
BA_ "SigType" SG_ 2365401854 Joystick7Button11PressedStatus 4;
BA_ "SPN" SG_ 2365401854 Joystick7Button12PressedStatus 4620;
BA_ "SigType" SG_ 2365401854 Joystick7Button12PressedStatus 4;
BA_ "SPN" SG_ 2365401854 Joystick7Button5PressedStatus 4619;
BA_ "SigType" SG_ 2365401854 Joystick7Button5PressedStatus 4;
BA_ "SPN" SG_ 2365401854 Joystick7Button6PressedStatus 4618;
BA_ "SigType" SG_ 2365401854 Joystick7Button6PressedStatus 4;
BA_ "SPN" SG_ 2365401854 Joystick7Button7PressedStatus 4617;
BA_ "SigType" SG_ 2365401854 Joystick7Button7PressedStatus 4;
BA_ "SPN" SG_ 2365401854 Joystick7Button8PressedStatus 4616;
BA_ "SigType" SG_ 2365401854 Joystick7Button8PressedStatus 4;
BA_ "SPN" SG_ 2365401854 Joystick7Button1PressedStatus 4615;
BA_ "SigType" SG_ 2365401854 Joystick7Button1PressedStatus 4;
BA_ "SPN" SG_ 2365401854 Joystick7Button2PressedStatus 4614;
BA_ "SigType" SG_ 2365401854 Joystick7Button2PressedStatus 4;
BA_ "SPN" SG_ 2365401854 Joystick7Button3PressedStatus 4613;
BA_ "SigType" SG_ 2365401854 Joystick7Button3PressedStatus 4;
BA_ "SPN" SG_ 2365401854 Joystick7Button4PressedStatus 4612;
BA_ "SigType" SG_ 2365401854 Joystick7Button4PressedStatus 4;
BA_ "SPN" SG_ 2365401854 Joystick7XAxisDetentPosStatus 4611;
BA_ "SigType" SG_ 2365401854 Joystick7XAxisDetentPosStatus 4;
BA_ "SPN" SG_ 2365401854 Joystick7YAxisDetentPosStatus 4610;
BA_ "SigType" SG_ 2365401854 Joystick7YAxisDetentPosStatus 4;
BA_ "SPN" SG_ 2365401854 Joystick7YAxisPos 4609;
BA_ "SigType" SG_ 2365401854 Joystick7YAxisPos 1;
BA_ "SPN" SG_ 2365401854 Jystck7YAxsLvrFrwrdPstvPsStatus 4608;
BA_ "SigType" SG_ 2365401854 Jystck7YAxsLvrFrwrdPstvPsStatus 4;
BA_ "SPN" SG_ 2365401854 Jystck7YAxsLvrBckNgtvePosStatus 4607;
BA_ "SigType" SG_ 2365401854 Jystck7YAxsLvrBckNgtvePosStatus 4;
BA_ "SPN" SG_ 2365401854 Joystick7YAxisNeutralPosStatus 4606;
BA_ "SigType" SG_ 2365401854 Joystick7YAxisNeutralPosStatus 4;
BA_ "SPN" SG_ 2365401854 Joystick7XAxisPos 4605;
BA_ "SigType" SG_ 2365401854 Joystick7XAxisPos 1;
BA_ "SPN" SG_ 2365401854 Jystck7XAxsLvrRghtPstvPosStatus 4604;
BA_ "SigType" SG_ 2365401854 Jystck7XAxsLvrRghtPstvPosStatus 4;
BA_ "SPN" SG_ 2365401854 Jystck7XAxsLvrLftNgtvePosStatus 4603;
BA_ "SigType" SG_ 2365401854 Jystck7XAxsLvrLftNgtvePosStatus 4;
BA_ "SPN" SG_ 2365401854 Joystick7XAxisNeutralPosStatus 4602;
BA_ "SigType" SG_ 2365401854 Joystick7XAxisNeutralPosStatus 4;
BA_ "SPN" SG_ 2365402366 Joystick6Button9PressedStatus 4586;
BA_ "SigType" SG_ 2365402366 Joystick6Button9PressedStatus 4;
BA_ "SPN" SG_ 2365402366 Joystick6Button10PressedStatus 4585;
BA_ "SigType" SG_ 2365402366 Joystick6Button10PressedStatus 4;
BA_ "SPN" SG_ 2365402366 Joystick6Button11PressedStatus 4584;
BA_ "SigType" SG_ 2365402366 Joystick6Button11PressedStatus 4;
BA_ "SPN" SG_ 2365402366 Joystick6Button12PressedStatus 4583;
BA_ "SigType" SG_ 2365402366 Joystick6Button12PressedStatus 4;
BA_ "SPN" SG_ 2365402366 Joystick6Button5PressedStatus 4582;
BA_ "SigType" SG_ 2365402366 Joystick6Button5PressedStatus 4;
BA_ "SPN" SG_ 2365402366 Joystick6Button6PressedStatus 4581;
BA_ "SigType" SG_ 2365402366 Joystick6Button6PressedStatus 4;
BA_ "SPN" SG_ 2365402366 Joystick6Button7PressedStatus 4580;
BA_ "SigType" SG_ 2365402366 Joystick6Button7PressedStatus 4;
BA_ "SPN" SG_ 2365402366 Joystick6Button8PressedStatus 4579;
BA_ "SigType" SG_ 2365402366 Joystick6Button8PressedStatus 4;
BA_ "SPN" SG_ 2365402366 Joystick6Button1PressedStatus 4578;
BA_ "SigType" SG_ 2365402366 Joystick6Button1PressedStatus 4;
BA_ "SPN" SG_ 2365402366 Joystick6Button2PressedStatus 4577;
BA_ "SigType" SG_ 2365402366 Joystick6Button2PressedStatus 4;
BA_ "SPN" SG_ 2365402366 Joystick6Button3PressedStatus 4576;
BA_ "SigType" SG_ 2365402366 Joystick6Button3PressedStatus 4;
BA_ "SPN" SG_ 2365402366 Joystick6Button4PressedStatus 4575;
BA_ "SigType" SG_ 2365402366 Joystick6Button4PressedStatus 4;
BA_ "SPN" SG_ 2365402366 Joystick6XAxisDetentPosStatus 4574;
BA_ "SigType" SG_ 2365402366 Joystick6XAxisDetentPosStatus 4;
BA_ "SPN" SG_ 2365402366 Joystick6YAxisDetentPosStatus 4573;
BA_ "SigType" SG_ 2365402366 Joystick6YAxisDetentPosStatus 4;
BA_ "SPN" SG_ 2365402366 Joystick6YAxisPos 4572;
BA_ "SigType" SG_ 2365402366 Joystick6YAxisPos 1;
BA_ "SPN" SG_ 2365402366 Jystck6YAxsLvrFrwrdPstvPsStatus 4571;
BA_ "SigType" SG_ 2365402366 Jystck6YAxsLvrFrwrdPstvPsStatus 4;
BA_ "SPN" SG_ 2365402366 Jystck6YAxsLvrBckNgtvePosStatus 4570;
BA_ "SigType" SG_ 2365402366 Jystck6YAxsLvrBckNgtvePosStatus 4;
BA_ "SPN" SG_ 2365402366 Joystick6YAxisNeutralPosStatus 4569;
BA_ "SigType" SG_ 2365402366 Joystick6YAxisNeutralPosStatus 4;
BA_ "SPN" SG_ 2365402366 Joystick6XAxisPos 4568;
BA_ "SigType" SG_ 2365402366 Joystick6XAxisPos 1;
BA_ "SPN" SG_ 2365402366 Jystck6XAxsLvrRghtPstvPosStatus 4567;
BA_ "SigType" SG_ 2365402366 Jystck6XAxsLvrRghtPstvPosStatus 4;
BA_ "SPN" SG_ 2365402366 Jystck6XAxsLvrLftNgtvePosStatus 4566;
BA_ "SigType" SG_ 2365402366 Jystck6XAxsLvrLftNgtvePosStatus 4;
BA_ "SPN" SG_ 2365402366 Joystick6XAxisNeutralPosStatus 4565;
BA_ "SigType" SG_ 2365402366 Joystick6XAxisNeutralPosStatus 4;
BA_ "SPN" SG_ 2365402878 Joystick5Button9PressedStatus 4549;
BA_ "SigType" SG_ 2365402878 Joystick5Button9PressedStatus 4;
BA_ "SPN" SG_ 2365402878 Joystick5Button10PressedStatus 4548;
BA_ "SigType" SG_ 2365402878 Joystick5Button10PressedStatus 4;
BA_ "SPN" SG_ 2365402878 Joystick5Button11PressedStatus 4547;
BA_ "SigType" SG_ 2365402878 Joystick5Button11PressedStatus 4;
BA_ "SPN" SG_ 2365402878 Joystick5Button12PressedStatus 4546;
BA_ "SigType" SG_ 2365402878 Joystick5Button12PressedStatus 4;
BA_ "SPN" SG_ 2365402878 Joystick5Button5PressedStatus 4545;
BA_ "SigType" SG_ 2365402878 Joystick5Button5PressedStatus 4;
BA_ "SPN" SG_ 2365402878 Joystick5Button6PressedStatus 4544;
BA_ "SigType" SG_ 2365402878 Joystick5Button6PressedStatus 4;
BA_ "SPN" SG_ 2365402878 Joystick5Button7PressedStatus 4543;
BA_ "SigType" SG_ 2365402878 Joystick5Button7PressedStatus 4;
BA_ "SPN" SG_ 2365402878 Joystick5Button8PressedStatus 4542;
BA_ "SigType" SG_ 2365402878 Joystick5Button8PressedStatus 4;
BA_ "SPN" SG_ 2365402878 Joystick5Button1PressedStatus 4541;
BA_ "SigType" SG_ 2365402878 Joystick5Button1PressedStatus 4;
BA_ "SPN" SG_ 2365402878 Joystick5Button2PressedStatus 4540;
BA_ "SigType" SG_ 2365402878 Joystick5Button2PressedStatus 4;
BA_ "SPN" SG_ 2365402878 Joystick5Button3PressedStatus 4539;
BA_ "SigType" SG_ 2365402878 Joystick5Button3PressedStatus 4;
BA_ "SPN" SG_ 2365402878 Joystick5Button4PressedStatus 4538;
BA_ "SigType" SG_ 2365402878 Joystick5Button4PressedStatus 4;
BA_ "SPN" SG_ 2365402878 Joystick5XAxisDetentPosStatus 4537;
BA_ "SigType" SG_ 2365402878 Joystick5XAxisDetentPosStatus 4;
BA_ "SPN" SG_ 2365402878 Joystick5YAxisDetentPosStatus 4536;
BA_ "SigType" SG_ 2365402878 Joystick5YAxisDetentPosStatus 4;
BA_ "SPN" SG_ 2365402878 Joystick5YAxisPos 4535;
BA_ "SigType" SG_ 2365402878 Joystick5YAxisPos 1;
BA_ "SPN" SG_ 2365402878 Jystck5YAxsLvrFrwrdPstvPsStatus 4534;
BA_ "SigType" SG_ 2365402878 Jystck5YAxsLvrFrwrdPstvPsStatus 4;
BA_ "SPN" SG_ 2365402878 Jystck5YAxsLvrBckNgtvePosStatus 4533;
BA_ "SigType" SG_ 2365402878 Jystck5YAxsLvrBckNgtvePosStatus 4;
BA_ "SPN" SG_ 2365402878 Joystick5YAxisNeutralPosStatus 4532;
BA_ "SigType" SG_ 2365402878 Joystick5YAxisNeutralPosStatus 4;
BA_ "SPN" SG_ 2365402878 Joystick5XAxisPos 4531;
BA_ "SigType" SG_ 2365402878 Joystick5XAxisPos 1;
BA_ "SPN" SG_ 2365402878 Jystck5XAxsLvrRghtPstvPosStatus 4530;
BA_ "SigType" SG_ 2365402878 Jystck5XAxsLvrRghtPstvPosStatus 4;
BA_ "SPN" SG_ 2365402878 Jystck5XAxsLvrLftNgtvePosStatus 4529;
BA_ "SigType" SG_ 2365402878 Jystck5XAxsLvrLftNgtvePosStatus 4;
BA_ "SPN" SG_ 2365402878 Joystick5XAxisNeutralPosStatus 4528;
BA_ "SigType" SG_ 2365402878 Joystick5XAxisNeutralPosStatus 4;
BA_ "SPN" SG_ 2365403390 Joystick4Button9PressedStatus 4512;
BA_ "SigType" SG_ 2365403390 Joystick4Button9PressedStatus 4;
BA_ "SPN" SG_ 2365403390 Joystick4Button10PressedStatus 4511;
BA_ "SigType" SG_ 2365403390 Joystick4Button10PressedStatus 4;
BA_ "SPN" SG_ 2365403390 Joystick4Button11PressedStatus 4510;
BA_ "SigType" SG_ 2365403390 Joystick4Button11PressedStatus 4;
BA_ "SPN" SG_ 2365403390 Joystick4Button12PressedStatus 4509;
BA_ "SigType" SG_ 2365403390 Joystick4Button12PressedStatus 4;
BA_ "SPN" SG_ 2365403390 Joystick4Button5PressedStatus 4508;
BA_ "SigType" SG_ 2365403390 Joystick4Button5PressedStatus 4;
BA_ "SPN" SG_ 2365403390 Joystick4Button6PressedStatus 4507;
BA_ "SigType" SG_ 2365403390 Joystick4Button6PressedStatus 4;
BA_ "SPN" SG_ 2365403390 Joystick4Button7PressedStatus 4506;
BA_ "SigType" SG_ 2365403390 Joystick4Button7PressedStatus 4;
BA_ "SPN" SG_ 2365403390 Joystick4Button8PressedStatus 4505;
BA_ "SigType" SG_ 2365403390 Joystick4Button8PressedStatus 4;
BA_ "SPN" SG_ 2365403390 Joystick4Button1PressedStatus 4504;
BA_ "SigType" SG_ 2365403390 Joystick4Button1PressedStatus 4;
BA_ "SPN" SG_ 2365403390 Joystick4Button2PressedStatus 4503;
BA_ "SigType" SG_ 2365403390 Joystick4Button2PressedStatus 4;
BA_ "SPN" SG_ 2365403390 Joystick4Button3PressedStatus 4502;
BA_ "SigType" SG_ 2365403390 Joystick4Button3PressedStatus 4;
BA_ "SPN" SG_ 2365403390 Joystick4Button4PressedStatus 4501;
BA_ "SigType" SG_ 2365403390 Joystick4Button4PressedStatus 4;
BA_ "SPN" SG_ 2365403390 Joystick4XAxisDetentPosStatus 4500;
BA_ "SigType" SG_ 2365403390 Joystick4XAxisDetentPosStatus 4;
BA_ "SPN" SG_ 2365403390 Joystick4YAxisDetentPosStatus 4499;
BA_ "SigType" SG_ 2365403390 Joystick4YAxisDetentPosStatus 4;
BA_ "SPN" SG_ 2365403390 Joystick4YAxisPos 4498;
BA_ "SigType" SG_ 2365403390 Joystick4YAxisPos 1;
BA_ "SPN" SG_ 2365403390 Jystck4YAxsLvrFrwrdPstvPsStatus 4497;
BA_ "SigType" SG_ 2365403390 Jystck4YAxsLvrFrwrdPstvPsStatus 4;
BA_ "SPN" SG_ 2365403390 Jystck4YAxsLvrBckNgtvePosStatus 4496;
BA_ "SigType" SG_ 2365403390 Jystck4YAxsLvrBckNgtvePosStatus 4;
BA_ "SPN" SG_ 2365403390 Joystick4YAxisNeutralPosStatus 4495;
BA_ "SigType" SG_ 2365403390 Joystick4YAxisNeutralPosStatus 4;
BA_ "SPN" SG_ 2365403390 Joystick4XAxisPos 4494;
BA_ "SigType" SG_ 2365403390 Joystick4XAxisPos 1;
BA_ "SPN" SG_ 2365403390 Jystck4XAxsLvrRghtPstvPosStatus 4493;
BA_ "SigType" SG_ 2365403390 Jystck4XAxsLvrRghtPstvPosStatus 4;
BA_ "SPN" SG_ 2365403390 Jystck4XAxsLvrLftNgtvePosStatus 4492;
BA_ "SigType" SG_ 2365403390 Jystck4XAxsLvrLftNgtvePosStatus 4;
BA_ "SPN" SG_ 2365403390 Joystick4XAxisNeutralPosStatus 4491;
BA_ "SigType" SG_ 2365403390 Joystick4XAxisNeutralPosStatus 4;
BA_ "SPN" SG_ 2365400318 Joystick10Button9PressedStatus 4734;
BA_ "SigType" SG_ 2365400318 Joystick10Button9PressedStatus 4;
BA_ "SPN" SG_ 2365400318 Joystick10Button10PressedStatus 4733;
BA_ "SigType" SG_ 2365400318 Joystick10Button10PressedStatus 4;
BA_ "SPN" SG_ 2365400318 Joystick10Button11PressedStatus 4732;
BA_ "SigType" SG_ 2365400318 Joystick10Button11PressedStatus 4;
BA_ "SPN" SG_ 2365400318 Joystick10Button12PressedStatus 4731;
BA_ "SigType" SG_ 2365400318 Joystick10Button12PressedStatus 4;
BA_ "SPN" SG_ 2365400318 Joystick10Button5PressedStatus 4730;
BA_ "SigType" SG_ 2365400318 Joystick10Button5PressedStatus 4;
BA_ "SPN" SG_ 2365400318 Joystick10Button6PressedStatus 4729;
BA_ "SigType" SG_ 2365400318 Joystick10Button6PressedStatus 4;
BA_ "SPN" SG_ 2365400318 Joystick10Button7PressedStatus 4728;
BA_ "SigType" SG_ 2365400318 Joystick10Button7PressedStatus 4;
BA_ "SPN" SG_ 2365400318 Joystick10Button8PressedStatus 4727;
BA_ "SigType" SG_ 2365400318 Joystick10Button8PressedStatus 4;
BA_ "SPN" SG_ 2365400318 Joystick10Button1PressedStatus 4726;
BA_ "SigType" SG_ 2365400318 Joystick10Button1PressedStatus 4;
BA_ "SPN" SG_ 2365400318 Joystick10Button2PressedStatus 4725;
BA_ "SigType" SG_ 2365400318 Joystick10Button2PressedStatus 4;
BA_ "SPN" SG_ 2365400318 Joystick10Button3PressedStatus 4724;
BA_ "SigType" SG_ 2365400318 Joystick10Button3PressedStatus 4;
BA_ "SPN" SG_ 2365400318 Joystick10Button4PressedStatus 4723;
BA_ "SigType" SG_ 2365400318 Joystick10Button4PressedStatus 4;
BA_ "SPN" SG_ 2365400318 Joystick10XAxisDetentPosStatus 4722;
BA_ "SigType" SG_ 2365400318 Joystick10XAxisDetentPosStatus 4;
BA_ "SPN" SG_ 2365400318 Joystick10YAxisDetentPosStatus 4721;
BA_ "SigType" SG_ 2365400318 Joystick10YAxisDetentPosStatus 4;
BA_ "SPN" SG_ 2365400318 Joystick10YAxisPos 4720;
BA_ "SigType" SG_ 2365400318 Joystick10YAxisPos 1;
BA_ "SPN" SG_ 2365400318 Jystck10YAxsLvrFrwrdPstvPsSttus 4719;
BA_ "SigType" SG_ 2365400318 Jystck10YAxsLvrFrwrdPstvPsSttus 4;
BA_ "SPN" SG_ 2365400318 Jystck10YAxsLvrBckNgtvPosStatus 4718;
BA_ "SigType" SG_ 2365400318 Jystck10YAxsLvrBckNgtvPosStatus 4;
BA_ "SPN" SG_ 2365400318 Joystick10YAxisNeutralPosStatus 4717;
BA_ "SigType" SG_ 2365400318 Joystick10YAxisNeutralPosStatus 4;
BA_ "SPN" SG_ 2365400318 Joystick10XAxisPos 4716;
BA_ "SigType" SG_ 2365400318 Joystick10XAxisPos 1;
BA_ "SPN" SG_ 2365400318 Jystck10XAxsLvrRghtPstvPsStatus 4715;
BA_ "SigType" SG_ 2365400318 Jystck10XAxsLvrRghtPstvPsStatus 4;
BA_ "SPN" SG_ 2365400318 Jystck10XAxsLvrLftNgtvPosStatus 4714;
BA_ "SigType" SG_ 2365400318 Jystck10XAxsLvrLftNgtvPosStatus 4;
BA_ "SPN" SG_ 2365400318 Joystick10XAxisNeutralPosStatus 4713;
BA_ "SigType" SG_ 2365400318 Joystick10XAxisNeutralPosStatus 4;
BA_ "SPN" SG_ 2499614718 PssngrArbgDctvationSwitchStatus 4962;
BA_ "SigType" SG_ 2499614718 PssngrArbgDctvationSwitchStatus 4;
BA_ "SPN" SG_ 2499614718 Beltlock10Status 4961;
BA_ "SigType" SG_ 2499614718 Beltlock10Status 4;
BA_ "SPN" SG_ 2499614718 Beltlock9Status 4960;
BA_ "SigType" SG_ 2499614718 Beltlock9Status 4;
BA_ "SPN" SG_ 2499614718 Beltlock8Status 4959;
BA_ "SigType" SG_ 2499614718 Beltlock8Status 4;
BA_ "SPN" SG_ 2499614718 Beltlock7Status 4958;
BA_ "SigType" SG_ 2499614718 Beltlock7Status 4;
BA_ "SPN" SG_ 2499614718 Beltlock6Status 4957;
BA_ "SigType" SG_ 2499614718 Beltlock6Status 4;
BA_ "SPN" SG_ 2499614718 Beltlock5Status 4956;
BA_ "SigType" SG_ 2499614718 Beltlock5Status 4;
BA_ "SPN" SG_ 2499614718 Beltlock4Status 4955;
BA_ "SigType" SG_ 2499614718 Beltlock4Status 4;
BA_ "SPN" SG_ 2499614718 Beltlock3Status 4954;
BA_ "SigType" SG_ 2499614718 Beltlock3Status 4;
BA_ "SPN" SG_ 2499614718 PassengerBeltlockStatus 4953;
BA_ "SigType" SG_ 2499614718 PassengerBeltlockStatus 4;
BA_ "SPN" SG_ 2499614718 DriverBeltlockStatus 4952;
BA_ "SigType" SG_ 2499614718 DriverBeltlockStatus 4;
BA_ "SPN" SG_ 2566722814 BatteryCharger2OutputCurrent 4997;
BA_ "SigType" SG_ 2566722814 BatteryCharger2OutputCurrent 1;
BA_ "SPN" SG_ 2566722814 BatteryCharger2OutputVoltage 4996;
BA_ "SigType" SG_ 2566722814 BatteryCharger2OutputVoltage 1;
BA_ "SPN" SG_ 2566722814 BatteryCharger2PowerLineState 4995;
BA_ "SigType" SG_ 2566722814 BatteryCharger2PowerLineState 4;
BA_ "SPN" SG_ 2566722814 BatteryCharger2State 4994;
BA_ "SigType" SG_ 2566722814 BatteryCharger2State 4;
BA_ "SPN" SG_ 2566723070 BatteryCharger1OutputCurrent 4993;
BA_ "SigType" SG_ 2566723070 BatteryCharger1OutputCurrent 1;
BA_ "SPN" SG_ 2566723070 BatteryCharger1OutputVoltage 4992;
BA_ "SigType" SG_ 2566723070 BatteryCharger1OutputVoltage 1;
BA_ "SPN" SG_ 2566723070 BatteryCharger1PowerLineState 4991;
BA_ "SigType" SG_ 2566723070 BatteryCharger1PowerLineState 4;
BA_ "SPN" SG_ 2566723070 BatteryCharger1State 4990;
BA_ "SigType" SG_ 2566723070 BatteryCharger1State 4;
BA_ "SPN" SG_ 2566725118 Aftrtrtmnt2ThrWyCtlystDffGsTemp 4780;
BA_ "SigType" SG_ 2566725118 Aftrtrtmnt2ThrWyCtlystDffGsTemp 1;
BA_ "SPN" SG_ 2566725118 Aftrtrtmnt1ThrWyCtlystDffGsTemp 4779;
BA_ "SigType" SG_ 2566725118 Aftrtrtmnt1ThrWyCtlystDffGsTemp 1;
BA_ "SPN" SG_ 2566725374 Aftrtrtmnt2GsOxdtnCtlystDffGsTmp 4778;
BA_ "SigType" SG_ 2566725374 Aftrtrtmnt2GsOxdtnCtlystDffGsTmp 1;
BA_ "SPN" SG_ 2566725374 Aftrtrtmnt1GsOxdtnCtlystDffGsTmp 4777;
BA_ "SigType" SG_ 2566725374 Aftrtrtmnt1GsOxdtnCtlystDffGsTmp 1;
BA_ "SPN" SG_ 2566712830 Aftrtrtmnt2WrmUpDslOxdtnCtlystOt 5316;
BA_ "SigType" SG_ 2566712830 Aftrtrtmnt2WrmUpDslOxdtnCtlystOt 1;
BA_ "SystemSignalLongSymbol" SG_ 2566712830 Aftrtrtmnt2WrmUpDslOxdtnCtlystOt "Aftrtrtmnt2WrmUpDslOxdtnCtlystOtltTmp";
BA_ "SPN" SG_ 2566712830 Aftrtrtmnt2WrmUpDslOxdtnCtlystIn 5315;
BA_ "SigType" SG_ 2566712830 Aftrtrtmnt2WrmUpDslOxdtnCtlystIn 1;
BA_ "SystemSignalLongSymbol" SG_ 2566712830 Aftrtrtmnt2WrmUpDslOxdtnCtlystIn "Aftrtrtmnt2WrmUpDslOxdtnCtlystIntkTmp";
BA_ "SPN" SG_ 2566735358 Aftrtrtmnt2ThrWyCtlytcCnvrtrDffP 4300;
BA_ "SigType" SG_ 2566735358 Aftrtrtmnt2ThrWyCtlytcCnvrtrDffP 1;
BA_ "SystemSignalLongSymbol" SG_ 2566735358 Aftrtrtmnt2ThrWyCtlytcCnvrtrDffP "Aftrtrtmnt2ThrWyCtlytcCnvrtrDffPrssPrlmnryFMI";
BA_ "SPN" SG_ 2566735358 Aftrtrtmnt2ThrWyCtlytcCnvrtrOtlt 4299;
BA_ "SigType" SG_ 2566735358 Aftrtrtmnt2ThrWyCtlytcCnvrtrOtlt 1;
BA_ "SystemSignalLongSymbol" SG_ 2566735358 Aftrtrtmnt2ThrWyCtlytcCnvrtrOtlt "Aftrtrtmnt2ThrWyCtlytcCnvrtrOtltGsTmpPrlmnryFMI";
BA_ "SPN" SG_ 2566735358 Aftrtrtmnt2ThrWyCtlytcCnvrtrIntk 4298;
BA_ "SigType" SG_ 2566735358 Aftrtrtmnt2ThrWyCtlytcCnvrtrIntk 1;
BA_ "SystemSignalLongSymbol" SG_ 2566735358 Aftrtrtmnt2ThrWyCtlytcCnvrtrIntk "Aftrtrtmnt2ThrWyCtlytcCnvrtrIntkGsTmpPrlmnryFMI";
BA_ "SPN" SG_ 2566735358 Aftrtrtmnt2ThrWyCtlytcCnvrt_0000 4297;
BA_ "SigType" SG_ 2566735358 Aftrtrtmnt2ThrWyCtlytcCnvrt_0000 1;
BA_ "SystemSignalLongSymbol" SG_ 2566735358 Aftrtrtmnt2ThrWyCtlytcCnvrt_0000 "Aftrtrtmnt2ThrWyCtlytcCnvrtrDffPrss";
BA_ "SPN" SG_ 2566735358 Aftrtrtmnt2ThrWyCtlytcCnvrt_0001 4296;
BA_ "SigType" SG_ 2566735358 Aftrtrtmnt2ThrWyCtlytcCnvrt_0001 1;
BA_ "SystemSignalLongSymbol" SG_ 2566735358 Aftrtrtmnt2ThrWyCtlytcCnvrt_0001 "Aftrtrtmnt2ThrWyCtlytcCnvrtrOtltGsTmp";
BA_ "SPN" SG_ 2566735358 Aftrtrtmnt2ThrWyCtlytcCnvrt_0002 4295;
BA_ "SigType" SG_ 2566735358 Aftrtrtmnt2ThrWyCtlytcCnvrt_0002 1;
BA_ "SystemSignalLongSymbol" SG_ 2566735358 Aftrtrtmnt2ThrWyCtlytcCnvrt_0002 "Aftrtrtmnt2ThrWyCtlytcCnvrtrIntkGsTmp";
BA_ "SPN" SG_ 2365393662 Aftrtrtmnt2OtltGsNOxSnsrNH3Crrct 5051;
BA_ "SigType" SG_ 2365393662 Aftrtrtmnt2OtltGsNOxSnsrNH3Crrct 1;
BA_ "SystemSignalLongSymbol" SG_ 2365393662 Aftrtrtmnt2OtltGsNOxSnsrNH3Crrct "Aftrtrtmnt2OtltGsNOxSnsrNH3Crrctn";
BA_ "SPN" SG_ 2365393662 Aftrtrtmnt2OtltGsNOxSnsrNO2Crrct 5050;
BA_ "SigType" SG_ 2365393662 Aftrtrtmnt2OtltGsNOxSnsrNO2Crrct 1;
BA_ "SystemSignalLongSymbol" SG_ 2365393662 Aftrtrtmnt2OtltGsNOxSnsrNO2Crrct "Aftrtrtmnt2OtltGsNOxSnsrNO2Crrctn";
BA_ "SPN" SG_ 2365393662 Aftrtrtmnt2OtltGsNOxSnsrCrrctnOf 5049;
BA_ "SigType" SG_ 2365393662 Aftrtrtmnt2OtltGsNOxSnsrCrrctnOf 1;
BA_ "SystemSignalLongSymbol" SG_ 2365393662 Aftrtrtmnt2OtltGsNOxSnsrCrrctnOf "Aftrtrtmnt2OtltGsNOxSnsrCrrctnOfPrssNx";
BA_ "SPN" SG_ 2365393662 Aftrtrtmnt2OtltGsNOxSnsrCrr_0000 5048;
BA_ "SigType" SG_ 2365393662 Aftrtrtmnt2OtltGsNOxSnsrCrr_0000 1;
BA_ "SystemSignalLongSymbol" SG_ 2365393662 Aftrtrtmnt2OtltGsNOxSnsrCrr_0000 "Aftrtrtmnt2OtltGsNOxSnsrCrrctnOfPrssLmbd";
BA_ "SPN" SG_ 2365393918 Aftrtrtmnt2OtltGsNOxSnsrNwPrtDvt 5047;
BA_ "SigType" SG_ 2365393918 Aftrtrtmnt2OtltGsNOxSnsrNwPrtDvt 1;
BA_ "SystemSignalLongSymbol" SG_ 2365393918 Aftrtrtmnt2OtltGsNOxSnsrNwPrtDvt "Aftrtrtmnt2OtltGsNOxSnsrNwPrtDvtnNOxOffst";
BA_ "SPN" SG_ 2365393918 Aftrtrtmnt2OtltGsNOxSnsrNwP_0000 5046;
BA_ "SigType" SG_ 2365393918 Aftrtrtmnt2OtltGsNOxSnsrNwP_0000 1;
BA_ "SystemSignalLongSymbol" SG_ 2365393918 Aftrtrtmnt2OtltGsNOxSnsrNwP_0000 "Aftrtrtmnt2OtltGsNOxSnsrNwPrtDvtnNOxGn";
BA_ "SPN" SG_ 2365393918 Aftrtrtmnt2OtltGsNOxSnsrHtrRtio 5045;
BA_ "SigType" SG_ 2365393918 Aftrtrtmnt2OtltGsNOxSnsrHtrRtio 1;
BA_ "SPN" SG_ 2365394174 Aftrtrtmnt2IntkGsNOxSnsrNH3Crrct 5044;
BA_ "SigType" SG_ 2365394174 Aftrtrtmnt2IntkGsNOxSnsrNH3Crrct 1;
BA_ "SystemSignalLongSymbol" SG_ 2365394174 Aftrtrtmnt2IntkGsNOxSnsrNH3Crrct "Aftrtrtmnt2IntkGsNOxSnsrNH3Crrctn";
BA_ "SPN" SG_ 2365394174 Aftrtrtmnt2IntkGsNOxSnsrNO2Crrct 5043;
BA_ "SigType" SG_ 2365394174 Aftrtrtmnt2IntkGsNOxSnsrNO2Crrct 1;
BA_ "SystemSignalLongSymbol" SG_ 2365394174 Aftrtrtmnt2IntkGsNOxSnsrNO2Crrct "Aftrtrtmnt2IntkGsNOxSnsrNO2Crrctn";
BA_ "SPN" SG_ 2365394174 Aftrtrtmnt2IntkGsNOxSnsrCrrctnOf 5042;
BA_ "SigType" SG_ 2365394174 Aftrtrtmnt2IntkGsNOxSnsrCrrctnOf 1;
BA_ "SystemSignalLongSymbol" SG_ 2365394174 Aftrtrtmnt2IntkGsNOxSnsrCrrctnOf "Aftrtrtmnt2IntkGsNOxSnsrCrrctnOfPrssNx";
BA_ "SPN" SG_ 2365394174 Aftrtrtmnt2IntkGsNOxSnsrCrr_0000 5041;
BA_ "SigType" SG_ 2365394174 Aftrtrtmnt2IntkGsNOxSnsrCrr_0000 1;
BA_ "SystemSignalLongSymbol" SG_ 2365394174 Aftrtrtmnt2IntkGsNOxSnsrCrr_0000 "Aftrtrtmnt2IntkGsNOxSnsrCrrctnOfPrssLmbd";
BA_ "SPN" SG_ 2365394430 Aftrtrtmnt2IntkGsNOxSnsrNwPrtDvt 5040;
BA_ "SigType" SG_ 2365394430 Aftrtrtmnt2IntkGsNOxSnsrNwPrtDvt 1;
BA_ "SystemSignalLongSymbol" SG_ 2365394430 Aftrtrtmnt2IntkGsNOxSnsrNwPrtDvt "Aftrtrtmnt2IntkGsNOxSnsrNwPrtDvtnNOxOffst";
BA_ "SPN" SG_ 2365394430 Aftrtrtmnt2IntkGsNOxSnsrNwP_0000 5039;
BA_ "SigType" SG_ 2365394430 Aftrtrtmnt2IntkGsNOxSnsrNwP_0000 1;
BA_ "SystemSignalLongSymbol" SG_ 2365394430 Aftrtrtmnt2IntkGsNOxSnsrNwP_0000 "Aftrtrtmnt2IntkGsNOxSnsrNwPrtDvtnNOxGn";
BA_ "SPN" SG_ 2365394430 Aftrtrtmnt2IntkGsNOxSnsrHtrRtio 5038;
BA_ "SigType" SG_ 2365394430 Aftrtrtmnt2IntkGsNOxSnsrHtrRtio 1;
BA_ "SPN" SG_ 2566735102 Aftertreatment2FuelPress2Ctrl 5428;
BA_ "SigType" SG_ 2566735102 Aftertreatment2FuelPress2Ctrl 1;
BA_ "SPN" SG_ 2566735102 Aftrtrtmnt2FlFlwDvrterValveCtrl 5427;
BA_ "SigType" SG_ 2566735102 Aftrtrtmnt2FlFlwDvrterValveCtrl 4;
BA_ "SPN" SG_ 2566735102 Aftrtreatment2FuelPumpRelayCtrl 5426;
BA_ "SigType" SG_ 2566735102 Aftrtreatment2FuelPumpRelayCtrl 4;
BA_ "SPN" SG_ 2566735102 Aftertreatment2FuelPress2 4303;
BA_ "SigType" SG_ 2566735102 Aftertreatment2FuelPress2 1;
BA_ "SPN" SG_ 2157313790 Aftrtrtmnt2DslPrtcltFltrStStndrd 5498;
BA_ "SigType" SG_ 2157313790 Aftrtrtmnt2DslPrtcltFltrStStndrd 1;
BA_ "SystemSignalLongSymbol" SG_ 2157313790 Aftrtrtmnt2DslPrtcltFltrStStndrd "Aftrtrtmnt2DslPrtcltFltrStStndrdDvtnClbOffst";
BA_ "SPN" SG_ 2157313790 Aftrtrtmnt2DslPrtcltFltrStMnClbO 5497;
BA_ "SigType" SG_ 2157313790 Aftrtrtmnt2DslPrtcltFltrStMnClbO 1;
BA_ "SystemSignalLongSymbol" SG_ 2157313790 Aftrtrtmnt2DslPrtcltFltrStMnClbO "Aftrtrtmnt2DslPrtcltFltrStMnClbOffst";
BA_ "SPN" SG_ 2566724350 Aftrtrtmnt1WrmUpDslOxdtnCtlystOt 4810;
BA_ "SigType" SG_ 2566724350 Aftrtrtmnt1WrmUpDslOxdtnCtlystOt 1;
BA_ "SystemSignalLongSymbol" SG_ 2566724350 Aftrtrtmnt1WrmUpDslOxdtnCtlystOt "Aftrtrtmnt1WrmUpDslOxdtnCtlystOtltTmp";
BA_ "SPN" SG_ 2566724350 Aftrtrtmnt1WrmUpDslOxdtnCtlystIn 4809;
BA_ "SigType" SG_ 2566724350 Aftrtrtmnt1WrmUpDslOxdtnCtlystIn 1;
BA_ "SystemSignalLongSymbol" SG_ 2566724350 Aftrtrtmnt1WrmUpDslOxdtnCtlystIn "Aftrtrtmnt1WrmUpDslOxdtnCtlystIntkTmp";
BA_ "SPN" SG_ 2566735614 Aftrtrtmnt1ThrWyCtlytcCnvrtrDffP 4294;
BA_ "SigType" SG_ 2566735614 Aftrtrtmnt1ThrWyCtlytcCnvrtrDffP 1;
BA_ "SystemSignalLongSymbol" SG_ 2566735614 Aftrtrtmnt1ThrWyCtlytcCnvrtrDffP "Aftrtrtmnt1ThrWyCtlytcCnvrtrDffPrssPrlmnryFMI";
BA_ "SPN" SG_ 2566735614 Aftrtrtmnt1ThrWyCtlytcCnvrtrOtlt 4293;
BA_ "SigType" SG_ 2566735614 Aftrtrtmnt1ThrWyCtlytcCnvrtrOtlt 1;
BA_ "SystemSignalLongSymbol" SG_ 2566735614 Aftrtrtmnt1ThrWyCtlytcCnvrtrOtlt "Aftrtrtmnt1ThrWyCtlytcCnvrtrOtltGsTmpPrlmnryFMI";
BA_ "SPN" SG_ 2566735614 Aftrtrtmnt1ThrWyCtlytcCnvrtrIntk 4292;
BA_ "SigType" SG_ 2566735614 Aftrtrtmnt1ThrWyCtlytcCnvrtrIntk 1;
BA_ "SystemSignalLongSymbol" SG_ 2566735614 Aftrtrtmnt1ThrWyCtlytcCnvrtrIntk "Aftrtrtmnt1ThrWyCtlytcCnvrtrIntkGsTmpPrlmnryFMI";
BA_ "SPN" SG_ 2566735614 Aftrtrtmnt1ThrWyCtlytcCnvrt_0000 4291;
BA_ "SigType" SG_ 2566735614 Aftrtrtmnt1ThrWyCtlytcCnvrt_0000 1;
BA_ "SystemSignalLongSymbol" SG_ 2566735614 Aftrtrtmnt1ThrWyCtlytcCnvrt_0000 "Aftrtrtmnt1ThrWyCtlytcCnvrtrDffPrss";
BA_ "SPN" SG_ 2566735614 Aftrtrtmnt1ThrWyCtlytcCnvrt_0001 4290;
BA_ "SigType" SG_ 2566735614 Aftrtrtmnt1ThrWyCtlytcCnvrt_0001 1;
BA_ "SystemSignalLongSymbol" SG_ 2566735614 Aftrtrtmnt1ThrWyCtlytcCnvrt_0001 "Aftrtrtmnt1ThrWyCtlytcCnvrtrOtltGsTmp";
BA_ "SPN" SG_ 2566735614 Aftrtrtmnt1ThrWyCtlytcCnvrt_0002 4289;
BA_ "SigType" SG_ 2566735614 Aftrtrtmnt1ThrWyCtlytcCnvrt_0002 1;
BA_ "SystemSignalLongSymbol" SG_ 2566735614 Aftrtrtmnt1ThrWyCtlytcCnvrt_0002 "Aftrtrtmnt1ThrWyCtlytcCnvrtrIntkGsTmp";
BA_ "SPN" SG_ 2566805246 Aftrtrtmnt1SCRCtlystRgntTnk1HtrP 4366;
BA_ "SigType" SG_ 2566805246 Aftrtrtmnt1SCRCtlystRgntTnk1HtrP 1;
BA_ "SystemSignalLongSymbol" SG_ 2566805246 Aftrtrtmnt1SCRCtlystRgntTnk1HtrP "Aftrtrtmnt1SCRCtlystRgntTnk1HtrPrlmnryFMI";
BA_ "SPN" SG_ 2566805246 Aftrtrtmnt1SCRCtalystTankHeater 3363;
BA_ "SigType" SG_ 2566805246 Aftrtrtmnt1SCRCtalystTankHeater 1;
BA_ "SPN" SG_ 2566805246 AftrtrtmntSCROprtrIndcmntSvrity 5246;
BA_ "SigType" SG_ 2566805246 AftrtrtmntSCROprtrIndcmntSvrity 4;
BA_ "SPN" SG_ 2566805246 Aftrtrtmnt1SCRCtlystRgntTnk1TmpP 4365;
BA_ "SigType" SG_ 2566805246 Aftrtrtmnt1SCRCtlystRgntTnk1TmpP 1;
BA_ "SystemSignalLongSymbol" SG_ 2566805246 Aftrtrtmnt1SCRCtlystRgntTnk1TmpP "Aftrtrtmnt1SCRCtlystRgntTnk1TmpPrlmnryFMI";
BA_ "SPN" SG_ 2566805246 Aftrtrtmnt1DEFTnkLwLvlIndicator 5245;
BA_ "SigType" SG_ 2566805246 Aftrtrtmnt1DEFTnkLwLvlIndicator 4;
BA_ "SPN" SG_ 2566805246 Aftrtrtmnt1SCRCtlystTnkLvlPrlmnr 3532;
BA_ "SigType" SG_ 2566805246 Aftrtrtmnt1SCRCtlystTnkLvlPrlmnr 1;
BA_ "SystemSignalLongSymbol" SG_ 2566805246 Aftrtrtmnt1SCRCtlystTnkLvlPrlmnr "Aftrtrtmnt1SCRCtlystTnkLvlPrlmnryFMI";
BA_ "SPN" SG_ 2566805246 Aftrtrtmnt1SCRCtalystTankLevel2 3517;
BA_ "SigType" SG_ 2566805246 Aftrtrtmnt1SCRCtalystTankLevel2 1;
BA_ "SPN" SG_ 2566805246 Aftrtrtment1SCRCatalystTankTemp 3031;
BA_ "SigType" SG_ 2566805246 Aftrtrtment1SCRCatalystTankTemp 1;
BA_ "SPN" SG_ 2566805246 Aftrtrtmnt1SCRCatalystTankLevel 1761;
BA_ "SigType" SG_ 2566805246 Aftrtrtmnt1SCRCatalystTankLevel 1;
BA_ "SPN" SG_ 2566804992 Aftrtrtmnt1SCRCtlystRgntTnk1HtrP 4366;
BA_ "SigType" SG_ 2566804992 Aftrtrtmnt1SCRCtlystRgntTnk1HtrP 1;
BA_ "SystemSignalLongSymbol" SG_ 2566804992 Aftrtrtmnt1SCRCtlystRgntTnk1HtrP "Aftrtrtmnt1SCRCtlystRgntTnk1HtrPrlmnryFMI";
BA_ "SPN" SG_ 2566804992 Aftrtrtmnt1SCRCtalystTankHeater 3363;
BA_ "SigType" SG_ 2566804992 Aftrtrtmnt1SCRCtalystTankHeater 1;
BA_ "SPN" SG_ 2566804992 AftrtrtmntSCROprtrIndcmntSvrity 5246;
BA_ "SigType" SG_ 2566804992 AftrtrtmntSCROprtrIndcmntSvrity 4;
BA_ "SPN" SG_ 2566804992 Aftrtrtmnt1SCRCtlystRgntTnk1TmpP 4365;
BA_ "SigType" SG_ 2566804992 Aftrtrtmnt1SCRCtlystRgntTnk1TmpP 1;
BA_ "SystemSignalLongSymbol" SG_ 2566804992 Aftrtrtmnt1SCRCtlystRgntTnk1TmpP "Aftrtrtmnt1SCRCtlystRgntTnk1TmpPrlmnryFMI";
BA_ "SPN" SG_ 2566804992 Aftrtrtmnt1DEFTnkLwLvlIndicator 5245;
BA_ "SigType" SG_ 2566804992 Aftrtrtmnt1DEFTnkLwLvlIndicator 4;
BA_ "SPN" SG_ 2566804992 Aftrtrtmnt1SCRCtlystTnkLvlPrlmnr 3532;
BA_ "SigType" SG_ 2566804992 Aftrtrtmnt1SCRCtlystTnkLvlPrlmnr 1;
BA_ "SystemSignalLongSymbol" SG_ 2566804992 Aftrtrtmnt1SCRCtlystTnkLvlPrlmnr "Aftrtrtmnt1SCRCtlystTnkLvlPrlmnryFMI";
BA_ "SPN" SG_ 2566804992 Aftrtrtmnt1SCRCtalystTankLevel2 3517;
BA_ "SigType" SG_ 2566804992 Aftrtrtmnt1SCRCtalystTankLevel2 1;
BA_ "SPN" SG_ 2566804992 Aftrtrtment1SCRCatalystTankTemp 3031;
BA_ "SigType" SG_ 2566804992 Aftrtrtment1SCRCatalystTankTemp 1;
BA_ "SPN" SG_ 2566804992 Aftrtrtmnt1SCRCatalystTankLevel 1761;
BA_ "SigType" SG_ 2566804992 Aftrtrtmnt1SCRCatalystTankLevel 1;
BA_ "SPN" SG_ 2365394686 Aftrtrtmnt1OtltGsNOxSnsrNH3Crrct 5037;
BA_ "SigType" SG_ 2365394686 Aftrtrtmnt1OtltGsNOxSnsrNH3Crrct 1;
BA_ "SystemSignalLongSymbol" SG_ 2365394686 Aftrtrtmnt1OtltGsNOxSnsrNH3Crrct "Aftrtrtmnt1OtltGsNOxSnsrNH3Crrctn";
BA_ "SPN" SG_ 2365394686 Aftrtrtmnt1OtltGsNOxSnsrNO2Crrct 5036;
BA_ "SigType" SG_ 2365394686 Aftrtrtmnt1OtltGsNOxSnsrNO2Crrct 1;
BA_ "SystemSignalLongSymbol" SG_ 2365394686 Aftrtrtmnt1OtltGsNOxSnsrNO2Crrct "Aftrtrtmnt1OtltGsNOxSnsrNO2Crrctn";
BA_ "SPN" SG_ 2365394686 Aftrtrtmnt1OtltGsNOxSnsrCrrctnOf 5035;
BA_ "SigType" SG_ 2365394686 Aftrtrtmnt1OtltGsNOxSnsrCrrctnOf 1;
BA_ "SystemSignalLongSymbol" SG_ 2365394686 Aftrtrtmnt1OtltGsNOxSnsrCrrctnOf "Aftrtrtmnt1OtltGsNOxSnsrCrrctnOfPrssNx";
BA_ "SPN" SG_ 2365394686 Aftrtrtmnt1OtltGsNOxSnsrCrr_0000 5034;
BA_ "SigType" SG_ 2365394686 Aftrtrtmnt1OtltGsNOxSnsrCrr_0000 1;
BA_ "SystemSignalLongSymbol" SG_ 2365394686 Aftrtrtmnt1OtltGsNOxSnsrCrr_0000 "Aftrtrtmnt1OtltGsNOxSnsrCrrctnOfPrssLmbd";
BA_ "SPN" SG_ 2365394942 Aftrtrtmnt1OtltGsNOxSnsrNwPrtDvt 5033;
BA_ "SigType" SG_ 2365394942 Aftrtrtmnt1OtltGsNOxSnsrNwPrtDvt 1;
BA_ "SystemSignalLongSymbol" SG_ 2365394942 Aftrtrtmnt1OtltGsNOxSnsrNwPrtDvt "Aftrtrtmnt1OtltGsNOxSnsrNwPrtDvtnNOxOffst";
BA_ "SPN" SG_ 2365394942 Aftrtrtmnt1OtltGsNOxSnsrNwP_0000 5032;
BA_ "SigType" SG_ 2365394942 Aftrtrtmnt1OtltGsNOxSnsrNwP_0000 1;
BA_ "SystemSignalLongSymbol" SG_ 2365394942 Aftrtrtmnt1OtltGsNOxSnsrNwP_0000 "Aftrtrtmnt1OtltGsNOxSnsrNwPrtDvtnNOxGn";
BA_ "SPN" SG_ 2365394942 Aftrtrtmnt1OtltGsNOxSnsrHtrRtio 5031;
BA_ "SigType" SG_ 2365394942 Aftrtrtmnt1OtltGsNOxSnsrHtrRtio 1;
BA_ "SPN" SG_ 2365395198 Aftrtrtmnt1IntkGsNOxSnsrNH3Crrct 5030;
BA_ "SigType" SG_ 2365395198 Aftrtrtmnt1IntkGsNOxSnsrNH3Crrct 1;
BA_ "SystemSignalLongSymbol" SG_ 2365395198 Aftrtrtmnt1IntkGsNOxSnsrNH3Crrct "Aftrtrtmnt1IntkGsNOxSnsrNH3Crrctn";
BA_ "SPN" SG_ 2365395198 Aftrtrtmnt1IntkGsNOxSnsrNO2Crrct 5029;
BA_ "SigType" SG_ 2365395198 Aftrtrtmnt1IntkGsNOxSnsrNO2Crrct 1;
BA_ "SystemSignalLongSymbol" SG_ 2365395198 Aftrtrtmnt1IntkGsNOxSnsrNO2Crrct "Aftrtrtmnt1IntkGsNOxSnsrNO2Crrctn";
BA_ "SPN" SG_ 2365395198 Aftrtrtmnt1IntkGsNOxSnsrCrrctnOf 5028;
BA_ "SigType" SG_ 2365395198 Aftrtrtmnt1IntkGsNOxSnsrCrrctnOf 1;
BA_ "SystemSignalLongSymbol" SG_ 2365395198 Aftrtrtmnt1IntkGsNOxSnsrCrrctnOf "Aftrtrtmnt1IntkGsNOxSnsrCrrctnOfPrssNx";
BA_ "SPN" SG_ 2365395198 Aftrtrtmnt1IntkGsNOxSnsrCrr_0000 5027;
BA_ "SigType" SG_ 2365395198 Aftrtrtmnt1IntkGsNOxSnsrCrr_0000 1;
BA_ "SystemSignalLongSymbol" SG_ 2365395198 Aftrtrtmnt1IntkGsNOxSnsrCrr_0000 "Aftrtrtmnt1IntkGsNOxSnsrCrrctnOfPrssLmbd";
BA_ "SPN" SG_ 2365395454 Aftrtrtmnt1IntkGsNOxSnsrNwPrtDvt 5026;
BA_ "SigType" SG_ 2365395454 Aftrtrtmnt1IntkGsNOxSnsrNwPrtDvt 1;
BA_ "SystemSignalLongSymbol" SG_ 2365395454 Aftrtrtmnt1IntkGsNOxSnsrNwPrtDvt "Aftrtrtmnt1IntkGsNOxSnsrNwPrtDvtnNOxOffst";
BA_ "SPN" SG_ 2365395454 Aftrtrtmnt1IntkGsNOxSnsrNwP_0000 5025;
BA_ "SigType" SG_ 2365395454 Aftrtrtmnt1IntkGsNOxSnsrNwP_0000 1;
BA_ "SystemSignalLongSymbol" SG_ 2365395454 Aftrtrtmnt1IntkGsNOxSnsrNwP_0000 "Aftrtrtmnt1IntkGsNOxSnsrNwPrtDvtnNOxGn";
BA_ "SPN" SG_ 2365395454 Aftrtrtmnt1IntkGsNOxSnsrHtrRtio 5024;
BA_ "SigType" SG_ 2365395454 Aftrtrtmnt1IntkGsNOxSnsrHtrRtio 1;
BA_ "SPN" SG_ 2157248254 Aftrtrtmnt1DslPrtcltFltrStStndrd 5496;
BA_ "SigType" SG_ 2157248254 Aftrtrtmnt1DslPrtcltFltrStStndrd 1;
BA_ "SystemSignalLongSymbol" SG_ 2157248254 Aftrtrtmnt1DslPrtcltFltrStStndrd "Aftrtrtmnt1DslPrtcltFltrStStndrdDvtnClbOffst";
BA_ "SPN" SG_ 2157248254 Aftrtrtmnt1DslPrtcltFltrStMnClbO 5495;
BA_ "SigType" SG_ 2157248254 Aftrtrtmnt1DslPrtcltFltrStMnClbO 1;
BA_ "SystemSignalLongSymbol" SG_ 2157248254 Aftrtrtmnt1DslPrtcltFltrStMnClbO "Aftrtrtmnt1DslPrtcltFltrStMnClbOffst";
BA_ "SPN" SG_ 2566711806 ArmrestSwitchMatrix2Switch2 5494;
BA_ "SigType" SG_ 2566711806 ArmrestSwitchMatrix2Switch2 4;
BA_ "SPN" SG_ 2566711806 ArmrestSwitchMatrix2Switch1 5493;
BA_ "SigType" SG_ 2566711806 ArmrestSwitchMatrix2Switch1 4;
BA_ "SPN" SG_ 2566711806 ArmrestSwitchMatrixSwitch2 5492;
BA_ "SigType" SG_ 2566711806 ArmrestSwitchMatrixSwitch2 4;
BA_ "SPN" SG_ 2566711806 ArmrestSwitchMatrixSwitch1 1503;
BA_ "SigType" SG_ 2566711806 ArmrestSwitchMatrixSwitch1 4;
BA_ "SPN" SG_ 2364549886 AngularRateMeasurementLatency 4989;
BA_ "SigType" SG_ 2364549886 AngularRateMeasurementLatency 1;
BA_ "SPN" SG_ 2364549886 YawRateExRangeFigureOfMerit 4988;
BA_ "SigType" SG_ 2364549886 YawRateExRangeFigureOfMerit 4;
BA_ "SPN" SG_ 2364549886 RollRateExRangeFigureOfMerit 4987;
BA_ "SigType" SG_ 2364549886 RollRateExRangeFigureOfMerit 4;
BA_ "SPN" SG_ 2364549886 PitchRateExRangeFigureOfMerit 4986;
BA_ "SigType" SG_ 2364549886 PitchRateExRangeFigureOfMerit 4;
BA_ "SPN" SG_ 2364549886 YawRateExRange 4985;
BA_ "SigType" SG_ 2364549886 YawRateExRange 1;
BA_ "SPN" SG_ 2364549886 RollRateExRange 4984;
BA_ "SigType" SG_ 2364549886 RollRateExRange 1;
BA_ "SPN" SG_ 2364549886 PitchRateExRange 4983;
BA_ "SigType" SG_ 2364549886 PitchRateExRange 1;
BA_ "SPN" SG_ 2566712318 Aftrtrtmnt2NOxAdsrbrDSOxRgnrtnSt 5462;
BA_ "SigType" SG_ 2566712318 Aftrtrtmnt2NOxAdsrbrDSOxRgnrtnSt 4;
BA_ "SystemSignalLongSymbol" SG_ 2566712318 Aftrtrtmnt2NOxAdsrbrDSOxRgnrtnSt "Aftrtrtmnt2NOxAdsrbrDSOxRgnrtnStts";
BA_ "SPN" SG_ 2566712318 Aftrtrtmnt2NOxAdsrbrDNOxRgnrtnSt 5460;
BA_ "SigType" SG_ 2566712318 Aftrtrtmnt2NOxAdsrbrDNOxRgnrtnSt 4;
BA_ "SystemSignalLongSymbol" SG_ 2566712318 Aftrtrtmnt2NOxAdsrbrDNOxRgnrtnSt "Aftrtrtmnt2NOxAdsrbrDNOxRgnrtnStts";
BA_ "SPN" SG_ 2566712574 Aftrtrtmnt1NOxAdsrbrDSOxRgnrtnSt 5461;
BA_ "SigType" SG_ 2566712574 Aftrtrtmnt1NOxAdsrbrDSOxRgnrtnSt 4;
BA_ "SystemSignalLongSymbol" SG_ 2566712574 Aftrtrtmnt1NOxAdsrbrDSOxRgnrtnSt "Aftrtrtmnt1NOxAdsrbrDSOxRgnrtnStts";
BA_ "SPN" SG_ 2566712574 Aftrtrtmnt1NOxAdsrbrDNOxRgnrtnSt 5459;
BA_ "SigType" SG_ 2566712574 Aftrtrtmnt1NOxAdsrbrDNOxRgnrtnSt 4;
BA_ "SystemSignalLongSymbol" SG_ 2566712574 Aftrtrtmnt1NOxAdsrbrDNOxRgnrtnSt "Aftrtrtmnt1NOxAdsrbrDNOxRgnrtnStts";
BA_ "SPN" SG_ 2164078590 Aftrtrtmnt2SCRCtlystCnvrsnEffcnc 4419;
BA_ "SigType" SG_ 2164078590 Aftrtrtmnt2SCRCtlystCnvrsnEffcnc 1;
BA_ "SystemSignalLongSymbol" SG_ 2164078590 Aftrtrtmnt2SCRCtlystCnvrsnEffcnc "Aftrtrtmnt2SCRCtlystCnvrsnEffcncy";
BA_ "SPN" SG_ 2164078590 Aftrtrtmnt2SCRCmddCtlystRgntCnsm 4418;
BA_ "SigType" SG_ 2164078590 Aftrtrtmnt2SCRCmddCtlystRgntCnsm 1;
BA_ "SystemSignalLongSymbol" SG_ 2164078590 Aftrtrtmnt2SCRCmddCtlystRgntCnsm "Aftrtrtmnt2SCRCmddCtlystRgntCnsmptn";
BA_ "SPN" SG_ 2164078590 Aftrtrtmnt2SCRAvrgCtlystRgntCnsm 4417;
BA_ "SigType" SG_ 2164078590 Aftrtrtmnt2SCRAvrgCtlystRgntCnsm 1;
BA_ "SystemSignalLongSymbol" SG_ 2164078590 Aftrtrtmnt2SCRAvrgCtlystRgntCnsm "Aftrtrtmnt2SCRAvrgCtlystRgntCnsmptn";
BA_ "SPN" SG_ 2566731006 Aftrtrtmnt2SCRCtlystRgntTnk2HtrP 4439;
BA_ "SigType" SG_ 2566731006 Aftrtrtmnt2SCRCtlystRgntTnk2HtrP 1;
BA_ "SystemSignalLongSymbol" SG_ 2566731006 Aftrtrtmnt2SCRCtlystRgntTnk2HtrP "Aftrtrtmnt2SCRCtlystRgntTnk2HtrPrlmnryFMI";
BA_ "SPN" SG_ 2566731006 Aftrtrtmnt2SCRCtlystRgntTnk2Htr 4438;
BA_ "SigType" SG_ 2566731006 Aftrtrtmnt2SCRCtlystRgntTnk2Htr 4;
BA_ "SPN" SG_ 2566731006 Aftrtrtmnt2SCRRgntTnk2TmpPrlmnry 4437;
BA_ "SigType" SG_ 2566731006 Aftrtrtmnt2SCRRgntTnk2TmpPrlmnry 1;
BA_ "SystemSignalLongSymbol" SG_ 2566731006 Aftrtrtmnt2SCRRgntTnk2TmpPrlmnry "Aftrtrtmnt2SCRRgntTnk2TmpPrlmnryFMI";
BA_ "SPN" SG_ 2566731006 Aftrtrtmnt2SCRCtlystRgntTnk2LvlP 4436;
BA_ "SigType" SG_ 2566731006 Aftrtrtmnt2SCRCtlystRgntTnk2LvlP 1;
BA_ "SystemSignalLongSymbol" SG_ 2566731006 Aftrtrtmnt2SCRCtlystRgntTnk2LvlP "Aftrtrtmnt2SCRCtlystRgntTnk2LvlPrlmnryFMI";
BA_ "SPN" SG_ 2566731006 Aftrtrtmnt2SCRCtlystRgntTnk2Lvl2 4435;
BA_ "SigType" SG_ 2566731006 Aftrtrtmnt2SCRCtlystRgntTnk2Lvl2 1;
BA_ "SPN" SG_ 2566731006 Aftrtrtmnt2SCRCtlystRgntTnk2Tmp 4434;
BA_ "SigType" SG_ 2566731006 Aftrtrtmnt2SCRCtlystRgntTnk2Tmp 1;
BA_ "SPN" SG_ 2566731006 Aftrtrtmnt2SCRCtlystRgntTnk2Lvl 4433;
BA_ "SigType" SG_ 2566731006 Aftrtrtmnt2SCRCtlystRgntTnk2Lvl 1;
BA_ "SPN" SG_ 2566731262 Aftrtrtmnt2SCRCtlystRgntTnk1HtrP 4432;
BA_ "SigType" SG_ 2566731262 Aftrtrtmnt2SCRCtlystRgntTnk1HtrP 1;
BA_ "SystemSignalLongSymbol" SG_ 2566731262 Aftrtrtmnt2SCRCtlystRgntTnk1HtrP "Aftrtrtmnt2SCRCtlystRgntTnk1HtrPrlmnryFMI";
BA_ "SPN" SG_ 2566731262 Aftrtrtmnt2SCRCtalystTankHeater 4431;
BA_ "SigType" SG_ 2566731262 Aftrtrtmnt2SCRCtalystTankHeater 1;
BA_ "SPN" SG_ 2566731262 Aftrtrtmnt2SCRCtlystRgntTnk1TmpP 4430;
BA_ "SigType" SG_ 2566731262 Aftrtrtmnt2SCRCtlystRgntTnk1TmpP 1;
BA_ "SystemSignalLongSymbol" SG_ 2566731262 Aftrtrtmnt2SCRCtlystRgntTnk1TmpP "Aftrtrtmnt2SCRCtlystRgntTnk1TmpPrlmnryFMI";
BA_ "SPN" SG_ 2566731262 Aftrtrtmnt2SCRCtlystTnkLvlPrlmnr 4429;
BA_ "SigType" SG_ 2566731262 Aftrtrtmnt2SCRCtlystTnkLvlPrlmnr 1;
BA_ "SystemSignalLongSymbol" SG_ 2566731262 Aftrtrtmnt2SCRCtlystTnkLvlPrlmnr "Aftrtrtmnt2SCRCtlystTnkLvlPrlmnryFMI";
BA_ "SPN" SG_ 2566731262 Aftrtrtmnt2SCRCtalystTankLevel2 4428;
BA_ "SigType" SG_ 2566731262 Aftrtrtmnt2SCRCtalystTankLevel2 1;
BA_ "SPN" SG_ 2566731262 Aftrtrtment2SCRCatalystTankTemp 4427;
BA_ "SigType" SG_ 2566731262 Aftrtrtment2SCRCatalystTankTemp 1;
BA_ "SPN" SG_ 2566731262 Aftrtrtmnt2SCRCatalystTankLevel 4426;
BA_ "SigType" SG_ 2566731262 Aftrtrtmnt2SCRCatalystTankLevel 1;
BA_ "SPN" SG_ 2566730750 Aftrtrtmnt2SCRCtlystRgntTnkDrnVl 5439;
BA_ "SigType" SG_ 2566730750 Aftrtrtmnt2SCRCtlystRgntTnkDrnVl 1;
BA_ "SystemSignalLongSymbol" SG_ 2566730750 Aftrtrtmnt2SCRCtlystRgntTnkDrnVl "Aftrtrtmnt2SCRCtlystRgntTnkDrnVlvCmd";
BA_ "SPN" SG_ 2566730750 Aftrtrtmnt2SCRCtlystRgntPmpStte 5438;
BA_ "SigType" SG_ 2566730750 Aftrtrtmnt2SCRCtlystRgntPmpStte 4;
BA_ "SPN" SG_ 2566730750 Aftrtrtmnt2SCRCtlystRgntTnkFllVl 5437;
BA_ "SigType" SG_ 2566730750 Aftrtrtmnt2SCRCtlystRgntTnkFllVl 1;
BA_ "SystemSignalLongSymbol" SG_ 2566730750 Aftrtrtmnt2SCRCtlystRgntTnkFllVl "Aftrtrtmnt2SCRCtlystRgntTnkFllVlvCmd";
BA_ "SPN" SG_ 2566730750 Aftrtrtmnt2SCRCtlystRgntRtrnVlv 4442;
BA_ "SigType" SG_ 2566730750 Aftrtrtmnt2SCRCtlystRgntRtrnVlv 1;
BA_ "SPN" SG_ 2566730750 Aftrtrtmnt2SCRCtlystRgntPmpDrvPr 4441;
BA_ "SigType" SG_ 2566730750 Aftrtrtmnt2SCRCtlystRgntPmpDrvPr 1;
BA_ "SystemSignalLongSymbol" SG_ 2566730750 Aftrtrtmnt2SCRCtlystRgntPmpDrvPr "Aftrtrtmnt2SCRCtlystRgntPmpDrvPrcntg";
BA_ "SPN" SG_ 2566730750 Aftrtrtmnt2SCRCtlystRgntPmpMtrSp 4440;
BA_ "SigType" SG_ 2566730750 Aftrtrtmnt2SCRCtlystRgntPmpMtrSp 1;
BA_ "SystemSignalLongSymbol" SG_ 2566730750 Aftrtrtmnt2SCRCtlystRgntPmpMtrSp "Aftrtrtmnt2SCRCtlystRgntPmpMtrSpd";
BA_ "SPN" SG_ 2566731518 Aftrtrtmnt2SCRCtlystReagentType 4425;
BA_ "SigType" SG_ 2566731518 Aftrtrtmnt2SCRCtlystReagentType 4;
BA_ "SPN" SG_ 2566731518 Aftrtrtmnt2SCRCtlystRgntPrprtsPr 4424;
BA_ "SigType" SG_ 2566731518 Aftrtrtmnt2SCRCtlystRgntPrprtsPr 1;
BA_ "SystemSignalLongSymbol" SG_ 2566731518 Aftrtrtmnt2SCRCtlystRgntPrprtsPr "Aftrtrtmnt2SCRCtlystRgntPrprtsPrlmnryFMI";
BA_ "SPN" SG_ 2566731518 Aftrtrtmnt2SCRCtlystRgntTmp2Prlm 4423;
BA_ "SigType" SG_ 2566731518 Aftrtrtmnt2SCRCtlystRgntTmp2Prlm 1;
BA_ "SystemSignalLongSymbol" SG_ 2566731518 Aftrtrtmnt2SCRCtlystRgntTmp2Prlm "Aftrtrtmnt2SCRCtlystRgntTmp2PrlmnryFMI";
BA_ "SPN" SG_ 2566731518 Aftrtrtmnt2SCRCtlystRgntCndctvty 4422;
BA_ "SigType" SG_ 2566731518 Aftrtrtmnt2SCRCtlystRgntCndctvty 1;
BA_ "SPN" SG_ 2566731518 Aftrtrtmnt2SCRCtlystRgntCncntrtn 4421;
BA_ "SigType" SG_ 2566731518 Aftrtrtmnt2SCRCtlystRgntCncntrtn 1;
BA_ "SPN" SG_ 2566731518 Aftrtrtmnt2SCRCtlystRagentTemp2 4420;
BA_ "SigType" SG_ 2566731518 Aftrtrtmnt2SCRCtlystRagentTemp2 1;
BA_ "SPN" SG_ 2566732030 Aftrtrtmnt2SCRCtlystOtltGsTmpPrl 4416;
BA_ "SigType" SG_ 2566732030 Aftrtrtmnt2SCRCtlystOtltGsTmpPrl 4;
BA_ "SystemSignalLongSymbol" SG_ 2566732030 Aftrtrtmnt2SCRCtlystOtltGsTmpPrl "Aftrtrtmnt2SCRCtlystOtltGsTmpPrlmnryFMI";
BA_ "SPN" SG_ 2566732030 Aftrtrtmnt2SCRCtlystOtltGasTemp 4415;
BA_ "SigType" SG_ 2566732030 Aftrtrtmnt2SCRCtlystOtltGasTemp 1;
BA_ "SPN" SG_ 2566732030 Aftrtrtmnt2SCRCtlystIntkGsTmpPrl 4414;
BA_ "SigType" SG_ 2566732030 Aftrtrtmnt2SCRCtlystIntkGsTmpPrl 4;
BA_ "SystemSignalLongSymbol" SG_ 2566732030 Aftrtrtmnt2SCRCtlystIntkGsTmpPrl "Aftrtrtmnt2SCRCtlystIntkGsTmpPrlmnryFMI";
BA_ "SPN" SG_ 2566732030 Aftrtrtmnt2SCRCtlystIntkGasTemp 4413;
BA_ "SigType" SG_ 2566732030 Aftrtrtmnt2SCRCtlystIntkGasTemp 1;
BA_ "SPN" SG_ 2566732286 Aftrtrtmnt2SCRCtlystExhstGsDffPr 4412;
BA_ "SigType" SG_ 2566732286 Aftrtrtmnt2SCRCtlystExhstGsDffPr 4;
BA_ "SystemSignalLongSymbol" SG_ 2566732286 Aftrtrtmnt2SCRCtlystExhstGsDffPr "Aftrtrtmnt2SCRCtlystExhstGsDffPrssPrlmnryFMI";
BA_ "SPN" SG_ 2566732286 Aftrtrtmnt2SCRCtlystExhstGs_0000 4411;
BA_ "SigType" SG_ 2566732286 Aftrtrtmnt2SCRCtlystExhstGs_0000 1;
BA_ "SystemSignalLongSymbol" SG_ 2566732286 Aftrtrtmnt2SCRCtlystExhstGs_0000 "Aftrtrtmnt2SCRCtlystExhstGsDffPrss";
BA_ "SPN" SG_ 2164079358 Aftrtrtmnt2SCRCtlystTnk2HterCmd 5415;
BA_ "SigType" SG_ 2164079358 Aftrtrtmnt2SCRCtlystTnk2HterCmd 1;
BA_ "SPN" SG_ 2164079358 Aftrtrtmnt2SCRCtlystTnkHaterCmd 5138;
BA_ "SigType" SG_ 2164079358 Aftrtrtmnt2SCRCtlystTnkHaterCmd 1;
BA_ "SPN" SG_ 2164079358 Aftrtrtmnt2SCRCtlystRgntLnHter4 4410;
BA_ "SigType" SG_ 2164079358 Aftrtrtmnt2SCRCtlystRgntLnHter4 4;
BA_ "SPN" SG_ 2164079358 Aftrtrtmnt2SCRCtlystRgntLnHter3 4409;
BA_ "SigType" SG_ 2164079358 Aftrtrtmnt2SCRCtlystRgntLnHter3 4;
BA_ "SPN" SG_ 2164079358 Aftrtrtmnt2SCRCtlystRgntLnHter2 4408;
BA_ "SigType" SG_ 2164079358 Aftrtrtmnt2SCRCtlystRgntLnHter2 4;
BA_ "SPN" SG_ 2164079358 Aftrtrtmnt2SCRCtlystRgntLnHter1 4407;
BA_ "SigType" SG_ 2164079358 Aftrtrtmnt2SCRCtlystRgntLnHter1 4;
BA_ "SPN" SG_ 2164079358 Aftrtrtmnt2SCRDserHeatingModeRq 4406;
BA_ "SigType" SG_ 2164079358 Aftrtrtmnt2SCRDserHeatingModeRq 4;
BA_ "SPN" SG_ 2164079358 Aftrtrtmnt2SCRDsrFltSpprssionRq 4405;
BA_ "SigType" SG_ 2164079358 Aftrtrtmnt2SCRDsrFltSpprssionRq 4;
BA_ "SPN" SG_ 2364549118 Aftrtrtmnt2SCRRqdRgntQnttyFrIntg 4403;
BA_ "SigType" SG_ 2364549118 Aftrtrtmnt2SCRRqdRgntQnttyFrIntg 1;
BA_ "SystemSignalLongSymbol" SG_ 2364549118 Aftrtrtmnt2SCRRqdRgntQnttyFrIntg "Aftrtrtmnt2SCRRqdRgntQnttyFrIntgrtr";
BA_ "SPN" SG_ 2364549118 Aftrtratment2SCRSystemRqedState 4402;
BA_ "SigType" SG_ 2364549118 Aftrtratment2SCRSystemRqedState 4;
BA_ "SPN" SG_ 2364549118 Aftrtrtmnt2SCRRqdDsngRgntQntity 4401;
BA_ "SigType" SG_ 2364549118 Aftrtrtmnt2SCRRqdDsngRgntQntity 1;
BA_ "SPN" SG_ 2566732798 Aftrtrtmnt2SCRCtlystRgntLnHtr4Pr 4400;
BA_ "SigType" SG_ 2566732798 Aftrtrtmnt2SCRCtlystRgntLnHtr4Pr 1;
BA_ "SystemSignalLongSymbol" SG_ 2566732798 Aftrtrtmnt2SCRCtlystRgntLnHtr4Pr "Aftrtrtmnt2SCRCtlystRgntLnHtr4PrlmnryFMI";
BA_ "SPN" SG_ 2566732798 Aftrtrtmnt2SCRCtlystRgntLnHtr4St 4399;
BA_ "SigType" SG_ 2566732798 Aftrtrtmnt2SCRCtlystRgntLnHtr4St 4;
BA_ "SystemSignalLongSymbol" SG_ 2566732798 Aftrtrtmnt2SCRCtlystRgntLnHtr4St "Aftrtrtmnt2SCRCtlystRgntLnHtr4Stt";
BA_ "SPN" SG_ 2566732798 Aftrtrtmnt2SCRCtlystRgntLnHtr3Pr 4398;
BA_ "SigType" SG_ 2566732798 Aftrtrtmnt2SCRCtlystRgntLnHtr3Pr 1;
BA_ "SystemSignalLongSymbol" SG_ 2566732798 Aftrtrtmnt2SCRCtlystRgntLnHtr3Pr "Aftrtrtmnt2SCRCtlystRgntLnHtr3PrlmnryFMI";
BA_ "SPN" SG_ 2566732798 Aftrtrtmnt2SCRCtlystRgntLnHtr3St 4397;
BA_ "SigType" SG_ 2566732798 Aftrtrtmnt2SCRCtlystRgntLnHtr3St 4;
BA_ "SystemSignalLongSymbol" SG_ 2566732798 Aftrtrtmnt2SCRCtlystRgntLnHtr3St "Aftrtrtmnt2SCRCtlystRgntLnHtr3Stt";
BA_ "SPN" SG_ 2566732798 Aftrtrtmnt2SCRCtlystRgntLnHtr2Pr 4396;
BA_ "SigType" SG_ 2566732798 Aftrtrtmnt2SCRCtlystRgntLnHtr2Pr 1;
BA_ "SystemSignalLongSymbol" SG_ 2566732798 Aftrtrtmnt2SCRCtlystRgntLnHtr2Pr "Aftrtrtmnt2SCRCtlystRgntLnHtr2PrlmnryFMI";
BA_ "SPN" SG_ 2566732798 Aftrtrtmnt2SCRCtlystRgntLnHtr2St 4395;
BA_ "SigType" SG_ 2566732798 Aftrtrtmnt2SCRCtlystRgntLnHtr2St 4;
BA_ "SystemSignalLongSymbol" SG_ 2566732798 Aftrtrtmnt2SCRCtlystRgntLnHtr2St "Aftrtrtmnt2SCRCtlystRgntLnHtr2Stt";
BA_ "SPN" SG_ 2566732798 Aftrtrtmnt2SCRCtlystRgntLnHtr1Pr 4394;
BA_ "SigType" SG_ 2566732798 Aftrtrtmnt2SCRCtlystRgntLnHtr1Pr 1;
BA_ "SystemSignalLongSymbol" SG_ 2566732798 Aftrtrtmnt2SCRCtlystRgntLnHtr1Pr "Aftrtrtmnt2SCRCtlystRgntLnHtr1PrlmnryFMI";
BA_ "SPN" SG_ 2566732798 Aftrtrtmnt2SCRCtlystRgntLnHtr1St 4393;
BA_ "SigType" SG_ 2566732798 Aftrtrtmnt2SCRCtlystRgntLnHtr1St 4;
BA_ "SystemSignalLongSymbol" SG_ 2566732798 Aftrtrtmnt2SCRCtlystRgntLnHtr1St "Aftrtrtmnt2SCRCtlystRgntLnHtr1Stt";
BA_ "SPN" SG_ 2566732798 Aftrtrtmnt2SCRFedbackCtrlStatus 4392;
BA_ "SigType" SG_ 2566732798 Aftrtrtmnt2SCRFedbackCtrlStatus 4;
BA_ "SPN" SG_ 2566732798 Aftrtrtmnt2SCRDsngVlvExhstTmpRdc 4391;
BA_ "SigType" SG_ 2566732798 Aftrtrtmnt2SCRDsngVlvExhstTmpRdc 4;
BA_ "SystemSignalLongSymbol" SG_ 2566732798 Aftrtrtmnt2SCRDsngVlvExhstTmpRdc "Aftrtrtmnt2SCRDsngVlvExhstTmpRdctnRq";
BA_ "SPN" SG_ 2566732798 Aftrtrtmnt2SCRDosingReagentTemp 4390;
BA_ "SigType" SG_ 2566732798 Aftrtrtmnt2SCRDosingReagentTemp 1;
BA_ "SPN" SG_ 2566732798 Aftrtrtmnt2SCRDsngArAssistValve 4389;
BA_ "SigType" SG_ 2566732798 Aftrtrtmnt2SCRDsngArAssistValve 1;
BA_ "SPN" SG_ 2566732798 Aftrtrtmnt2SCRDsngArAssstAbsPrss 4388;
BA_ "SigType" SG_ 2566732798 Aftrtrtmnt2SCRDsngArAssstAbsPrss 1;
BA_ "SPN" SG_ 2364548862 Aftrtrtmnt2SCRDsngRgentAbsPress 4387;
BA_ "SigType" SG_ 2364548862 Aftrtrtmnt2SCRDsngRgentAbsPress 1;
BA_ "SPN" SG_ 2364548862 Aftrtrtmnt2SCRActlRgntQnttyOfInt 4386;
BA_ "SigType" SG_ 2364548862 Aftrtrtmnt2SCRActlRgntQnttyOfInt 1;
BA_ "SystemSignalLongSymbol" SG_ 2364548862 Aftrtrtmnt2SCRActlRgntQnttyOfInt "Aftrtrtmnt2SCRActlRgntQnttyOfIntgrtr";
BA_ "SPN" SG_ 2364548862 Aftertreatment2SCRSystemState 4385;
BA_ "SigType" SG_ 2364548862 Aftertreatment2SCRSystemState 4;
BA_ "SPN" SG_ 2364548862 Aftrtrtmnt2SCRActlDsngRgntQntty 4384;
BA_ "SigType" SG_ 2364548862 Aftrtrtmnt2SCRActlDsngRgntQntty 1;
BA_ "SPN" SG_ 2364549374 Aftrtrtmnt2OtltNH3GsSnsrHtrCtrl 4449;
BA_ "SigType" SG_ 2364549374 Aftrtrtmnt2OtltNH3GsSnsrHtrCtrl 4;
BA_ "SPN" SG_ 2364549374 Aftrtrtmnt2OtltNH3GsSnsrHtrPrlmn 4448;
BA_ "SigType" SG_ 2364549374 Aftrtrtmnt2OtltNH3GsSnsrHtrPrlmn 1;
BA_ "SystemSignalLongSymbol" SG_ 2364549374 Aftrtrtmnt2OtltNH3GsSnsrHtrPrlmn "Aftrtrtmnt2OtltNH3GsSnsrHtrPrlmnryFMI";
BA_ "SPN" SG_ 2364549374 Aftrtrtmnt2OtltNH3GsSnsorAtTemp 4447;
BA_ "SigType" SG_ 2364549374 Aftrtrtmnt2OtltNH3GsSnsorAtTemp 4;
BA_ "SPN" SG_ 2364549374 Aftrtrtmnt2OtltNH3GsSnsrPwrInRng 4446;
BA_ "SigType" SG_ 2364549374 Aftrtrtmnt2OtltNH3GsSnsrPwrInRng 4;
BA_ "SPN" SG_ 2364549374 Aftrtrtmnt2OtltNH3ReadingStable 4445;
BA_ "SigType" SG_ 2364549374 Aftrtrtmnt2OtltNH3ReadingStable 4;
BA_ "SPN" SG_ 2364549374 Aftrtrtmnt2OtltNH3SnsrPrlmnryFMI 4444;
BA_ "SigType" SG_ 2364549374 Aftrtrtmnt2OtltNH3SnsrPrlmnryFMI 1;
BA_ "SPN" SG_ 2364549374 Aftertreatment2OutletNH3 4443;
BA_ "SigType" SG_ 2364549374 Aftertreatment2OutletNH3 1;
BA_ "SPN" SG_ 2566726142 Aftrtrtmnt2GsOxdtnCtlystDffPrssP 4764;
BA_ "SigType" SG_ 2566726142 Aftrtrtmnt2GsOxdtnCtlystDffPrssP 1;
BA_ "SystemSignalLongSymbol" SG_ 2566726142 Aftrtrtmnt2GsOxdtnCtlystDffPrssP "Aftrtrtmnt2GsOxdtnCtlystDffPrssPrlmnryFMI";
BA_ "SPN" SG_ 2566726142 Aftrtrtmnt2GsOxdtnCtlystOtltGsTm 4763;
BA_ "SigType" SG_ 2566726142 Aftrtrtmnt2GsOxdtnCtlystOtltGsTm 1;
BA_ "SystemSignalLongSymbol" SG_ 2566726142 Aftrtrtmnt2GsOxdtnCtlystOtltGsTm "Aftrtrtmnt2GsOxdtnCtlystOtltGsTmpPrlmnryFMI";
BA_ "SPN" SG_ 2566726142 Aftrtrtmnt2GsOxdtnCtlystIntkGsTm 4762;
BA_ "SigType" SG_ 2566726142 Aftrtrtmnt2GsOxdtnCtlystIntkGsTm 1;
BA_ "SystemSignalLongSymbol" SG_ 2566726142 Aftrtrtmnt2GsOxdtnCtlystIntkGsTm "Aftrtrtmnt2GsOxdtnCtlystIntkGsTmpPrlmnryFMI";
BA_ "SPN" SG_ 2566726142 Aftrtrtmnt2GsOxdtnCtlystDffPrss 4761;
BA_ "SigType" SG_ 2566726142 Aftrtrtmnt2GsOxdtnCtlystDffPrss 1;
BA_ "SPN" SG_ 2566726142 Aftrtrtmnt2GsOxdtnCtlystOtl_0000 4760;
BA_ "SigType" SG_ 2566726142 Aftrtrtmnt2GsOxdtnCtlystOtl_0000 1;
BA_ "SystemSignalLongSymbol" SG_ 2566726142 Aftrtrtmnt2GsOxdtnCtlystOtl_0000 "Aftrtrtmnt2GsOxdtnCtlystOtltGsTmp";
BA_ "SPN" SG_ 2566726142 Aftrtrtmnt2GsOxdtnCtlystInt_0000 4759;
BA_ "SigType" SG_ 2566726142 Aftrtrtmnt2GsOxdtnCtlystInt_0000 1;
BA_ "SystemSignalLongSymbol" SG_ 2566726142 Aftrtrtmnt2GsOxdtnCtlystInt_0000 "Aftrtrtmnt2GsOxdtnCtlystIntkGsTmp";
VAL_ 2566844695 ParkBrakeReleaseInhibitRq 3 "Unavailable" 2 "SAEReserved" 1 "ParkBrakeReleaseInhibitRqed" 0 "ParkBrakeReleaseInhibitNotRqed" ;
VAL_ 2566844695 PTOGovernorState 31 "NotAvailable" 20 "11110NotDefined" 19 "PTOSetSpeedMemory2" 18 "PTOSetSpeedMemory1" 17 "PreprogrammedSetSpeed8" 16 "PreprogrammedSetSpeed7" 15 "PreprogrammedSetSpeed6" 14 "PreprogrammedSetSpeed5" 13 "PreprogrammedSetSpeed4" 12 "PreprogrammedSetSpeed3" 11 "PreprogrammedSetSpeed2" 10 "PreprogrammedSetSpeed1" 9 "AccelOverride" 8 "Accelerate" 7 "Resume" 6 "Decelerate_Coast" 5 "Set" 4 "RemoteStandby" 3 "Standby" 2 "RemoteHold" 1 "Hold" 0 "Off_Disabled" ;
VAL_ 2566844695 EngShutdownOverrideSwitch 3 "NotAvailable" 2 "Error" 1 "On" 0 "Off" ;
VAL_ 2566844695 EngTestModeSwitch 3 "NotAvailable" 2 "Error" 1 "On" 0 "Off" ;
VAL_ 2566844695 EngIdleDecrementSwitch 3 "NotAvailable" 2 "Error" 1 "On" 0 "Off" ;
VAL_ 2566844695 EngIdleIncrementSwitch 3 "NotAvailable" 2 "Error" 1 "On" 0 "Off" ;
VAL_ 2566844695 CruiseCtrlStates 7 "NotAvailable" 6 "AccelOverride" 5 "Set" 4 "Resume" 3 "Decelerate" 2 "Accelerate" 1 "Hold" 0 "Off_Disabled" ;
VAL_ 2566844695 CruiseCtrlAccelerateSwitch 3 "NotAvailable" 2 "Error" 1 "CrsCtrlActivatorInPosAccelerate" 0 "CrsCtrlActvtrNotInPosAccelerate" ;
VAL_ 2566844695 CruiseCtrlResumeSwitch 3 "NotAvailable" 2 "Error" 1 "CruiseCtrlActivatorInPosResume" 0 "CrseCtrlActivatorNotInPosResume" ;
VAL_ 2566844695 CruiseCtrlCoastSwitch 3 "NotAvailable" 2 "Error" 1 "CruiseCtrlActivatorInPosCoast" 0 "CriseCtrlActivatorNotInPosCoast" ;
VAL_ 2566844695 CruiseCtrlSetSwitch 3 "NotAvailable" 2 "Error" 1 "CruiseCtrlActivatorInPosSet" 0 "CruiseCtrlActivatorNotInPosSet" ;
VAL_ 2566844695 ClutchSwitch 3 "NotAvailable" 2 "Error" 1 "ClutchPedalDepressed" 0 "ClutchPedalReleased" ;
VAL_ 2566844695 BrakeSwitch 3 "NotAvailable" 2 "Error" 1 "BrakePedalDepressed" 0 "BrakePedalReleased" ;
VAL_ 2566844695 CruiseCtrlEnableSwitch 3 "NotAvailable" 2 "Error" 1 "CruiseCtrlEnabled" 0 "CruiseCtrlDisabled" ;
VAL_ 2566844695 CruiseCtrlActive 3 "NotAvailable" 2 "Error" 1 "CruiseCtrlSwitchedOn" 0 "CruiseCtrlSwitchedOff" ;
VAL_ 2566844695 CruiseCtrlPauseSwitch 3 "TakeNoAction" 2 "ErrorIndicator" 1 "On" 0 "Off" ;
VAL_ 2566844695 ParkingBrakeSwitch 3 "NotAvailable" 2 "Error" 1 "ParkingBrakeSet" 0 "ParkingBrakeNotSet" ;
VAL_ 2566844695 TwoSpeedAxleSwitch 3 "NotAvailable" 2 "Error" 1 "HighSpeedRange" 0 "LowSpeedRange" ;
VAL_ 2566719486 EngFuelFilterRestrictedLampCmd 3 "NotAvailable" 2 "Flash" 1 "LampOn" 0 "LampOff" ;
VAL_ 2566719486 EngAirFilterRestrictionLampCmd 3 "NotAvailable" 2 "Reserved" 1 "LampOn" 0 "LampOff" ;
VAL_ 2566719486 EngIdleManagementActiveLampCmd 3 "NotAvailable" 2 "Reserved" 1 "LampOn" 0 "LampOff" ;
VAL_ 2566719486 EngCoolantLevelLowLampCmd 3 "NotAvailable" 2 "Reserved" 1 "LampOn" 0 "LampOff" ;
VAL_ 2566719486 EngCoolantTempHighLampCmd 3 "NotAvailable" 2 "Reserved" 1 "LampOn" 0 "LampOff" ;
VAL_ 2566719486 EngOilPressLowLampCmd 3 "NotAvailable" 2 "Reserved" 1 "LampOn" 0 "LampOff" ;
VAL_ 2566719486 CmprssnBrkEnblSwtchIndctrLmpCmd 3 "NotAvailable" 2 "Reserved" 1 "LampON" 0 "LampOFF" ;
VAL_ 2566719486 EngBrakeActiveLampCmd 3 "NotAvailable" 2 "Reserved" 1 "LampOn" 0 "LampOff" ;
VAL_ 2566719486 OBDMalfunctionIndicatorLampCmd 3 "NotAvailable" 2 "Reserved" 1 "LampOn" 0 "LampOff" ;
VAL_ 2566719486 EngRedStopLampCmd 3 "NotAvailable" 2 "Reserved" 1 "LampOn" 0 "LampOff" ;
VAL_ 2566719486 EngAmberWarningLampCmd 3 "NotAvailable" 2 "Reserved" 1 "LampOn" 0 "LampOff" ;
VAL_ 2566719486 EngProtectLampCmd 3 "NotAvailable" 2 "Reserved" 1 "LampOn" 0 "LampOff" ;
VAL_ 2633832702 RearCollisionSensor4Type 15 "NotAvailable" 14 "ErrrTypOfSnsrCannotBeDetermined" 8 "1101Reserved" 7 "OpticalSensor" 6 "LidarSensor" 5 "RadarSensor" 4 "FiberopticSensor" 3 "SonicSensor" 2 "RollrateSensor" 1 "PressSensor" 0 "AccelerationSensor" ;
VAL_ 2633832702 RearCollisionSensor3Type 15 "NotAvailable" 14 "ErrrTypOfSnsrCannotBeDetermined" 8 "1101Reserved" 7 "OpticalSensor" 6 "LidarSensor" 5 "RadarSensor" 4 "FiberopticSensor" 3 "SonicSensor" 2 "RollrateSensor" 1 "PressSensor" 0 "AccelerationSensor" ;
VAL_ 2633832702 RearCollisionSensor2Type 15 "NotAvailable" 14 "ErrrTypOfSnsrCannotBeDetermined" 8 "1101Reserved" 7 "OpticalSensor" 6 "LidarSensor" 5 "RadarSensor" 4 "FiberopticSensor" 3 "SonicSensor" 2 "RollrateSensor" 1 "PressSensor" 0 "AccelerationSensor" ;
VAL_ 2633832702 RearCollisionSensor1Type 15 "NotAvailable" 14 "ErrrTypOfSnsrCannotBeDetermined" 8 "1101Reserved" 7 "OpticalSensor" 6 "LidarSensor" 5 "RadarSensor" 4 "FiberopticSensor" 3 "SonicSensor" 2 "RollrateSensor" 1 "PressSensor" 0 "AccelerationSensor" ;
VAL_ 2633832702 SdeCollisionSensorRearRightType 15 "NotAvailable" 14 "ErrrTypOfSnsrCannotBeDetermined" 8 "1101Reserved" 7 "OpticalSensor" 6 "LidarSensor" 5 "RadarSensor" 4 "FiberopticSensor" 3 "SonicSensor" 2 "RollrateSensor" 1 "PressSensor" 0 "AccelerationSensor" ;
VAL_ 2633832702 SdCllsionSensorMidRearRightType 15 "NotAvailable" 14 "ErrrTypOfSnsrCannotBeDetermined" 8 "1101Reserved" 7 "OpticalSensor" 6 "LidarSensor" 5 "RadarSensor" 4 "FiberopticSensor" 3 "SonicSensor" 2 "RollrateSensor" 1 "PressSensor" 0 "AccelerationSensor" ;
VAL_ 2633832702 SdCllsonSensorMidFrontRightType 15 "NotAvailable" 14 "ErrrTypOfSnsrCannotBeDetermined" 8 "1101Reserved" 7 "OpticalSensor" 6 "LidarSensor" 5 "RadarSensor" 4 "FiberopticSensor" 3 "SonicSensor" 2 "RollrateSensor" 1 "PressSensor" 0 "AccelerationSensor" ;
VAL_ 2633832702 SdCollisionSensorFrontRightType 15 "NotAvailable" 14 "ErrrTypOfSnsrCannotBeDetermined" 8 "1101Reserved" 7 "OpticalSensor" 6 "LidarSensor" 5 "RadarSensor" 4 "FiberopticSensor" 3 "SonicSensor" 2 "RollrateSensor" 1 "PressSensor" 0 "AccelerationSensor" ;
VAL_ 2633832702 SideCollisionSensorRearLeftType 15 "NotAvailable" 14 "ErrrTypOfSnsrCannotBeDetermined" 8 "1101Reserved" 7 "OpticalSensor" 6 "LidarSensor" 5 "RadarSensor" 4 "FiberopticSensor" 3 "SonicSensor" 2 "RollrateSensor" 1 "PressSensor" 0 "AccelerationSensor" ;
VAL_ 2633832702 SdCllisionSensorMidRearLeftType 15 "NotAvailable" 14 "ErrrTypOfSnsrCannotBeDetermined" 8 "1101Reserved" 7 "OpticalSensor" 6 "LidarSensor" 5 "RadarSensor" 4 "FiberopticSensor" 3 "SonicSensor" 2 "RollrateSensor" 1 "PressSensor" 0 "AccelerationSensor" ;
VAL_ 2633832702 SdCllsionSensorMidFrontLeftType 15 "NotAvailable" 14 "ErrrTypOfSnsrCannotBeDetermined" 8 "1101Reserved" 7 "OpticalSensor" 6 "LidarSensor" 5 "RadarSensor" 4 "FiberopticSensor" 3 "SonicSensor" 2 "RollrateSensor" 1 "PressSensor" 0 "AccelerationSensor" ;
VAL_ 2633832702 SdeCollisionSensorFrontLeftType 15 "NotAvailable" 14 "ErrrTypOfSnsrCannotBeDetermined" 8 "1101Reserved" 7 "OpticalSensor" 6 "LidarSensor" 5 "RadarSensor" 4 "FiberopticSensor" 3 "SonicSensor" 2 "RollrateSensor" 1 "PressSensor" 0 "AccelerationSensor" ;
VAL_ 2633832702 FrontalCollisionSensor4Type 15 "NotAvailable" 14 "ErrrTypOfSnsrCannotBeDetermined" 8 "1101Reserved" 7 "OpticalSensor" 6 "LidarSensor" 5 "RadarSensor" 4 "FiberopticSensor" 3 "SonicSensor" 2 "RollrateSensor" 1 "PressSensor" 0 "AccelerationSensor" ;
VAL_ 2633832702 FrontalCollisionSensor3Type 15 "NotAvailable" 14 "ErrrTypOfSnsrCannotBeDetermined" 8 "1101Reserved" 7 "OpticalSensor" 6 "LidarSensor" 5 "RadarSensor" 4 "FiberopticSensor" 3 "SonicSensor" 2 "RollrateSensor" 1 "PressSensor" 0 "AccelerationSensor" ;
VAL_ 2633832702 FrontalCollisionSensor2Type 15 "NotAvailable" 14 "ErrrTypOfSnsrCannotBeDetermined" 8 "1101Reserved" 7 "OpticalSensor" 6 "LidarSensor" 5 "RadarSensor" 4 "FiberopticSensor" 3 "SonicSensor" 2 "RollrateSensor" 1 "PressSensor" 0 "AccelerationSensor" ;
VAL_ 2633832702 FrontalCollisionSensor1Type 15 "NotAvailable" 14 "ErrrTypOfSnsrCannotBeDetermined" 8 "1101Reserved" 7 "OpticalSensor" 6 "LidarSensor" 5 "RadarSensor" 4 "FiberopticSensor" 3 "SonicSensor" 2 "RollrateSensor" 1 "PressSensor" 0 "AccelerationSensor" ;
VAL_ 2163223550 CrashType 16 "Rollover" 8 "SideCrash" 2 "RearCrash" 1 "FrontalCrash" ;
VAL_ 2365400830 Joystick9Button9PressedStatus 3 "NotAvailable" 2 "ErrorIndicator" 1 "ButtonPressed" 0 "ButtonNotPressed" ;
VAL_ 2365400830 Joystick9Button10PressedStatus 3 "NotAvailable" 2 "ErrorIndicator" 1 "ButtonPressed" 0 "ButtonNotPressed" ;
VAL_ 2365400830 Joystick9Button11PressedStatus 3 "NotAvailable" 2 "ErrorIndicator" 1 "ButtonPressed" 0 "ButtonNotPressed" ;
VAL_ 2365400830 Joystick9Button12PressedStatus 3 "NotAvailable" 2 "ErrorIndicator" 1 "ButtonPressed" 0 "ButtonNotPressed" ;
VAL_ 2365400830 Joystick9Button5PressedStatus 3 "NotAvailable" 2 "ErrorIndicator" 1 "ButtonPressed" 0 "ButtonNotPressed" ;
VAL_ 2365400830 Joystick9Button6PressedStatus 3 "NotAvailable" 2 "ErrorIndicator" 1 "ButtonPressed" 0 "ButtonNotPressed" ;
VAL_ 2365400830 Joystick9Button7PressedStatus 3 "NotAvailable" 2 "ErrorIndicator" 1 "ButtonPressed" 0 "ButtonNotPressed" ;
VAL_ 2365400830 Joystick9Button8PressedStatus 3 "NotAvailable" 2 "ErrorIndicator" 1 "ButtonPressed" 0 "ButtonNotPressed" ;
VAL_ 2365400830 Joystick9Button1PressedStatus 3 "NotAvailable" 2 "ErrorIndicator" 1 "ButtonPressed" 0 "ButtonNotPressed" ;
VAL_ 2365400830 Joystick9Button2PressedStatus 3 "NotAvailable" 2 "ErrorIndicator" 1 "ButtonPressed" 0 "ButtonNotPressed" ;
VAL_ 2365400830 Joystick9Button3PressedStatus 3 "NotAvailable" 2 "ErrorIndicator" 1 "ButtonPressed" 0 "ButtonNotPressed" ;
VAL_ 2365400830 Joystick9Button4PressedStatus 3 "NotAvailable" 2 "ErrorIndicator" 1 "ButtonPressed" 0 "ButtonNotPressed" ;
VAL_ 2365400830 Joystick9XAxisDetentPosStatus 3 "NotAvailable" 2 "ErrorIndicator" 1 "InDetentPos" 0 "NotInDetentPos" ;
VAL_ 2365400830 Joystick9YAxisDetentPosStatus 3 "NotAvailable" 2 "ErrorIndicator" 1 "InDetentPos" 0 "NotInDetentPos" ;
VAL_ 2365400830 Jystck9YAxsLvrFrwrdPstvPsStatus 3 "NotAvailable" 2 "ErrorIndicator" 1 "OnPositiveSideOfNeutral" 0 "NotOnPositiveSideOfNeutral" ;
VAL_ 2365400830 Jystck9YAxsLvrBckNgtvePosStatus 3 "NotAvailable" 2 "ErrorIndicator" 1 "OnNegativeSideOfNeutral" 0 "NotOnNegativeSideOfNeutral" ;
VAL_ 2365400830 Joystick9YAxisNeutralPosStatus 3 "NotAvailable" 2 "ErrorIndicator" 1 "InNeutralPos" 0 "NotInNeutralPos" ;
VAL_ 2365400830 Jystck9XAxsLvrRghtPstvPosStatus 3 "NotAvailable" 2 "ErrorIndicator" 1 "OnPositiveSideOfNeutral" 0 "NotOnPositiveSideOfNeutral" ;
VAL_ 2365400830 Jystck9XAxsLvrLftNgtvePosStatus 3 "NotAvailable" 2 "ErrorIndicator" 1 "OnNegativeSideOfNeutral" 0 "NotOnNegativeSideOfNeutral" ;
VAL_ 2365400830 Joystick9XAxisNeutralPosStatus 3 "NotAvailable" 2 "ErrorIndicator" 1 "InNeutralPos" 0 "NotInNeutralPos" ;
VAL_ 2365401342 Joystick8Button9PressedStatus 3 "NotAvailable" 2 "ErrorIndicator" 1 "ButtonPressed" 0 "ButtonNotPressed" ;
VAL_ 2365401342 Joystick8Button10PressedStatus 3 "NotAvailable" 2 "ErrorIndicator" 1 "ButtonPressed" 0 "ButtonNotPressed" ;
VAL_ 2365401342 Joystick8Button11PressedStatus 3 "NotAvailable" 2 "ErrorIndicator" 1 "ButtonPressed" 0 "ButtonNotPressed" ;
VAL_ 2365401342 Joystick8Button12PressedStatus 3 "NotAvailable" 2 "ErrorIndicator" 1 "ButtonPressed" 0 "ButtonNotPressed" ;
VAL_ 2365401342 Joystick8Button5PressedStatus 3 "NotAvailable" 2 "ErrorIndicator" 1 "ButtonPressed" 0 "ButtonNotPressed" ;
VAL_ 2365401342 Joystick8Button6PressedStatus 3 "NotAvailable" 2 "ErrorIndicator" 1 "ButtonPressed" 0 "ButtonNotPressed" ;
VAL_ 2365401342 Joystick8Button7PressedStatus 3 "NotAvailable" 2 "ErrorIndicator" 1 "ButtonPressed" 0 "ButtonNotPressed" ;
VAL_ 2365401342 Joystick8Button8PressedStatus 3 "NotAvailable" 2 "ErrorIndicator" 1 "ButtonPressed" 0 "ButtonNotPressed" ;
VAL_ 2365401342 Joystick8Button1PressedStatus 3 "NotAvailable" 2 "ErrorIndicator" 1 "ButtonPressed" 0 "ButtonNotPressed" ;
VAL_ 2365401342 Joystick8Button2PressedStatus 3 "NotAvailable" 2 "ErrorIndicator" 1 "ButtonPressed" 0 "ButtonNotPressed" ;
VAL_ 2365401342 Joystick8Button3PressedStatus 3 "NotAvailable" 2 "ErrorIndicator" 1 "ButtonPressed" 0 "ButtonNotPressed" ;
VAL_ 2365401342 Joystick8Button4PressedStatus 3 "NotAvailable" 2 "ErrorIndicator" 1 "ButtonPressed" 0 "ButtonNotPressed" ;
VAL_ 2365401342 Joystick8XAxisDetentPosStatus 3 "NotAvailable" 2 "ErrorIndicator" 1 "InDetentPos" 0 "NotInDetentPos" ;
VAL_ 2365401342 Joystick8YAxisDetentPosStatus 3 "NotAvailable" 2 "ErrorIndicator" 1 "InDetentPos" 0 "NotInDetentPos" ;
VAL_ 2365401342 Jystck8YAxsLvrFrwrdPstvPsStatus 3 "NotAvailable" 2 "ErrorIndicator" 1 "OnPositiveSideOfNeutral" 0 "NotOnPositiveSideOfNeutral" ;
VAL_ 2365401342 Jystck8YAxsLvrBckNgtvePosStatus 3 "NotAvailable" 2 "ErrorIndicator" 1 "OnNegativeSideOfNeutral" 0 "NotOnNegativeSideOfNeutral" ;
VAL_ 2365401342 Joystick8YAxisNeutralPosStatus 3 "NotAvailable" 2 "ErrorIndicator" 1 "InNeutralPos" 0 "NotInNeutralPos" ;
VAL_ 2365401342 Jystck8XAxsLvrRghtPstvPosStatus 3 "NotAvailable" 2 "ErrorIndicator" 1 "OnPositiveSideOfNeutral" 0 "NotOnPositiveSideOfNeutral" ;
VAL_ 2365401342 Jystck8XAxsLvrLftNgtvePosStatus 3 "NotAvailable" 2 "ErrorIndicator" 1 "OnNegativeSideOfNeutral" 0 "NotOnNegativeSideOfNeutral" ;
VAL_ 2365401342 Joystick8XAxisNeutralPosStatus 3 "NotAvailable" 2 "ErrorIndicator" 1 "InNeutralPos" 0 "NotInNeutralPos" ;
VAL_ 2365401854 Joystick7Button9PressedStatus 3 "NotAvailable" 2 "ErrorIndicator" 1 "ButtonPressed" 0 "ButtonNotPressed" ;
VAL_ 2365401854 Joystick7Button10PressedStatus 3 "NotAvailable" 2 "ErrorIndicator" 1 "ButtonPressed" 0 "ButtonNotPressed" ;
VAL_ 2365401854 Joystick7Button11PressedStatus 3 "NotAvailable" 2 "ErrorIndicator" 1 "ButtonPressed" 0 "ButtonNotPressed" ;
VAL_ 2365401854 Joystick7Button12PressedStatus 3 "NotAvailable" 2 "ErrorIndicator" 1 "ButtonPressed" 0 "ButtonNotPressed" ;
VAL_ 2365401854 Joystick7Button5PressedStatus 3 "NotAvailable" 2 "ErrorIndicator" 1 "ButtonPressed" 0 "ButtonNotPressed" ;
VAL_ 2365401854 Joystick7Button6PressedStatus 3 "NotAvailable" 2 "ErrorIndicator" 1 "ButtonPressed" 0 "ButtonNotPressed" ;
VAL_ 2365401854 Joystick7Button7PressedStatus 3 "NotAvailable" 2 "ErrorIndicator" 1 "ButtonPressed" 0 "ButtonNotPressed" ;
VAL_ 2365401854 Joystick7Button8PressedStatus 3 "NotAvailable" 2 "ErrorIndicator" 1 "ButtonPressed" 0 "ButtonNotPressed" ;
VAL_ 2365401854 Joystick7Button1PressedStatus 3 "NotAvailable" 2 "ErrorIndicator" 1 "ButtonPressed" 0 "ButtonNotPressed" ;
VAL_ 2365401854 Joystick7Button2PressedStatus 3 "NotAvailable" 2 "ErrorIndicator" 1 "ButtonPressed" 0 "ButtonNotPressed" ;
VAL_ 2365401854 Joystick7Button3PressedStatus 3 "NotAvailable" 2 "ErrorIndicator" 1 "ButtonPressed" 0 "ButtonNotPressed" ;
VAL_ 2365401854 Joystick7Button4PressedStatus 3 "NotAvailable" 2 "ErrorIndicator" 1 "ButtonPressed" 0 "ButtonNotPressed" ;
VAL_ 2365401854 Joystick7XAxisDetentPosStatus 3 "NotAvailable" 2 "ErrorIndicator" 1 "InDetentPos" 0 "NotInDetentPos" ;
VAL_ 2365401854 Joystick7YAxisDetentPosStatus 3 "NotAvailable" 2 "ErrorIndicator" 1 "InDetentPos" 0 "NotInDetentPos" ;
VAL_ 2365401854 Jystck7YAxsLvrFrwrdPstvPsStatus 3 "NotAvailable" 2 "ErrorIndicator" 1 "OnPositiveSideOfNeutral" 0 "NotOnPositiveSideOfNeutral" ;
VAL_ 2365401854 Jystck7YAxsLvrBckNgtvePosStatus 3 "NotAvailable" 2 "ErrorIndicator" 1 "OnNegativeSideOfNeutral" 0 "NotOnNegativeSideOfNeutral" ;
VAL_ 2365401854 Joystick7YAxisNeutralPosStatus 3 "NotAvailable" 2 "ErrorIndicator" 1 "InNeutralPos" 0 "NotInNeutralPos" ;
VAL_ 2365401854 Jystck7XAxsLvrRghtPstvPosStatus 3 "NotAvailable" 2 "ErrorIndicator" 1 "OnPositiveSideOfNeutral" 0 "NotOnPositiveSideOfNeutral" ;
VAL_ 2365401854 Jystck7XAxsLvrLftNgtvePosStatus 3 "NotAvailable" 2 "ErrorIndicator" 1 "OnNegativeSideOfNeutral" 0 "NotOnNegativeSideOfNeutral" ;
VAL_ 2365401854 Joystick7XAxisNeutralPosStatus 3 "NotAvailable" 2 "ErrorIndicator" 1 "InNeutralPos" 0 "NotInNeutralPos" ;
VAL_ 2365402366 Joystick6Button9PressedStatus 3 "NotAvailable" 2 "ErrorIndicator" 1 "ButtonPressed" 0 "ButtonNotPressed" ;
VAL_ 2365402366 Joystick6Button10PressedStatus 3 "NotAvailable" 2 "ErrorIndicator" 1 "ButtonPressed" 0 "ButtonNotPressed" ;
VAL_ 2365402366 Joystick6Button11PressedStatus 3 "NotAvailable" 2 "ErrorIndicator" 1 "ButtonPressed" 0 "ButtonNotPressed" ;
VAL_ 2365402366 Joystick6Button12PressedStatus 3 "NotAvailable" 2 "ErrorIndicator" 1 "ButtonPressed" 0 "ButtonNotPressed" ;
VAL_ 2365402366 Joystick6Button5PressedStatus 3 "NotAvailable" 2 "ErrorIndicator" 1 "ButtonPressed" 0 "ButtonNotPressed" ;
VAL_ 2365402366 Joystick6Button6PressedStatus 3 "NotAvailable" 2 "ErrorIndicator" 1 "ButtonPressed" 0 "ButtonNotPressed" ;
VAL_ 2365402366 Joystick6Button7PressedStatus 3 "NotAvailable" 2 "ErrorIndicator" 1 "ButtonPressed" 0 "ButtonNotPressed" ;
VAL_ 2365402366 Joystick6Button8PressedStatus 3 "NotAvailable" 2 "ErrorIndicator" 1 "ButtonPressed" 0 "ButtonNotPressed" ;
VAL_ 2365402366 Joystick6Button1PressedStatus 3 "NotAvailable" 2 "ErrorIndicator" 1 "ButtonPressed" 0 "ButtonNotPressed" ;
VAL_ 2365402366 Joystick6Button2PressedStatus 3 "NotAvailable" 2 "ErrorIndicator" 1 "ButtonPressed" 0 "ButtonNotPressed" ;
VAL_ 2365402366 Joystick6Button3PressedStatus 3 "NotAvailable" 2 "ErrorIndicator" 1 "ButtonPressed" 0 "ButtonNotPressed" ;
VAL_ 2365402366 Joystick6Button4PressedStatus 3 "NotAvailable" 2 "ErrorIndicator" 1 "ButtonPressed" 0 "ButtonNotPressed" ;
VAL_ 2365402366 Joystick6XAxisDetentPosStatus 3 "NotAvailable" 2 "ErrorIndicator" 1 "InDetentPos" 0 "NotInDetentPos" ;
VAL_ 2365402366 Joystick6YAxisDetentPosStatus 3 "NotAvailable" 2 "ErrorIndicator" 1 "InDetentPos" 0 "NotInDetentPos" ;
VAL_ 2365402366 Jystck6YAxsLvrFrwrdPstvPsStatus 3 "NotAvailable" 2 "ErrorIndicator" 1 "OnPositiveSideOfNeutral" 0 "NotOnPositiveSideOfNeutral" ;
VAL_ 2365402366 Jystck6YAxsLvrBckNgtvePosStatus 3 "NotAvailable" 2 "ErrorIndicator" 1 "OnNegativeSideOfNeutral" 0 "NotOnNegativeSideOfNeutral" ;
VAL_ 2365402366 Joystick6YAxisNeutralPosStatus 3 "NotAvailable" 2 "ErrorIndicator" 1 "InNeutralPos" 0 "NotInNeutralPos" ;
VAL_ 2365402366 Jystck6XAxsLvrRghtPstvPosStatus 3 "NotAvailable" 2 "ErrorIndicator" 1 "OnPositiveSideOfNeutral" 0 "NotOnPositiveSideOfNeutral" ;
VAL_ 2365402366 Jystck6XAxsLvrLftNgtvePosStatus 3 "NotAvailable" 2 "ErrorIndicator" 1 "OnNegativeSideOfNeutral" 0 "NotOnNegativeSideOfNeutral" ;
VAL_ 2365402366 Joystick6XAxisNeutralPosStatus 3 "NotAvailable" 2 "ErrorIndicator" 1 "InNeutralPos" 0 "NotInNeutralPos" ;
VAL_ 2365402878 Joystick5Button9PressedStatus 3 "NotAvailable" 2 "ErrorIndicator" 1 "ButtonPressed" 0 "ButtonNotPressed" ;
VAL_ 2365402878 Joystick5Button10PressedStatus 3 "NotAvailable" 2 "ErrorIndicator" 1 "ButtonPressed" 0 "ButtonNotPressed" ;
VAL_ 2365402878 Joystick5Button11PressedStatus 3 "NotAvailable" 2 "ErrorIndicator" 1 "ButtonPressed" 0 "ButtonNotPressed" ;
VAL_ 2365402878 Joystick5Button12PressedStatus 3 "NotAvailable" 2 "ErrorIndicator" 1 "ButtonPressed" 0 "ButtonNotPressed" ;
VAL_ 2365402878 Joystick5Button5PressedStatus 3 "NotAvailable" 2 "ErrorIndicator" 1 "ButtonPressed" 0 "ButtonNotPressed" ;
VAL_ 2365402878 Joystick5Button6PressedStatus 3 "NotAvailable" 2 "ErrorIndicator" 1 "ButtonPressed" 0 "ButtonNotPressed" ;
VAL_ 2365402878 Joystick5Button7PressedStatus 3 "NotAvailable" 2 "ErrorIndicator" 1 "ButtonPressed" 0 "ButtonNotPressed" ;
VAL_ 2365402878 Joystick5Button8PressedStatus 3 "NotAvailable" 2 "ErrorIndicator" 1 "ButtonPressed" 0 "ButtonNotPressed" ;
VAL_ 2365402878 Joystick5Button1PressedStatus 3 "NotAvailable" 2 "ErrorIndicator" 1 "ButtonPressed" 0 "ButtonNotPressed" ;
VAL_ 2365402878 Joystick5Button2PressedStatus 3 "NotAvailable" 2 "ErrorIndicator" 1 "ButtonPressed" 0 "ButtonNotPressed" ;
VAL_ 2365402878 Joystick5Button3PressedStatus 3 "NotAvailable" 2 "ErrorIndicator" 1 "ButtonPressed" 0 "ButtonNotPressed" ;
VAL_ 2365402878 Joystick5Button4PressedStatus 3 "NotAvailable" 2 "ErrorIndicator" 1 "ButtonPressed" 0 "ButtonNotPressed" ;
VAL_ 2365402878 Joystick5XAxisDetentPosStatus 3 "NotAvailable" 2 "ErrorIndicator" 1 "InDetentPos" 0 "NotInDetentPos" ;
VAL_ 2365402878 Joystick5YAxisDetentPosStatus 3 "NotAvailable" 2 "ErrorIndicator" 1 "InDetentPos" 0 "NotInDetentPos" ;
VAL_ 2365402878 Jystck5YAxsLvrFrwrdPstvPsStatus 3 "NotAvailable" 2 "ErrorIndicator" 1 "OnPositiveSideOfNeutral" 0 "NotOnPositiveSideOfNeutral" ;
VAL_ 2365402878 Jystck5YAxsLvrBckNgtvePosStatus 3 "NotAvailable" 2 "ErrorIndicator" 1 "OnNegativeSideOfNeutral" 0 "NotOnNegativeSideOfNeutral" ;
VAL_ 2365402878 Joystick5YAxisNeutralPosStatus 3 "NotAvailable" 2 "ErrorIndicator" 1 "InNeutralPos" 0 "NotInNeutralPos" ;
VAL_ 2365402878 Jystck5XAxsLvrRghtPstvPosStatus 3 "NotAvailable" 2 "ErrorIndicator" 1 "OnPositiveSideOfNeutral" 0 "NotOnPositiveSideOfNeutral" ;
VAL_ 2365402878 Jystck5XAxsLvrLftNgtvePosStatus 3 "NotAvailable" 2 "ErrorIndicator" 1 "OnNegativeSideOfNeutral" 0 "NotOnNegativeSideOfNeutral" ;
VAL_ 2365402878 Joystick5XAxisNeutralPosStatus 3 "NotAvailable" 2 "ErrorIndicator" 1 "InNeutralPos" 0 "NotInNeutralPos" ;
VAL_ 2365403390 Joystick4Button9PressedStatus 3 "NotAvailable" 2 "ErrorIndicator" 1 "ButtonPressed" 0 "ButtonNotPressed" ;
VAL_ 2365403390 Joystick4Button10PressedStatus 3 "NotAvailable" 2 "ErrorIndicator" 1 "ButtonPressed" 0 "ButtonNotPressed" ;
VAL_ 2365403390 Joystick4Button11PressedStatus 3 "NotAvailable" 2 "ErrorIndicator" 1 "ButtonPressed" 0 "ButtonNotPressed" ;
VAL_ 2365403390 Joystick4Button12PressedStatus 3 "NotAvailable" 2 "ErrorIndicator" 1 "ButtonPressed" 0 "ButtonNotPressed" ;
VAL_ 2365403390 Joystick4Button5PressedStatus 3 "NotAvailable" 2 "ErrorIndicator" 1 "ButtonPressed" 0 "ButtonNotPressed" ;
VAL_ 2365403390 Joystick4Button6PressedStatus 3 "NotAvailable" 2 "ErrorIndicator" 1 "ButtonPressed" 0 "ButtonNotPressed" ;
VAL_ 2365403390 Joystick4Button7PressedStatus 3 "NotAvailable" 2 "ErrorIndicator" 1 "ButtonPressed" 0 "ButtonNotPressed" ;
VAL_ 2365403390 Joystick4Button8PressedStatus 3 "NotAvailable" 2 "ErrorIndicator" 1 "ButtonPressed" 0 "ButtonNotPressed" ;
VAL_ 2365403390 Joystick4Button1PressedStatus 3 "NotAvailable" 2 "ErrorIndicator" 1 "ButtonPressed" 0 "ButtonNotPressed" ;
VAL_ 2365403390 Joystick4Button2PressedStatus 3 "NotAvailable" 2 "ErrorIndicator" 1 "ButtonPressed" 0 "ButtonNotPressed" ;
VAL_ 2365403390 Joystick4Button3PressedStatus 3 "NotAvailable" 2 "ErrorIndicator" 1 "ButtonPressed" 0 "ButtonNotPressed" ;
VAL_ 2365403390 Joystick4Button4PressedStatus 3 "NotAvailable" 2 "ErrorIndicator" 1 "ButtonPressed" 0 "ButtonNotPressed" ;
VAL_ 2365403390 Joystick4XAxisDetentPosStatus 3 "NotAvailable" 2 "ErrorIndicator" 1 "InDetentPos" 0 "NotInDetentPos" ;
VAL_ 2365403390 Joystick4YAxisDetentPosStatus 3 "NotAvailable" 2 "ErrorIndicator" 1 "InDetentPos" 0 "NotInDetentPos" ;
VAL_ 2365403390 Jystck4YAxsLvrFrwrdPstvPsStatus 3 "NotAvailable" 2 "ErrorIndicator" 1 "OnPositiveSideOfNeutral" 0 "NotOnPositiveSideOfNeutral" ;
VAL_ 2365403390 Jystck4YAxsLvrBckNgtvePosStatus 3 "NotAvailable" 2 "ErrorIndicator" 1 "OnNegativeSideOfNeutral" 0 "NotOnNegativeSideOfNeutral" ;
VAL_ 2365403390 Joystick4YAxisNeutralPosStatus 3 "NotAvailable" 2 "ErrorIndicator" 1 "InNeutralPos" 0 "NotInNeutralPos" ;
VAL_ 2365403390 Jystck4XAxsLvrRghtPstvPosStatus 3 "NotAvailable" 2 "ErrorIndicator" 1 "OnPositiveSideOfNeutral" 0 "NotOnPositiveSideOfNeutral" ;
VAL_ 2365403390 Jystck4XAxsLvrLftNgtvePosStatus 3 "NotAvailable" 2 "ErrorIndicator" 1 "OnNegativeSideOfNeutral" 0 "NotOnNegativeSideOfNeutral" ;
VAL_ 2365403390 Joystick4XAxisNeutralPosStatus 3 "NotAvailable" 2 "ErrorIndicator" 1 "InNeutralPos" 0 "NotInNeutralPos" ;
VAL_ 2365400318 Joystick10Button9PressedStatus 3 "NotAvailable" 2 "ErrorIndicator" 1 "ButtonPressed" 0 "ButtonNotPressed" ;
VAL_ 2365400318 Joystick10Button10PressedStatus 3 "NotAvailable" 2 "ErrorIndicator" 1 "ButtonPressed" 0 "ButtonNotPressed" ;
VAL_ 2365400318 Joystick10Button11PressedStatus 3 "NotAvailable" 2 "ErrorIndicator" 1 "ButtonPressed" 0 "ButtonNotPressed" ;
VAL_ 2365400318 Joystick10Button12PressedStatus 3 "NotAvailable" 2 "ErrorIndicator" 1 "ButtonPressed" 0 "ButtonNotPressed" ;
VAL_ 2365400318 Joystick10Button5PressedStatus 3 "NotAvailable" 2 "ErrorIndicator" 1 "ButtonPressed" 0 "ButtonNotPressed" ;
VAL_ 2365400318 Joystick10Button6PressedStatus 3 "NotAvailable" 2 "ErrorIndicator" 1 "ButtonPressed" 0 "ButtonNotPressed" ;
VAL_ 2365400318 Joystick10Button7PressedStatus 3 "NotAvailable" 2 "ErrorIndicator" 1 "ButtonPressed" 0 "ButtonNotPressed" ;
VAL_ 2365400318 Joystick10Button8PressedStatus 3 "NotAvailable" 2 "ErrorIndicator" 1 "ButtonPressed" 0 "ButtonNotPressed" ;
VAL_ 2365400318 Joystick10Button1PressedStatus 3 "NotAvailable" 2 "ErrorIndicator" 1 "ButtonPressed" 0 "ButtonNotPressed" ;
VAL_ 2365400318 Joystick10Button2PressedStatus 3 "NotAvailable" 2 "ErrorIndicator" 1 "ButtonPressed" 0 "ButtonNotPressed" ;
VAL_ 2365400318 Joystick10Button3PressedStatus 3 "NotAvailable" 2 "ErrorIndicator" 1 "ButtonPressed" 0 "ButtonNotPressed" ;
VAL_ 2365400318 Joystick10Button4PressedStatus 3 "NotAvailable" 2 "ErrorIndicator" 1 "ButtonPressed" 0 "ButtonNotPressed" ;
VAL_ 2365400318 Joystick10XAxisDetentPosStatus 3 "NotAvailable" 2 "ErrorIndicator" 1 "InDetentPos" 0 "NotInDetentPos" ;
VAL_ 2365400318 Joystick10YAxisDetentPosStatus 3 "NotAvailable" 2 "ErrorIndicator" 1 "InDetentPos" 0 "NotInDetentPos" ;
VAL_ 2365400318 Jystck10YAxsLvrFrwrdPstvPsSttus 3 "NotAvailable" 2 "ErrorIndicator" 1 "OnPositiveSideOfNeutral" 0 "NotOnPositiveSideOfNeutral" ;
VAL_ 2365400318 Jystck10YAxsLvrBckNgtvPosStatus 3 "NotAvailable" 2 "ErrorIndicator" 1 "OnNegativeSideOfNeutral" 0 "NotOnNegativeSideOfNeutral" ;
VAL_ 2365400318 Joystick10YAxisNeutralPosStatus 3 "NotAvailable" 2 "ErrorIndicator" 1 "InNeutralPos" 0 "NotInNeutralPos" ;
VAL_ 2365400318 Jystck10XAxsLvrRghtPstvPsStatus 3 "NotAvailable" 2 "ErrorIndicator" 1 "OnPositiveSideOfNeutral" 0 "NotOnPositiveSideOfNeutral" ;
VAL_ 2365400318 Jystck10XAxsLvrLftNgtvPosStatus 3 "NotAvailable" 2 "ErrorIndicator" 1 "OnNegativeSideOfNeutral" 0 "NotOnNegativeSideOfNeutral" ;
VAL_ 2365400318 Joystick10XAxisNeutralPosStatus 3 "NotAvailable" 2 "ErrorIndicator" 1 "InNeutralPos" 0 "NotInNeutralPos" ;
VAL_ 2499614718 PssngrArbgDctvationSwitchStatus 3 "NotAvailable" 2 "ErrrSttOfDctvtnSwtchCnntBDtrmnd" 1 "PassengerAirbagDeactivated" 0 "PassengerAirbagActivated" ;
VAL_ 2499614718 Beltlock10Status 3 "NotAvailable" 2 "ErrrBltlckSttCannotBeDetermined" 1 "Locked" 0 "Unlocked" ;
VAL_ 2499614718 Beltlock9Status 3 "NotAvailable" 2 "ErrrBltlckSttCannotBeDetermined" 1 "Locked" 0 "Unlocked" ;
VAL_ 2499614718 Beltlock8Status 3 "NotAvailable" 2 "ErrrBltlckSttCannotBeDetermined" 1 "Locked" 0 "Unlocked" ;
VAL_ 2499614718 Beltlock7Status 3 "NotAvailable" 2 "ErrrBltlckSttCannotBeDetermined" 1 "Locked" 0 "Unlocked" ;
VAL_ 2499614718 Beltlock6Status 3 "NotAvailable" 2 "ErrrBltlckSttCannotBeDetermined" 1 "Locked" 0 "Unlocked" ;
VAL_ 2499614718 Beltlock5Status 3 "NotAvailable" 2 "ErrrBltlckSttCannotBeDetermined" 1 "Locked" 0 "Unlocked" ;
VAL_ 2499614718 Beltlock4Status 3 "NotAvailable" 2 "ErrrBltlckSttCannotBeDetermined" 1 "Locked" 0 "Unlocked" ;
VAL_ 2499614718 Beltlock3Status 3 "NotAvailable" 2 "ErrrBltlckSttCannotBeDetermined" 1 "Locked" 0 "Unlocked" ;
VAL_ 2499614718 PassengerBeltlockStatus 3 "NotAvailable" 2 "ErrrBltlckSttCannotBeDetermined" 1 "Locked" 0 "Unlocked" ;
VAL_ 2499614718 DriverBeltlockStatus 3 "NotAvailable" 2 "ErrrBltlckSttCannotBeDetermined" 1 "Locked" 0 "Unlocked" ;
VAL_ 2566722814 BatteryCharger2PowerLineState 1 "CnnctdPwrLnIsCnnctdToTheCharger" 0 "DscnnctdPwrLnIsDscnnctdFrmThChr" ;
VAL_ 2566722814 BatteryCharger2State 1 "ChargingBattery" 0 "IdlngPwrLnThBttryIsDscnnctdFrmT" ;
VAL_ 2566723070 BatteryCharger1PowerLineState 1 "CnnctdPwrLnIsCnnctdToTheCharger" 0 "DscnnctdPwrLnIsDscnnctdFrmThChr" ;
VAL_ 2566723070 BatteryCharger1State 1 "ChargingBattery" 0 "IdlngPwrLnThBttryIsDscnnctdFrmT" ;
VAL_ 2566735102 Aftertreatment2FuelPress2Ctrl 4 "fullyOpen" ;
VAL_ 2566735102 Aftrtrtmnt2FlFlwDvrterValveCtrl 3 "notAvailable" 2 "reservedForSAEAssignment" 1 "on" 0 "off" ;
VAL_ 2566735102 Aftrtreatment2FuelPumpRelayCtrl 3 "notAvailable" 2 "reservedForSAEAssignment" 1 "on" 0 "off" ;
VAL_ 2566805246 AftrtrtmntSCROprtrIndcmntSvrity 7 "NotAvailable_NotSupported" 6 "Reserved" 5 "InducementLevel5" 4 "InducementLevel4" 3 "InducementLevel3" 2 "InducementLevel2" 1 "InducementLevel1" 0 "NoInducementActive" ;
VAL_ 2566805246 Aftrtrtmnt1DEFTnkLwLvlIndicator 7 "notAvailable" 4 "OnFastBlink" 6 "reservedForSAEAssignment" 1 "OnSolid" 0 "Off" ;
VAL_ 2566805246 Aftrtrtmnt1SCRCatalystTankLevel 4 "Full" 0 "Empty" ;
VAL_ 2566804992 AftrtrtmntSCROprtrIndcmntSvrity 7 "NotAvailable_NotSupported" 6 "Reserved" 5 "InducementLevel5" 4 "InducementLevel4" 3 "InducementLevel3" 2 "InducementLevel2" 1 "InducementLevel1" 0 "NoInducementActive" ;
VAL_ 2566804992 Aftrtrtmnt1DEFTnkLwLvlIndicator 7 "notAvailable" 4 "OnFastBlink" 6 "reservedForSAEAssignment" 1 "OnSolid" 0 "Off" ;
VAL_ 2566804992 Aftrtrtmnt1SCRCatalystTankLevel 4 "Full" 0 "Empty" ;
VAL_ 2566711806 ArmrestSwitchMatrix2Switch2 3 "DontCare_TakeNoAction" 2 "Reserved" 1 "On" 0 "Off" ;
VAL_ 2566711806 ArmrestSwitchMatrix2Switch1 3 "DontCare_TakeNoAction" 2 "Reserved" 1 "On" 0 "Off" ;
VAL_ 2566711806 ArmrestSwitchMatrixSwitch2 3 "DontCare_TakeNoAction" 2 "Reserved" 1 "On" 0 "Off" ;
VAL_ 2566711806 ArmrestSwitchMatrixSwitch1 3 "DontCare_TakeNoAction" 2 "Reserved" 1 "On" 0 "Off" ;
VAL_ 2364549886 YawRateExRangeFigureOfMerit 3 "NotAvailable" 2 "Error" 1 "YwRtDgrddDtIsSspctDTEnvrnmntlCn" 0 "YwRtFllyFnctnlDtIsWthnSnsrSpcfc" ;
VAL_ 2364549886 RollRateExRangeFigureOfMerit 3 "NotAvailable" 2 "Error" 1 "RllRtDgrddDtIsSspctDTEnvrnmntlC" 0 "RllRtFllyFnctnlDtIsWthnSnsrSpcf" ;
VAL_ 2364549886 PitchRateExRangeFigureOfMerit 3 "NotAvailable" 2 "Error" 1 "PtchRtDgrddDtIsSspctDTEnvrnmntl" 0 "PtchRtFllyFnctnlDtIsWthnSnsrSpc" ;
VAL_ 2566712318 Aftrtrtmnt2NOxAdsrbrDSOxRgnrtnSt 3 "NotAvailable" 2 "ErrorIndicator" 1 "Active" 0 "Inactive" ;
VAL_ 2566712318 Aftrtrtmnt2NOxAdsrbrDNOxRgnrtnSt 3 "NotAvailable" 2 "ErrorIndicator" 1 "Active" 0 "Inactive" ;
VAL_ 2566712574 Aftrtrtmnt1NOxAdsrbrDSOxRgnrtnSt 3 "NotAvailable" 2 "ErrorIndicator" 1 "Active" 0 "Inactive" ;
VAL_ 2566712574 Aftrtrtmnt1NOxAdsrbrDNOxRgnrtnSt 3 "NotAvailable" 2 "ErrorIndicator" 1 "Active" 0 "Inactive" ;
VAL_ 2566731262 Aftrtrtmnt2SCRCatalystTankLevel 4 "Full" 0 "Empty" ;
VAL_ 2566730750 Aftrtrtmnt2SCRCtlystRgntPmpStte 3 "notAvailable" 2 "reservedForSAEAssignment" 1 "pumpError" 0 "pumpOperational" ;
VAL_ 2566731518 Aftrtrtmnt2SCRCtlystReagentType 15 "NotAvailable" 14 "ErrrDtctdWthUrRgntTypeDetection" 13 "NtAblTDtrmneCatalystReagentType" 5 "to1100ReservedForSAEAssignment" 3 "CatalystReagentIsProperMixture" 2 "CatalystReagentIsDiesel" 1 "CtlystRgntIsUrCncntrationTooLow" 0 "CtlystRgntIsUrCncntrtionTooHigh" ;
VAL_ 2164079358 Aftrtrtmnt2SCRCtlystRgntLnHter4 3 "notAvailable" 2 "rservedForFutureAssignmentBySAE" 1 "RqForHeaterToBeActive" 0 "RqForHeaterToBeInactive" ;
VAL_ 2164079358 Aftrtrtmnt2SCRCtlystRgntLnHter3 3 "notAvailable" 2 "rservedForFutureAssignmentBySAE" 1 "RqForHeaterToBeActive" 0 "RqForHeaterToBeInactive" ;
VAL_ 2164079358 Aftrtrtmnt2SCRCtlystRgntLnHter2 3 "notAvailable" 2 "rservedForFutureAssignmentBySAE" 1 "RqForHeaterToBeActive" 0 "RqForHeaterToBeInactive" ;
VAL_ 2164079358 Aftrtrtmnt2SCRCtlystRgntLnHter1 3 "notAvailable" 2 "rservedForFutureAssignmentBySAE" 1 "RqForHeaterToBeActive" 0 "RqForHeaterToBeInactive" ;
VAL_ 2164079358 Aftrtrtmnt2SCRDserHeatingModeRq 7 "NotAvailable" 4 "110Reserved" 3 "HeaterOn" 2 "HeaterAutomaticMode" 1 "HeaterEconomyMode" 0 "HeaterOff" ;
VAL_ 2164079358 Aftrtrtmnt2SCRDsrFltSpprssionRq 3 "NotAvailable" 2 "Reserved" 1 "ErrorSuppressionOn" 0 "ErrorSuppressionOff" ;
VAL_ 2364549118 Aftrtratment2SCRSystemRqedState 15 "NotAvailable" 14 "Error" 11 "1101RsrvdFrFtureAssignmentBySAE" 10 "ServiceTestModeDosingNotAllowed" 9 "ServiceTestModeDosingAllowed" 8 "Diagnosis" 7 "Shutoff" 6 "ProtectModeAgainstCold" 5 "ProtectModeAgainstHeat" 4 "RservedForFutureAssignmentBySAE" 3 "SystemErrorPending" 2 "NormalDosingOperation" 1 "PreparingDosingReadiness" 0 "Dormant" ;
VAL_ 2566732798 Aftrtrtmnt2SCRCtlystRgntLnHtr4St 3 "notAvailable" 2 "error" 1 "heaterActive" 0 "heaterInactive" ;
VAL_ 2566732798 Aftrtrtmnt2SCRCtlystRgntLnHtr3St 3 "notAvailable" 2 "error" 1 "heaterActive" 0 "heaterInactive" ;
VAL_ 2566732798 Aftrtrtmnt2SCRCtlystRgntLnHtr2St 3 "notAvailable" 2 "error" 1 "heaterActive" 0 "heaterInactive" ;
VAL_ 2566732798 Aftrtrtmnt2SCRCtlystRgntLnHtr1St 3 "notAvailable" 2 "error" 1 "heaterActive" 0 "heaterInactive" ;
VAL_ 2566732798 Aftrtrtmnt2SCRFedbackCtrlStatus 7 "notAvailable" 6 "error" 5 "rservedForFutureAssignmentBySAE" 1 "closedLoopCtrlActive" 0 "openLoopCtrlActive" ;
VAL_ 2566732798 Aftrtrtmnt2SCRDsngVlvExhstTmpRdc 7 "NotAvailable" 6 "Error" 5 "RservedForFutureAssignmentBySAE" 2 "ReductionRqStage2" 1 "ReductionRqStage1" 0 "NoRq" ;
VAL_ 2364548862 Aftertreatment2SCRSystemState 15 "NotAvailable" 14 "Error" 11 "1101RsrvdFrFtureAssignmentBySAE" 10 "ServiceTestModeDosingNotAllowed" 9 "ServiceTestModeDosingAllowed" 8 "Diagnosis" 7 "Shutoff" 6 "ProtectModeAgainstCold" 5 "ProtectModeAgainstHeat" 4 "RservedForFutureAssignmentBySAE" 3 "SystemErrorPending" 2 "NormalDosingOperation" 1 "PreparingDosingReadiness" 0 "Dormant" ;
VAL_ 2364549374 Aftrtrtmnt2OtltNH3GsSnsrHtrCtrl 3 "HeaterOffNotAvailable" 2 "Preheat1" 1 "Preheat2" 0 "Automatic" ;
